VERSION ""

NS_ :

BS_:

BU_: PowertrainControlModule AtmosphericSensor SafetyRestraintSystem2 Aftertreatment_2_GasOutlet Aftertreatment_2_GasIntake DieselParticulateFilterControl Turbocharger SafetyRestraintSystem1 CabDisplay2 Aftertreatment_1_GasOutlet Aftertreatment_1_GasIntake OnBoardDataLogger OffBoardDiagnosticTool2 OffBoardDiagnosticTool1 FileServer ParkingBrakeController SeatController2 FanDriveController SteeringColumnUnit CommunicationUnitRadio CommunicationUnitSatellite CommunicationUnitCellular PropulsionBatteryCharger ChassisController2 ChassisController1 EngineValveControl AuxiliaryHeater2 AuxiliaryHeater1 ClutchUnit RampControl InformationSystem1 SuspensionSystemController2 OilSensor VehicleDynamicStability ExhaustEmissionController TransmissionDisplay2 TransmissionDisplay1 ClimateControl2 WaterPumpController RearAxleSteeringController LightingOperatorControl SeatController1 IgnitionController2 IgnitionController1 TirePressureController CabController2 CabController1 PneumaticSystemController SuspensionSystemController1 HydraulicPumpController EnduranceBrakingSystem RetarderExhaustEngine2 OnBoardDiagnosticUnit HeadwayController RetarderExhaustEngine1 CabDisplay1 ManagementComputer VirtualTerminal OffVehicleGateway PowerTakeOffFront HitchControl AuxiliaryValveControl BodyController TractorTrailerBridge1 StarterSystem ElectricalSystem VehicleSecurity VehicleNavigation AerodynamicControl ElectricalChargingSystem ClimateControl1 TripRecorder InstrumentCluster SuspensionDriveAxle2 SuspensionDriveAxle1 SuspensionSteerAxle SteeringController FuelSystem CruiseControl RetarderDriveline RetarderEngine BrakesDriveAxle2 BrakesDriveAxle1 BrakesSystemController BrakesSteerAxle AxleDrive2 AxleDrive1 AxleSteering PowerTakeOff ShiftConsoleSecondary ShiftConsolePrimary Transmission2 Transmission1 Engine2 Engine1

BO_ 2566711550 IVAC: 8 Vector__XXX
 SG_ IntkVlvActtnSystmOlPrss2SlndCtrl : 2|2@1+ (1,0) [0|3] "" Vector__XXX
 SG_ IntkVlvActtnSystmOlPrss1SlndCtrl : 0|2@1+ (1,0) [0|3] "" Vector__XXX

BO_ 2633832958 ILI: 8 Vector__XXX
 SG_ SpecialIgnitorLoop90Resistance : 1584|16@1+ (0.1,0) [0|6425.5] "ohm" Vector__XXX
 SG_ SpecialIgnitorLoop89Resistance : 1568|16@1+ (0.1,0) [0|6425.5] "ohm" Vector__XXX
 SG_ SpecialIgnitorLoop88Resistance : 1552|16@1+ (0.1,0) [0|6425.5] "ohm" Vector__XXX
 SG_ SpecialIgnitorLoop87Resistance : 1536|16@1+ (0.1,0) [0|6425.5] "ohm" Vector__XXX
 SG_ SpecialIgnitorLoop86Resistance : 1520|16@1+ (0.1,0) [0|6425.5] "ohm" Vector__XXX
 SG_ SpecialIgnitorLoop85Resistance : 1504|16@1+ (0.1,0) [0|6425.5] "ohm" Vector__XXX
 SG_ SpecialIgnitorLoop84Resistance : 1488|16@1+ (0.1,0) [0|6425.5] "ohm" Vector__XXX
 SG_ SpecialIgnitorLoop83Resistance : 1472|16@1+ (0.1,0) [0|6425.5] "ohm" Vector__XXX
 SG_ SpecialIgnitorLoop82Resistance : 1456|16@1+ (0.1,0) [0|6425.5] "ohm" Vector__XXX
 SG_ SpecialIgnitorLoop81Resistance : 1440|16@1+ (0.1,0) [0|6425.5] "ohm" Vector__XXX
 SG_ SpecialIgnitorLoop80Resistance : 1424|16@1+ (0.1,0) [0|6425.5] "ohm" Vector__XXX
 SG_ SpecialIgnitorLoop79Resistance : 1408|16@1+ (0.1,0) [0|6425.5] "ohm" Vector__XXX
 SG_ SpecialIgnitorLoop78Resistance : 1392|16@1+ (0.1,0) [0|6425.5] "ohm" Vector__XXX
 SG_ SpecialIgnitorLoop77Resistance : 1376|16@1+ (0.1,0) [0|6425.5] "ohm" Vector__XXX
 SG_ SpecialIgnitorLoop76Resistance : 1360|16@1+ (0.1,0) [0|6425.5] "ohm" Vector__XXX
 SG_ SpecialIgnitorLoop75Resistance : 1344|16@1+ (0.1,0) [0|6425.5] "ohm" Vector__XXX
 SG_ SpecialIgnitorLoop74Resistance : 1328|16@1+ (0.1,0) [0|6425.5] "ohm" Vector__XXX
 SG_ SpecialIgnitorLoop73Resistance : 1312|16@1+ (0.1,0) [0|6425.5] "ohm" Vector__XXX
 SG_ SpecialIgnitorLoop72Resistance : 1296|16@1+ (0.1,0) [0|6425.5] "ohm" Vector__XXX
 SG_ SpecialIgnitorLoop71Resistance : 1280|16@1+ (0.1,0) [0|6425.5] "ohm" Vector__XXX
 SG_ SpecialIgnitorLoop70Resistance : 1264|16@1+ (0.1,0) [0|6425.5] "ohm" Vector__XXX
 SG_ SpecialIgnitorLoop69Resistance : 1248|16@1+ (0.1,0) [0|6425.5] "ohm" Vector__XXX
 SG_ SpecialIgnitorLoop68Resistance : 1232|16@1+ (0.1,0) [0|6425.5] "ohm" Vector__XXX
 SG_ SpecialIgnitorLoop67Resistance : 1216|16@1+ (0.1,0) [0|6425.5] "ohm" Vector__XXX
 SG_ SpecialIgnitorLoop66Resistance : 1200|16@1+ (0.1,0) [0|6425.5] "ohm" Vector__XXX
 SG_ SpecialIgnitorLoop65Resistance : 1184|16@1+ (0.1,0) [0|6425.5] "ohm" Vector__XXX
 SG_ SpecialIgnitorLoop64Resistance : 1168|16@1+ (0.1,0) [0|6425.5] "ohm" Vector__XXX
 SG_ SpecialIgnitorLoop63Resistance : 1152|16@1+ (0.1,0) [0|6425.5] "ohm" Vector__XXX
 SG_ SpecialIgnitorLoop62Resistance : 1136|16@1+ (0.1,0) [0|6425.5] "ohm" Vector__XXX
 SG_ SpecialIgnitorLoop61Resistance : 1120|16@1+ (0.1,0) [0|6425.5] "ohm" Vector__XXX
 SG_ SpecialIgnitorLoop60Resistance : 1104|16@1+ (0.1,0) [0|6425.5] "ohm" Vector__XXX
 SG_ SpecialIgnitorLoop59Resistance : 1088|16@1+ (0.1,0) [0|6425.5] "ohm" Vector__XXX
 SG_ SpecialIgnitorLoop58Resistance : 1072|16@1+ (0.1,0) [0|6425.5] "ohm" Vector__XXX
 SG_ SpecialIgnitorLoop57Resistance : 1056|16@1+ (0.1,0) [0|6425.5] "ohm" Vector__XXX
 SG_ SpecialIgnitorLoop56Resistance : 1040|16@1+ (0.1,0) [0|6425.5] "ohm" Vector__XXX
 SG_ SpecialIgnitorLoop55Resistance : 1024|16@1+ (0.1,0) [0|6425.5] "ohm" Vector__XXX
 SG_ SpecialIgnitorLoop54Resistance : 1008|16@1+ (0.1,0) [0|6425.5] "ohm" Vector__XXX
 SG_ SpecialIgnitorLoop53Resistance : 992|16@1+ (0.1,0) [0|6425.5] "ohm" Vector__XXX
 SG_ SpecialIgnitorLoop52Resistance : 976|16@1+ (0.1,0) [0|6425.5] "ohm" Vector__XXX
 SG_ SpecialIgnitorLoop51Resistance : 960|16@1+ (0.1,0) [0|6425.5] "ohm" Vector__XXX
 SG_ SpecialIgnitorLoop50Resistance : 944|16@1+ (0.1,0) [0|6425.5] "ohm" Vector__XXX
 SG_ SpecialIgnitorLoop49Resistance : 928|16@1+ (0.1,0) [0|6425.5] "ohm" Vector__XXX
 SG_ SpecialIgnitorLoop48Resistance : 912|16@1+ (0.1,0) [0|6425.5] "ohm" Vector__XXX
 SG_ SpecialIgnitorLoop47Resistance : 896|16@1+ (0.1,0) [0|6425.5] "ohm" Vector__XXX
 SG_ SpecialIgnitorLoop46Resistance : 880|16@1+ (0.1,0) [0|6425.5] "ohm" Vector__XXX
 SG_ SpecialIgnitorLoop45Resistance : 864|16@1+ (0.1,0) [0|6425.5] "ohm" Vector__XXX
 SG_ SpecialIgnitorLoop44Resistance : 848|16@1+ (0.1,0) [0|6425.5] "ohm" Vector__XXX
 SG_ SpecialIgnitorLoop43Resistance : 832|16@1+ (0.1,0) [0|6425.5] "ohm" Vector__XXX
 SG_ SpecialIgnitorLoop42Resistance : 816|16@1+ (0.1,0) [0|6425.5] "ohm" Vector__XXX
 SG_ SpecialIgnitorLoop41Resistance : 800|16@1+ (0.1,0) [0|6425.5] "ohm" Vector__XXX
 SG_ SpecialIgnitorLoop40Resistance : 784|16@1+ (0.1,0) [0|6425.5] "ohm" Vector__XXX
 SG_ SpecialIgnitorLoop39Resistance : 768|16@1+ (0.1,0) [0|6425.5] "ohm" Vector__XXX
 SG_ SpecialIgnitorLoop38Resistance : 752|16@1+ (0.1,0) [0|6425.5] "ohm" Vector__XXX
 SG_ SpecialIgnitorLoop37Resistance : 736|16@1+ (0.1,0) [0|6425.5] "ohm" Vector__XXX
 SG_ SpecialIgnitorLoop36Resistance : 720|16@1+ (0.1,0) [0|6425.5] "ohm" Vector__XXX
 SG_ SpecialIgnitorLoop35Resistance : 704|16@1+ (0.1,0) [0|6425.5] "ohm" Vector__XXX
 SG_ SpecialIgnitorLoop34Resistance : 688|16@1+ (0.1,0) [0|6425.5] "ohm" Vector__XXX
 SG_ SpecialIgnitorLoop33Resistance : 672|16@1+ (0.1,0) [0|6425.5] "ohm" Vector__XXX
 SG_ SpecialIgnitorLoop32Resistance : 656|16@1+ (0.1,0) [0|6425.5] "ohm" Vector__XXX
 SG_ SpecialIgnitorLoop31Resistance : 640|16@1+ (0.1,0) [0|6425.5] "ohm" Vector__XXX
 SG_ SpecialIgnitorLoop30Resistance : 624|16@1+ (0.1,0) [0|6425.5] "ohm" Vector__XXX
 SG_ SpecialIgnitorLoop29Resistance : 608|16@1+ (0.1,0) [0|6425.5] "ohm" Vector__XXX
 SG_ SpecialIgnitorLoop28Resistance : 592|16@1+ (0.1,0) [0|6425.5] "ohm" Vector__XXX
 SG_ SpecialIgnitorLoop27Resistance : 576|16@1+ (0.1,0) [0|6425.5] "ohm" Vector__XXX
 SG_ SpecialIgnitorLoop26Resistance : 560|16@1+ (0.1,0) [0|6425.5] "ohm" Vector__XXX
 SG_ SpecialIgnitorLoop25Resistance : 544|16@1+ (0.1,0) [0|6425.5] "ohm" Vector__XXX
 SG_ SpecialIgnitorLoop24Resistance : 528|16@1+ (0.1,0) [0|6425.5] "ohm" Vector__XXX
 SG_ SpecialIgnitorLoop23Resistance : 512|16@1+ (0.1,0) [0|6425.5] "ohm" Vector__XXX
 SG_ SpecialIgnitorLoop22Resistance : 496|16@1+ (0.1,0) [0|6425.5] "ohm" Vector__XXX
 SG_ SpecialIgnitorLoop21Resistance : 480|16@1+ (0.1,0) [0|6425.5] "ohm" Vector__XXX
 SG_ SpecialIgnitorLoop20Resistance : 464|16@1+ (0.1,0) [0|6425.5] "ohm" Vector__XXX
 SG_ SpecialIgnitorLoop19Resistance : 448|16@1+ (0.1,0) [0|6425.5] "ohm" Vector__XXX
 SG_ SpecialIgnitorLoop18Resistance : 432|16@1+ (0.1,0) [0|6425.5] "ohm" Vector__XXX
 SG_ SpecialIgnitorLoop17Resistance : 416|16@1+ (0.1,0) [0|6425.5] "ohm" Vector__XXX
 SG_ SpecialIgnitorLoop16Resistance : 400|16@1+ (0.1,0) [0|6425.5] "ohm" Vector__XXX
 SG_ SpecialIgnitorLoop15Resistance : 384|16@1+ (0.1,0) [0|6425.5] "ohm" Vector__XXX
 SG_ SpecialIgnitorLoop14Resistance : 368|16@1+ (0.1,0) [0|6425.5] "ohm" Vector__XXX
 SG_ SpecialIgnitorLoop13Resistance : 352|16@1+ (0.1,0) [0|6425.5] "ohm" Vector__XXX
 SG_ SpecialIgnitorLoop12Resistance : 336|16@1+ (0.1,0) [0|6425.5] "ohm" Vector__XXX
 SG_ SpecialIgnitorLoop11Resistance : 320|16@1+ (0.1,0) [0|6425.5] "ohm" Vector__XXX
 SG_ SpecialIgnitorLoop10Resistance : 304|16@1+ (0.1,0) [0|6425.5] "ohm" Vector__XXX
 SG_ SpecialIgnitorLoop9Resistance : 288|16@1+ (0.1,0) [0|6425.5] "ohm" Vector__XXX
 SG_ SpecialIgnitorLoop8Resistance : 272|16@1+ (0.1,0) [0|6425.5] "ohm" Vector__XXX
 SG_ SpecialIgnitorLoop7Resistance : 256|16@1+ (0.1,0) [0|6425.5] "ohm" Vector__XXX
 SG_ SpecialIgnitorLoop6Resistance : 240|16@1+ (0.1,0) [0|6425.5] "ohm" Vector__XXX
 SG_ SpecialIgnitorLoop5Resistance : 224|16@1+ (0.1,0) [0|6425.5] "ohm" Vector__XXX
 SG_ SpecialIgnitorLoop4Resistance : 208|16@1+ (0.1,0) [0|6425.5] "ohm" Vector__XXX
 SG_ SpecialIgnitorLoop3Resistance : 192|16@1+ (0.1,0) [0|6425.5] "ohm" Vector__XXX
 SG_ SpecialIgnitorLoop2Resistance : 176|16@1+ (0.1,0) [0|6425.5] "ohm" Vector__XXX
 SG_ SpecialIgnitorLoop1Resistance : 160|16@1+ (0.1,0) [0|6425.5] "ohm" Vector__XXX
 SG_ SdBagIgnitorLoop2RightResistance : 144|16@1+ (0.1,0) [0|6425.5] "ohm" Vector__XXX
 SG_ SdBagIgnitorLoop1RightResistance : 128|16@1+ (0.1,0) [0|6425.5] "ohm" Vector__XXX
 SG_ SdeBagIgnitorLoop2LeftResistance : 112|16@1+ (0.1,0) [0|6425.5] "ohm" Vector__XXX
 SG_ SdeBagIgnitorLoop1LeftResistance : 96|16@1+ (0.1,0) [0|6425.5] "ohm" Vector__XXX
 SG_ PssngrBltTnsnrIgntrLopResistance : 80|16@1+ (0.1,0) [0|6425.5] "ohm" Vector__XXX
 SG_ DrvrBltTnsnrIgntorLoopResistance : 64|16@1+ (0.1,0) [0|6425.5] "ohm" Vector__XXX
 SG_ PssngrArbgIgntrLp2ndStgRsistance : 48|16@1+ (0.1,0) [0|6425.5] "ohm" Vector__XXX
 SG_ DrvrArbgIgntrLp2ndStgeResistance : 32|16@1+ (0.1,0) [0|6425.5] "ohm" Vector__XXX
 SG_ PssngrArbgIgntrLp1stStgRsistance : 16|16@1+ (0.1,0) [0|6425.5] "ohm" Vector__XXX
 SG_ DrvrArbgIgntrLp1stStgeResistance : 0|16@1+ (0.1,0) [0|6425.5] "ohm" Vector__XXX

BO_ 2566719998 HRLFC: 8 Vector__XXX
 SG_ HighResolutionEngTotalFuelUsed : 32|32@1+ (0.001,0) [0|4211081.215] "L" Vector__XXX
 SG_ HighResolutionEngTripFuel : 0|32@1+ (0.001,0) [0|4211081.215] "L" Vector__XXX

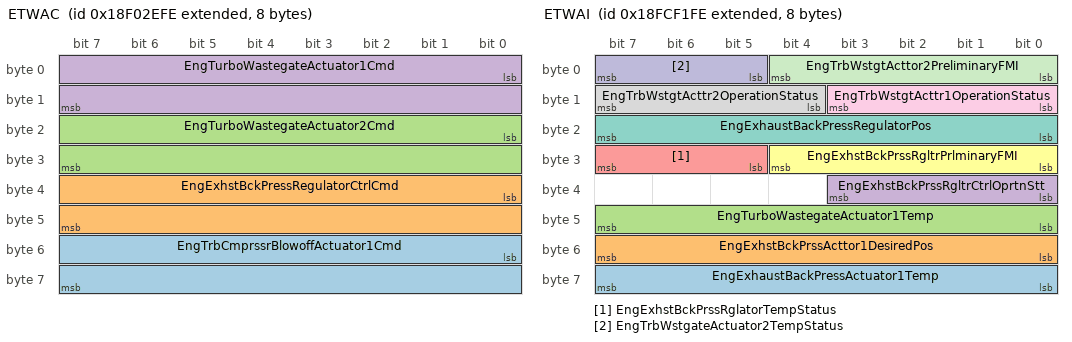
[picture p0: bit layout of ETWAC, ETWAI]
BO_ 2565877502 ETWAC: 8 Vector__XXX
 SG_ EngTrbCmprssrBlowoffActuator1Cmd : 48|16@1+ (0.0025,0) [0|100] "%" Vector__XXX
 SG_ EngExhstBckPressRegulatorCtrlCmd : 32|16@1+ (0.0025,0) [0|100] "%" Vector__XXX
 SG_ EngTurboWastegateActuator2Cmd : 16|16@1+ (0.0025,0) [0|160.6375] "%" Vector__XXX
 SG_ EngTurboWastegateActuator1Cmd : 0|16@1+ (0.0025,0) [0|160.6375] "%" Vector__XXX

BO_ 2566713854 ETWAI: 8 Vector__XXX
 SG_ EngExhaustBackPressActuator1Temp : 56|8@1+ (1,-40) [-40|210] "°C" Vector__XXX
 SG_ EngExhstBckPrssActtor1DesiredPos : 48|8@1+ (0.4,0) [0|100] "%" Vector__XXX
 SG_ EngTurboWastegateActuator1Temp : 40|8@1+ (1,-40) [-40|210] "°C" Vector__XXX
 SG_ EngExhstBckPrssRgltrCtrlOprtnStt : 32|4@1+ (1,0) [0|15] "" Vector__XXX
 SG_ EngExhstBckPrssRglatorTempStatus : 29|3@1+ (1,0) [0|7] "" Vector__XXX
 SG_ EngExhstBckPrssRgltrPrlminaryFMI : 24|5@1+ (1,0) [0|31] "" Vector__XXX
 SG_ EngExhaustBackPressRegulatorPos : 16|8@1+ (0.4,0) [0|100] "%" Vector__XXX
 SG_ EngTrbWstgtActtr2OperationStatus : 12|4@1+ (1,0) [0|15] "" Vector__XXX
 SG_ EngTrbWstgtActtr1OperationStatus : 8|4@1+ (1,0) [0|15] "" Vector__XXX
 SG_ EngTrbWstgateActuator2TempStatus : 5|3@1+ (1,0) [0|7] "" Vector__XXX
 SG_ EngTrbWstgtActtor2PreliminaryFMI : 0|5@1+ (1,0) [0|31] "" Vector__XXX

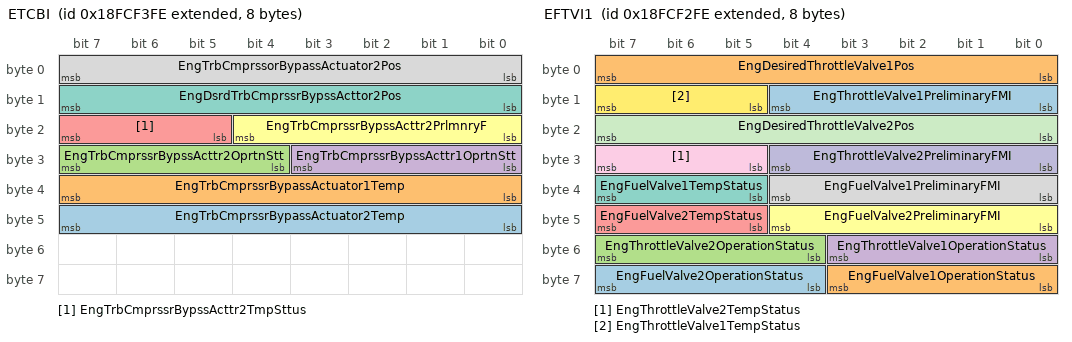
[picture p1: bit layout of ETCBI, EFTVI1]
BO_ 2566714366 ETCBI: 8 Vector__XXX
 SG_ EngTrbCmprssrBypassActuator2Temp : 40|8@1+ (1,-40) [-40|210] "°C" Vector__XXX
 SG_ EngTrbCmprssrBypassActuator1Temp : 32|8@1+ (1,-40) [-40|210] "°C" Vector__XXX
 SG_ EngTrbCmprssrBypssActtr2OprtnStt : 28|4@1+ (1,0) [0|15] "" Vector__XXX
 SG_ EngTrbCmprssrBypssActtr1OprtnStt : 24|4@1+ (1,0) [0|15] "" Vector__XXX
 SG_ EngTrbCmprssrBypssActtr2TmpSttus : 21|3@1+ (1,0) [0|7] "" Vector__XXX
 SG_ EngTrbCmprssrBypssActtr2PrlmnryF : 16|5@1+ (1,0) [0|31] "" Vector__XXX
 SG_ EngDsrdTrbCmprssrBypssActtor2Pos : 8|8@1+ (0.4,0) [0|100] "%" Vector__XXX
 SG_ EngTrbCmprssorBypassActuator2Pos : 0|8@1+ (0.4,0) [0|100] "%" Vector__XXX

BO_ 2566714110 EFTVI1: 8 Vector__XXX
 SG_ EngFuelValve2OperationStatus : 60|4@1+ (1,0) [0|15] "" Vector__XXX
 SG_ EngFuelValve1OperationStatus : 56|4@1+ (1,0) [0|15] "" Vector__XXX
 SG_ EngThrottleValve2OperationStatus : 52|4@1+ (1,0) [0|15] "" Vector__XXX
 SG_ EngThrottleValve1OperationStatus : 48|4@1+ (1,0) [0|15] "" Vector__XXX
 SG_ EngFuelValve2TempStatus : 45|3@1+ (1,0) [0|7] "" Vector__XXX
 SG_ EngFuelValve2PreliminaryFMI : 40|5@1+ (1,0) [0|31] "" Vector__XXX
 SG_ EngFuelValve1TempStatus : 37|3@1+ (1,0) [0|7] "" Vector__XXX
 SG_ EngFuelValve1PreliminaryFMI : 32|5@1+ (1,0) [0|31] "" Vector__XXX
 SG_ EngThrottleValve2TempStatus : 29|3@1+ (1,0) [0|7] "" Vector__XXX
 SG_ EngThrottleValve2PreliminaryFMI : 24|5@1+ (1,0) [0|31] "" Vector__XXX
 SG_ EngDesiredThrottleValve2Pos : 16|8@1+ (0.4,0) [0|100] "%" Vector__XXX
 SG_ EngThrottleValve1TempStatus : 13|3@1+ (1,0) [0|7] "" Vector__XXX
 SG_ EngThrottleValve1PreliminaryFMI : 8|5@1+ (1,0) [0|31] "" Vector__XXX
 SG_ EngDesiredThrottleValve1Pos : 0|8@1+ (0.4,0) [0|100] "%" Vector__XXX

BO_ 2566717438 ET5: 8 Vector__XXX
 SG_ EngExhstGsRcrcltn2MxerIntakeTemp : 16|16@1+ (0.03125,-273) [-273|1734.96875] "°C" Vector__XXX
 SG_ EngExhaustGasRecirculation2Temp : 0|16@1+ (0.03125,-273) [-273|1734.96875] "°C" Vector__XXX

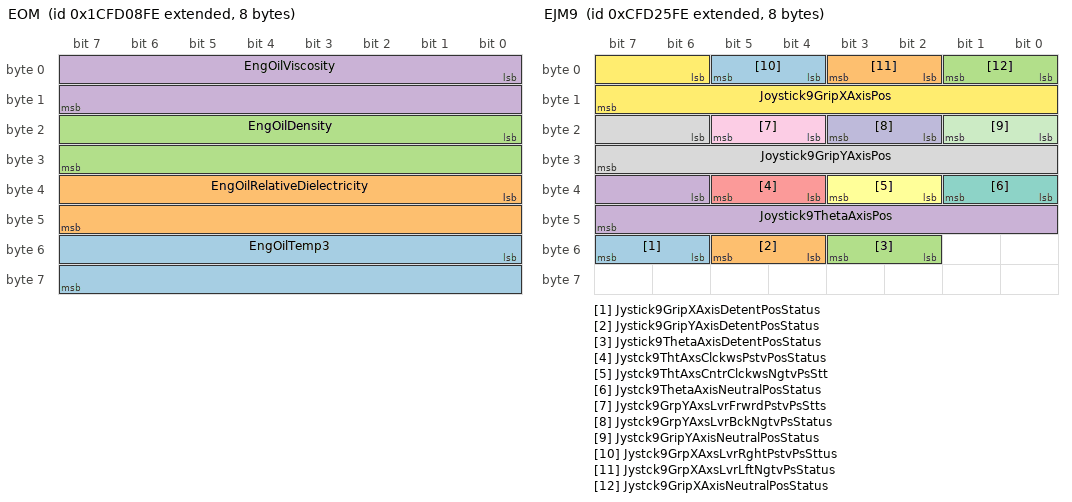
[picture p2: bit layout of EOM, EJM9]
BO_ 2633828606 EOM: 8 Vector__XXX
 SG_ EngOilTemp3 : 48|16@1+ (0.03125,-273) [-273|1734.96875] "°C" Vector__XXX
 SG_ EngOilRelativeDielectricity : 32|16@1+ (0.0001220703125,0) [0|7.844] "" Vector__XXX
 SG_ EngOilDensity : 16|16@1+ (3.052E-005,0) [0|1.961] "g/cc" Vector__XXX
 SG_ EngOilViscosity : 0|16@1+ (0.015625,0) [0|1003.984375] "Cp" Vector__XXX

BO_ 2499607550 EMAP: 8 Vector__XXX
 SG_ EngExhstMnfldBnk2FlwBlncVlvActtr : 16|16@1+ (0.0025,0) [0|160.6375] "%" Vector__XXX
 SG_ EngExhstMnfldBnk1FlwBlncVlvActtr : 0|16@1+ (0.0025,0) [0|160.6375] "%" Vector__XXX

BO_ 2633825534 EMAC: 8 Vector__XXX
 SG_ EngExhstMnfldBnk2FlwBlncVlvActtr : 16|16@1+ (0.0025,0) [0|160.6375] "%" Vector__XXX
 SG_ EngExhstMnfldBnk1FlwBlncVlvActtr : 0|16@1+ (0.0025,0) [0|160.6375] "%" Vector__XXX

BO_ 2365400574 EJM9: 8 Vector__XXX
 SG_ Jystick9GripXAxisDetentPosStatus : 54|2@1+ (1,0) [0|3] "" Vector__XXX
 SG_ Jystick9GripYAxisDetentPosStatus : 52|2@1+ (1,0) [0|3] "" Vector__XXX
 SG_ Jystick9ThetaAxisDetentPosStatus : 50|2@1+ (1,0) [0|3] "" Vector__XXX
 SG_ Joystick9ThetaAxisPos : 38|10@1+ (0.1,0) [0|102] "%" Vector__XXX
 SG_ Jystck9ThtAxsClckwsPstvPosStatus : 36|2@1+ (1,0) [0|3] "" Vector__XXX
 SG_ Jystck9ThtAxsCntrClckwsNgtvPsStt : 34|2@1+ (1,0) [0|3] "" Vector__XXX
 SG_ Jystck9ThetaAxisNeutralPosStatus : 32|2@1+ (1,0) [0|3] "" Vector__XXX
 SG_ Joystick9GripYAxisPos : 22|10@1+ (0.1,0) [0|102] "%" Vector__XXX
 SG_ Jystck9GrpYAxsLvrFrwrdPstvPsStts : 20|2@1+ (1,0) [0|3] "" Vector__XXX
 SG_ Jystck9GrpYAxsLvrBckNgtvPsStatus : 18|2@1+ (1,0) [0|3] "" Vector__XXX
 SG_ Jystck9GripYAxisNeutralPosStatus : 16|2@1+ (1,0) [0|3] "" Vector__XXX
 SG_ Joystick9GripXAxisPos : 6|10@1+ (0.1,0) [0|102] "%" Vector__XXX
 SG_ Jystck9GrpXAxsLvrRghtPstvPsSttus : 4|2@1+ (1,0) [0|3] "" Vector__XXX
 SG_ Jystck9GrpXAxsLvrLftNgtvPsStatus : 2|2@1+ (1,0) [0|3] "" Vector__XXX
 SG_ Jystck9GripXAxisNeutralPosStatus : 0|2@1+ (1,0) [0|3] "" Vector__XXX

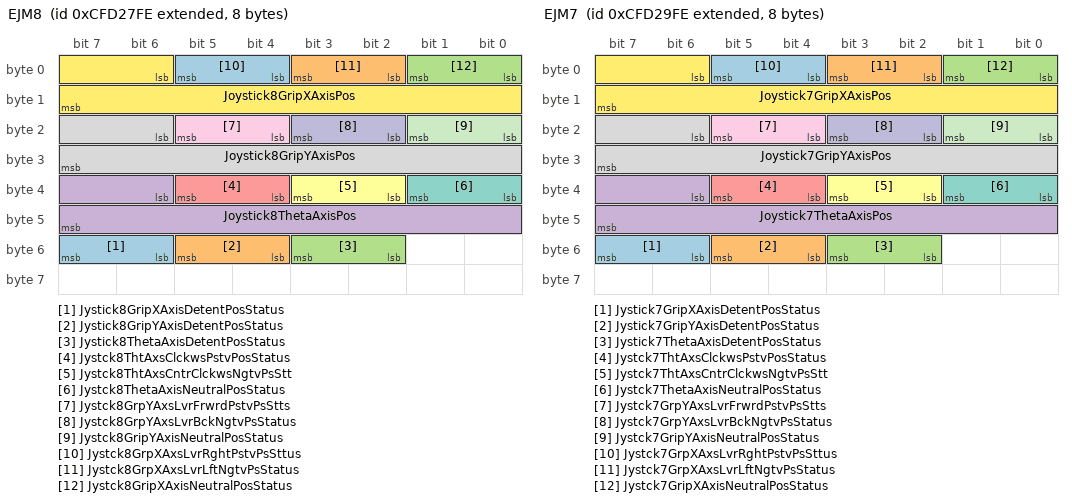
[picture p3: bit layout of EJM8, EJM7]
BO_ 2365401086 EJM8: 8 Vector__XXX
 SG_ Jystick8GripXAxisDetentPosStatus : 54|2@1+ (1,0) [0|3] "" Vector__XXX
 SG_ Jystick8GripYAxisDetentPosStatus : 52|2@1+ (1,0) [0|3] "" Vector__XXX
 SG_ Jystick8ThetaAxisDetentPosStatus : 50|2@1+ (1,0) [0|3] "" Vector__XXX
 SG_ Joystick8ThetaAxisPos : 38|10@1+ (0.1,0) [0|102] "%" Vector__XXX
 SG_ Jystck8ThtAxsClckwsPstvPosStatus : 36|2@1+ (1,0) [0|3] "" Vector__XXX
 SG_ Jystck8ThtAxsCntrClckwsNgtvPsStt : 34|2@1+ (1,0) [0|3] "" Vector__XXX
 SG_ Jystck8ThetaAxisNeutralPosStatus : 32|2@1+ (1,0) [0|3] "" Vector__XXX
 SG_ Joystick8GripYAxisPos : 22|10@1+ (0.1,0) [0|102] "%" Vector__XXX
 SG_ Jystck8GrpYAxsLvrFrwrdPstvPsStts : 20|2@1+ (1,0) [0|3] "" Vector__XXX
 SG_ Jystck8GrpYAxsLvrBckNgtvPsStatus : 18|2@1+ (1,0) [0|3] "" Vector__XXX
 SG_ Jystck8GripYAxisNeutralPosStatus : 16|2@1+ (1,0) [0|3] "" Vector__XXX
 SG_ Joystick8GripXAxisPos : 6|10@1+ (0.1,0) [0|102] "%" Vector__XXX
 SG_ Jystck8GrpXAxsLvrRghtPstvPsSttus : 4|2@1+ (1,0) [0|3] "" Vector__XXX
 SG_ Jystck8GrpXAxsLvrLftNgtvPsStatus : 2|2@1+ (1,0) [0|3] "" Vector__XXX
 SG_ Jystck8GripXAxisNeutralPosStatus : 0|2@1+ (1,0) [0|3] "" Vector__XXX

BO_ 2365401598 EJM7: 8 Vector__XXX
 SG_ Jystick7GripXAxisDetentPosStatus : 54|2@1+ (1,0) [0|3] "" Vector__XXX
 SG_ Jystick7GripYAxisDetentPosStatus : 52|2@1+ (1,0) [0|3] "" Vector__XXX
 SG_ Jystick7ThetaAxisDetentPosStatus : 50|2@1+ (1,0) [0|3] "" Vector__XXX
 SG_ Joystick7ThetaAxisPos : 38|10@1+ (0.1,0) [0|102] "%" Vector__XXX
 SG_ Jystck7ThtAxsClckwsPstvPosStatus : 36|2@1+ (1,0) [0|3] "" Vector__XXX
 SG_ Jystck7ThtAxsCntrClckwsNgtvPsStt : 34|2@1+ (1,0) [0|3] "" Vector__XXX
 SG_ Jystck7ThetaAxisNeutralPosStatus : 32|2@1+ (1,0) [0|3] "" Vector__XXX
 SG_ Joystick7GripYAxisPos : 22|10@1+ (0.1,0) [0|102] "%" Vector__XXX
 SG_ Jystck7GrpYAxsLvrFrwrdPstvPsStts : 20|2@1+ (1,0) [0|3] "" Vector__XXX
 SG_ Jystck7GrpYAxsLvrBckNgtvPsStatus : 18|2@1+ (1,0) [0|3] "" Vector__XXX
 SG_ Jystck7GripYAxisNeutralPosStatus : 16|2@1+ (1,0) [0|3] "" Vector__XXX
 SG_ Joystick7GripXAxisPos : 6|10@1+ (0.1,0) [0|102] "%" Vector__XXX
 SG_ Jystck7GrpXAxsLvrRghtPstvPsSttus : 4|2@1+ (1,0) [0|3] "" Vector__XXX
 SG_ Jystck7GrpXAxsLvrLftNgtvPsStatus : 2|2@1+ (1,0) [0|3] "" Vector__XXX
 SG_ Jystck7GripXAxisNeutralPosStatus : 0|2@1+ (1,0) [0|3] "" Vector__XXX

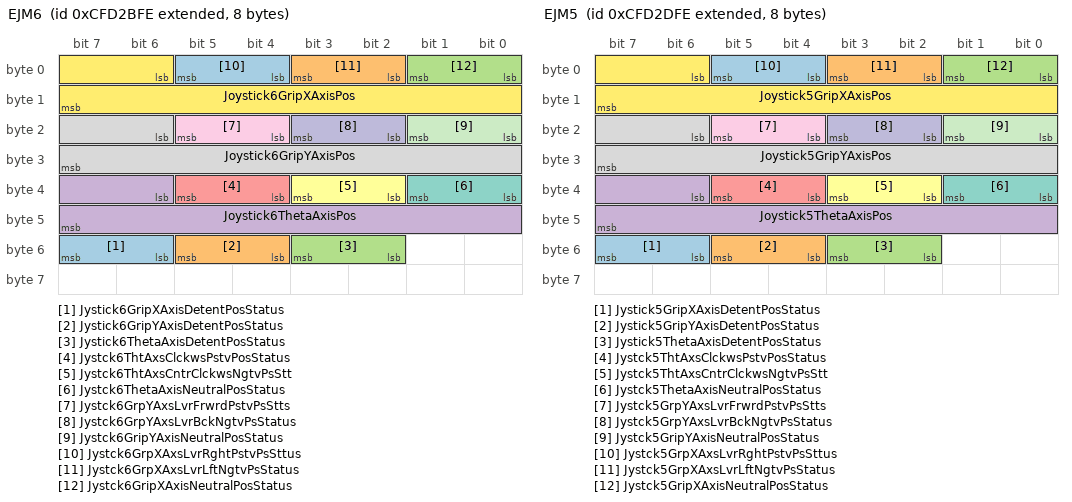
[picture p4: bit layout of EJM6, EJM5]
BO_ 2365402110 EJM6: 8 Vector__XXX
 SG_ Jystick6GripXAxisDetentPosStatus : 54|2@1+ (1,0) [0|3] "" Vector__XXX
 SG_ Jystick6GripYAxisDetentPosStatus : 52|2@1+ (1,0) [0|3] "" Vector__XXX
 SG_ Jystick6ThetaAxisDetentPosStatus : 50|2@1+ (1,0) [0|3] "" Vector__XXX
 SG_ Joystick6ThetaAxisPos : 38|10@1+ (0.1,0) [0|102] "%" Vector__XXX
 SG_ Jystck6ThtAxsClckwsPstvPosStatus : 36|2@1+ (1,0) [0|3] "" Vector__XXX
 SG_ Jystck6ThtAxsCntrClckwsNgtvPsStt : 34|2@1+ (1,0) [0|3] "" Vector__XXX
 SG_ Jystck6ThetaAxisNeutralPosStatus : 32|2@1+ (1,0) [0|3] "" Vector__XXX
 SG_ Joystick6GripYAxisPos : 22|10@1+ (0.1,0) [0|102] "%" Vector__XXX
 SG_ Jystck6GrpYAxsLvrFrwrdPstvPsStts : 20|2@1+ (1,0) [0|3] "" Vector__XXX
 SG_ Jystck6GrpYAxsLvrBckNgtvPsStatus : 18|2@1+ (1,0) [0|3] "" Vector__XXX
 SG_ Jystck6GripYAxisNeutralPosStatus : 16|2@1+ (1,0) [0|3] "" Vector__XXX
 SG_ Joystick6GripXAxisPos : 6|10@1+ (0.1,0) [0|102] "%" Vector__XXX
 SG_ Jystck6GrpXAxsLvrRghtPstvPsSttus : 4|2@1+ (1,0) [0|3] "" Vector__XXX
 SG_ Jystck6GrpXAxsLvrLftNgtvPsStatus : 2|2@1+ (1,0) [0|3] "" Vector__XXX
 SG_ Jystck6GripXAxisNeutralPosStatus : 0|2@1+ (1,0) [0|3] "" Vector__XXX

BO_ 2365402622 EJM5: 8 Vector__XXX
 SG_ Jystick5GripXAxisDetentPosStatus : 54|2@1+ (1,0) [0|3] "" Vector__XXX
 SG_ Jystick5GripYAxisDetentPosStatus : 52|2@1+ (1,0) [0|3] "" Vector__XXX
 SG_ Jystick5ThetaAxisDetentPosStatus : 50|2@1+ (1,0) [0|3] "" Vector__XXX
 SG_ Joystick5ThetaAxisPos : 38|10@1+ (0.1,0) [0|102] "%" Vector__XXX
 SG_ Jystck5ThtAxsClckwsPstvPosStatus : 36|2@1+ (1,0) [0|3] "" Vector__XXX
 SG_ Jystck5ThtAxsCntrClckwsNgtvPsStt : 34|2@1+ (1,0) [0|3] "" Vector__XXX
 SG_ Jystck5ThetaAxisNeutralPosStatus : 32|2@1+ (1,0) [0|3] "" Vector__XXX
 SG_ Joystick5GripYAxisPos : 22|10@1+ (0.1,0) [0|102] "%" Vector__XXX
 SG_ Jystck5GrpYAxsLvrFrwrdPstvPsStts : 20|2@1+ (1,0) [0|3] "" Vector__XXX
 SG_ Jystck5GrpYAxsLvrBckNgtvPsStatus : 18|2@1+ (1,0) [0|3] "" Vector__XXX
 SG_ Jystck5GripYAxisNeutralPosStatus : 16|2@1+ (1,0) [0|3] "" Vector__XXX
 SG_ Joystick5GripXAxisPos : 6|10@1+ (0.1,0) [0|102] "%" Vector__XXX
 SG_ Jystck5GrpXAxsLvrRghtPstvPsSttus : 4|2@1+ (1,0) [0|3] "" Vector__XXX
 SG_ Jystck5GrpXAxsLvrLftNgtvPsStatus : 2|2@1+ (1,0) [0|3] "" Vector__XXX
 SG_ Jystck5GripXAxisNeutralPosStatus : 0|2@1+ (1,0) [0|3] "" Vector__XXX

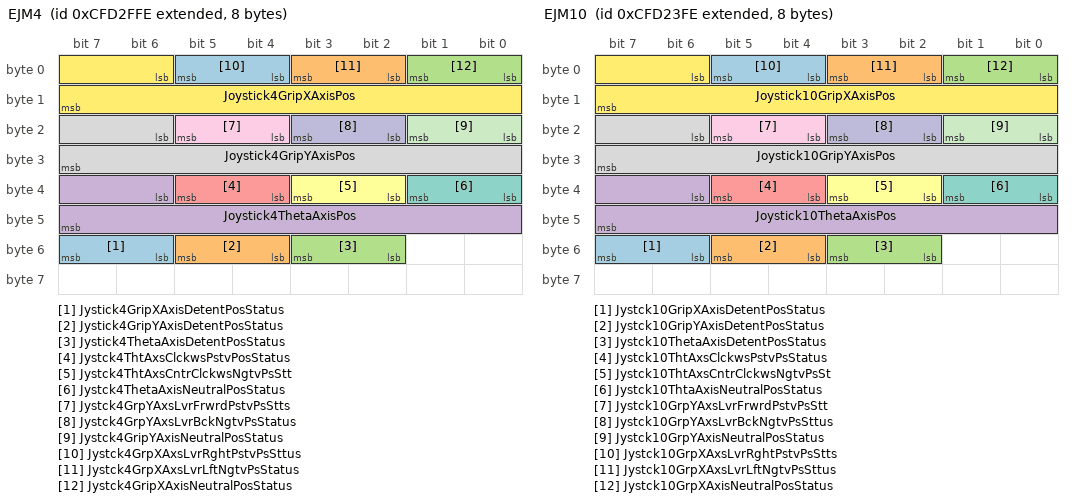
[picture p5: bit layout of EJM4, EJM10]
BO_ 2365403134 EJM4: 8 Vector__XXX
 SG_ Jystick4GripXAxisDetentPosStatus : 54|2@1+ (1,0) [0|3] "" Vector__XXX
 SG_ Jystick4GripYAxisDetentPosStatus : 52|2@1+ (1,0) [0|3] "" Vector__XXX
 SG_ Jystick4ThetaAxisDetentPosStatus : 50|2@1+ (1,0) [0|3] "" Vector__XXX
 SG_ Joystick4ThetaAxisPos : 38|10@1+ (0.1,0) [0|102] "%" Vector__XXX
 SG_ Jystck4ThtAxsClckwsPstvPosStatus : 36|2@1+ (1,0) [0|3] "" Vector__XXX
 SG_ Jystck4ThtAxsCntrClckwsNgtvPsStt : 34|2@1+ (1,0) [0|3] "" Vector__XXX
 SG_ Jystck4ThetaAxisNeutralPosStatus : 32|2@1+ (1,0) [0|3] "" Vector__XXX
 SG_ Joystick4GripYAxisPos : 22|10@1+ (0.1,0) [0|102] "%" Vector__XXX
 SG_ Jystck4GrpYAxsLvrFrwrdPstvPsStts : 20|2@1+ (1,0) [0|3] "" Vector__XXX
 SG_ Jystck4GrpYAxsLvrBckNgtvPsStatus : 18|2@1+ (1,0) [0|3] "" Vector__XXX
 SG_ Jystck4GripYAxisNeutralPosStatus : 16|2@1+ (1,0) [0|3] "" Vector__XXX
 SG_ Joystick4GripXAxisPos : 6|10@1+ (0.1,0) [0|102] "%" Vector__XXX
 SG_ Jystck4GrpXAxsLvrRghtPstvPsSttus : 4|2@1+ (1,0) [0|3] "" Vector__XXX
 SG_ Jystck4GrpXAxsLvrLftNgtvPsStatus : 2|2@1+ (1,0) [0|3] "" Vector__XXX
 SG_ Jystck4GripXAxisNeutralPosStatus : 0|2@1+ (1,0) [0|3] "" Vector__XXX

BO_ 2365400062 EJM10: 8 Vector__XXX
 SG_ Jystck10GripXAxisDetentPosStatus : 54|2@1+ (1,0) [0|3] "" Vector__XXX
 SG_ Jystck10GripYAxisDetentPosStatus : 52|2@1+ (1,0) [0|3] "" Vector__XXX
 SG_ Jystck10ThetaAxisDetentPosStatus : 50|2@1+ (1,0) [0|3] "" Vector__XXX
 SG_ Joystick10ThetaAxisPos : 38|10@1+ (0.1,0) [0|102] "%" Vector__XXX
 SG_ Jystck10ThtAxsClckwsPstvPsStatus : 36|2@1+ (1,0) [0|3] "" Vector__XXX
 SG_ Jystck10ThtAxsCntrClckwsNgtvPsSt : 34|2@1+ (1,0) [0|3] "" Vector__XXX
 SG_ Jystck10ThtaAxisNeutralPosStatus : 32|2@1+ (1,0) [0|3] "" Vector__XXX
 SG_ Joystick10GripYAxisPos : 22|10@1+ (0.1,0) [0|102] "%" Vector__XXX
 SG_ Jystck10GrpYAxsLvrFrwrdPstvPsStt : 20|2@1+ (1,0) [0|3] "" Vector__XXX
 SG_ Jystck10GrpYAxsLvrBckNgtvPsSttus : 18|2@1+ (1,0) [0|3] "" Vector__XXX
 SG_ Jystck10GrpYAxisNeutralPosStatus : 16|2@1+ (1,0) [0|3] "" Vector__XXX
 SG_ Joystick10GripXAxisPos : 6|10@1+ (0.1,0) [0|102] "%" Vector__XXX
 SG_ Jystck10GrpXAxsLvrRghtPstvPsStts : 4|2@1+ (1,0) [0|3] "" Vector__XXX
 SG_ Jystck10GrpXAxsLvrLftNgtvPsSttus : 2|2@1+ (1,0) [0|3] "" Vector__XXX
 SG_ Jystck10GrpXAxisNeutralPosStatus : 0|2@1+ (1,0) [0|3] "" Vector__XXX

BO_ 2566713598 EFS2: 8 Vector__XXX
 SG_ EngFuelFilterIntakeAbsPress : 0|8@1+ (2,0) [0|500] "kPa" Vector__XXX

BO_ 2499604478 EFL_P11: 8 Vector__XXX
 SG_ EngExhstGsRcrcltn1OutletAbsPress : 16|16@1+ (0.1,0) [0|6425.5] "kPa" Vector__XXX
 SG_ EngExhstGsRcrcltn1IntakeAbsPress : 0|16@1+ (0.1,0) [0|6425.5] "kPa" Vector__XXX

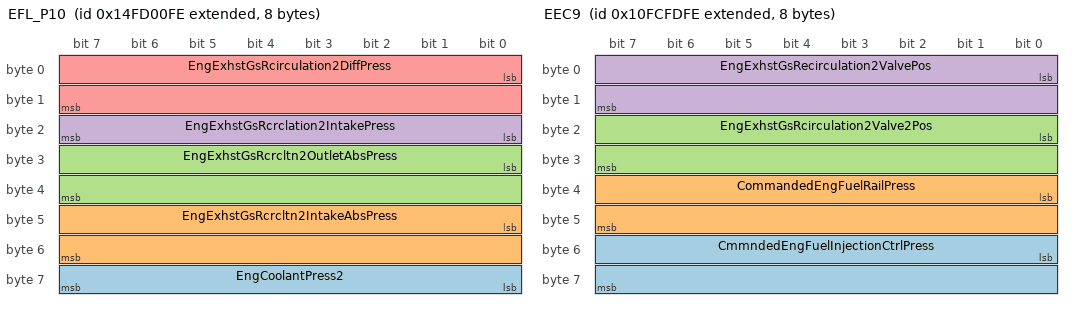
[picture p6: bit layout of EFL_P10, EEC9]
BO_ 2499608830 EFL_P10: 8 Vector__XXX
 SG_ EngCoolantPress2 : 56|8@1+ (2,0) [0|500] "kPa" Vector__XXX
 SG_ EngExhstGsRcrcltn2IntakeAbsPress : 40|16@1+ (0.1,0) [0|6425.5] "kPa" Vector__XXX
 SG_ EngExhstGsRcrcltn2OutletAbsPress : 24|16@1+ (0.1,0) [0|6425.5] "kPa" Vector__XXX
 SG_ EngExhstGsRcrclation2IntakePress : 16|8@1+ (2,0) [0|500] "kPa" Vector__XXX
 SG_ EngExhstGsRcirculation2DiffPress : 0|16@1+ (0.0078125,-250) [-250|251.99] "kPa" Vector__XXX

BO_ 2432499198 EEC9: 8 Vector__XXX
 SG_ CmmndedEngFuelInjectionCtrlPress : 48|16@1+ (0.00390625,0) [0|250.996] "MPa" Vector__XXX
 SG_ CommandedEngFuelRailPress : 32|16@1+ (0.00390625,0) [0|250.996] "MPa" Vector__XXX
 SG_ EngExhstGsRcirculation2Valve2Pos : 16|16@1+ (0.0025,0) [0|160.6375] "%" Vector__XXX
 SG_ EngExhstGsRecirculation2ValvePos : 0|16@1+ (0.0025,0) [0|160.6375] "%" Vector__XXX

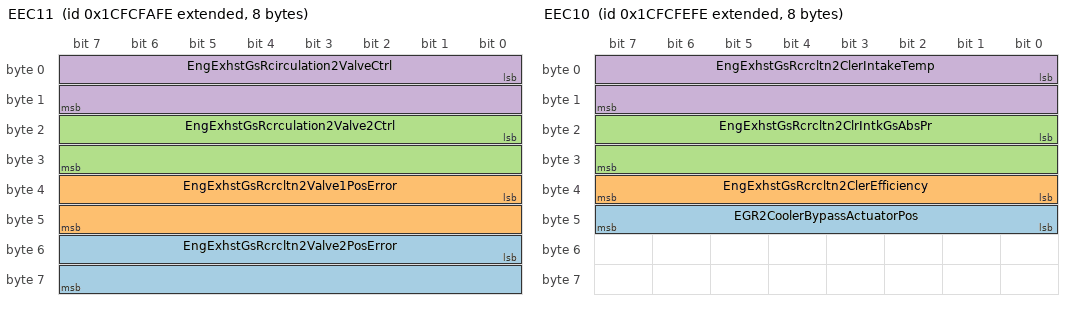
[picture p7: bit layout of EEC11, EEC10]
BO_ 2633825022 EEC11: 8 Vector__XXX
 SG_ EngExhstGsRcrcltn2Valve2PosError : 48|16@1+ (0.004,-125) [-125|132.02] "%" Vector__XXX
 SG_ EngExhstGsRcrcltn2Valve1PosError : 32|16@1+ (0.004,-125) [-125|132.02] "%" Vector__XXX
 SG_ EngExhstGsRcrculation2Valve2Ctrl : 16|16@1+ (0.0025,0) [0|160.6375] "%" Vector__XXX
 SG_ EngExhstGsRcirculation2ValveCtrl : 0|16@1+ (0.0025,0) [0|160.6375] "%" Vector__XXX

BO_ 2633826046 EEC10: 8 Vector__XXX
 SG_ EGR2CoolerBypassActuatorPos : 40|8@1+ (0.4,0) [0|100] "%" Vector__XXX
 SG_ EngExhstGsRcrcltn2ClerEfficiency : 32|8@1+ (0.4,0) [0|100] "%" Vector__XXX
 SG_ EngExhstGsRcrcltn2ClrIntkGsAbsPr : 16|16@1+ (0.5,0) [0|32127.5] "kPa" Vector__XXX
 SG_ EngExhstGsRcrcltn2ClerIntakeTemp : 0|16@1+ (0.03125,-273) [-273|1734.96875] "°C" Vector__XXX

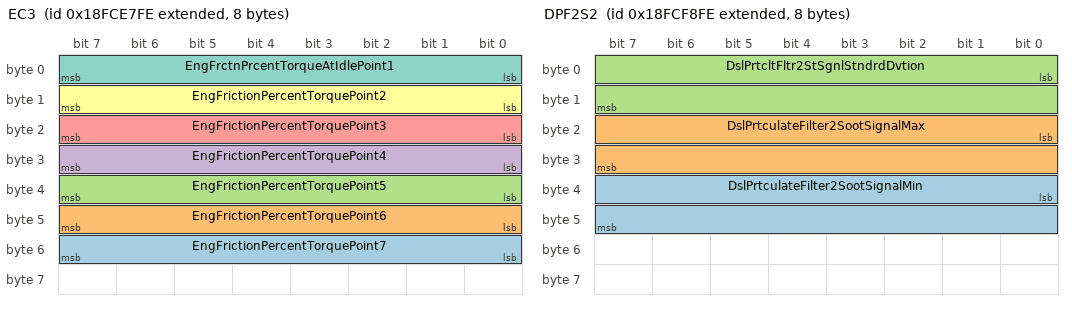
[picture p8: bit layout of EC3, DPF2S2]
BO_ 2566711294 EC3: 8 Vector__XXX
 SG_ EngFrictionPercentTorquePoint7 : 48|8@1+ (1,-125) [0|125] "%" Vector__XXX
 SG_ EngFrictionPercentTorquePoint6 : 40|8@1+ (1,-125) [0|125] "%" Vector__XXX
 SG_ EngFrictionPercentTorquePoint5 : 32|8@1+ (1,-125) [0|125] "%" Vector__XXX
 SG_ EngFrictionPercentTorquePoint4 : 24|8@1+ (1,-125) [0|125] "%" Vector__XXX
 SG_ EngFrictionPercentTorquePoint3 : 16|8@1+ (1,-125) [0|125] "%" Vector__XXX
 SG_ EngFrictionPercentTorquePoint2 : 8|8@1+ (1,-125) [0|125] "%" Vector__XXX
 SG_ EngFrctnPrcentTorqueAtIdlePoint1 : 0|8@1+ (1,-125) [0|125] "%" Vector__XXX

BO_ 2566749438 DPFC1: 8 Vector__XXX
 SG_ DslPrtcltFltrActvRgnrtnInhbt5629 : 58|2@1+ (1,0) [0|3] "" Vector__XXX
 SG_ DslPrtcltFltr1CndtnsNtMtFrActvRg : 60|2@1+ (1,0) [0|3] "" Vector__XXX
 SG_ HydrocarbonDoserPurgingEnable : 56|2@1+ (1,0) [0|3] "" Vector__XXX
 SG_ DslPrtcltFltrActvRgnrtnFrcdSttus : 53|3@1+ (1,0) [0|7] "" Vector__XXX
 SG_ ExhaustSystemHighTempLampCmd : 50|3@1+ (1,0) [0|7] "" Vector__XXX
 SG_ DslPrtcltFltrAtmtcActvRgnrtnIntt : 48|2@1+ (1,0) [0|3] "" Vector__XXX
 SG_ DslPrtcltFltrActvRgnrtnInhbt3717 : 46|2@1+ (1,0) [0|3] "" Vector__XXX
 SG_ DslPrtcltFltrActvRgnrtnInhbtdDTE : 44|2@1+ (1,0) [0|3] "" Vector__XXX
 SG_ DslPrtcltFltrActvRgnrtnInhbt3715 : 42|2@1+ (1,0) [0|3] "" Vector__XXX
 SG_ DslPrtcltFltrActvRgnrtnInhbtdDTT : 40|2@1+ (1,0) [0|3] "" Vector__XXX
 SG_ DslPrtcltFltrActvRgnrtnInhbt3713 : 38|2@1+ (1,0) [0|3] "" Vector__XXX
 SG_ DslPrtcltFltrActvRgnrtnInhbt3712 : 36|2@1+ (1,0) [0|3] "" Vector__XXX
 SG_ DslPrtcltFltrActvRgnrtnInhbtdDTL : 34|2@1+ (1,0) [0|3] "" Vector__XXX
 SG_ DslPrtcltFltrActvRgnrtnInhbt3710 : 32|2@1+ (1,0) [0|3] "" Vector__XXX
 SG_ DslPrtcltFltrActvRgnrtnInhbtdDTV : 30|2@1+ (1,0) [0|3] "" Vector__XXX
 SG_ DslPrtcltFltrActvRgnrtnInhbtdDTO : 28|2@1+ (1,0) [0|3] "" Vector__XXX
 SG_ DslPrtcltFltrActvRgnrtnInhbtdDTA : 26|2@1+ (1,0) [0|3] "" Vector__XXX
 SG_ DslPrtcltFltrActvRgnrtnInhbtdDTP : 24|2@1+ (1,0) [0|3] "" Vector__XXX
 SG_ DslPrtcltFltrActvRgnrtnInhbtdDTS : 22|2@1+ (1,0) [0|3] "" Vector__XXX
 SG_ DslPrtcltFltrActvRgnrtnInhbtdDTC : 20|2@1+ (1,0) [0|3] "" Vector__XXX
 SG_ DslPrtcltFltrActvRgnrtnInhbtdDTI : 18|2@1+ (1,0) [0|3] "" Vector__XXX
 SG_ DslPrtcltFltrActvRgnrtnInhbtdStt : 16|2@1+ (1,0) [0|3] "" Vector__XXX
 SG_ DieselParticulateFilterStatus : 12|3@1+ (1,0) [0|7] "" Vector__XXX
 SG_ DslPrtcltFltrActvRgnrationStatus : 10|2@1+ (1,0) [0|3] "" Vector__XXX
 SG_ DslPrtcltFltrPssvRgnrationStatus : 8|2@1+ (1,0) [0|3] "" Vector__XXX
 SG_ DieselParticulateFilterLampCmd : 0|3@1+ (1,0) [0|7] "" Vector__XXX

BO_ 2566715646 DPF2S2: 8 Vector__XXX
 SG_ DslPrtculateFilter2SootSignalMin : 32|16@1+ (0.0025,0) [0|160.6375] "%" Vector__XXX
 SG_ DslPrtculateFilter2SootSignalMax : 16|16@1+ (0.0025,0) [0|160.6375] "%" Vector__XXX
 SG_ DslPrtcltFltr2StSgnlStndrdDvtion : 0|16@1+ (0.0025,0) [0|160.6375] "%" Vector__XXX

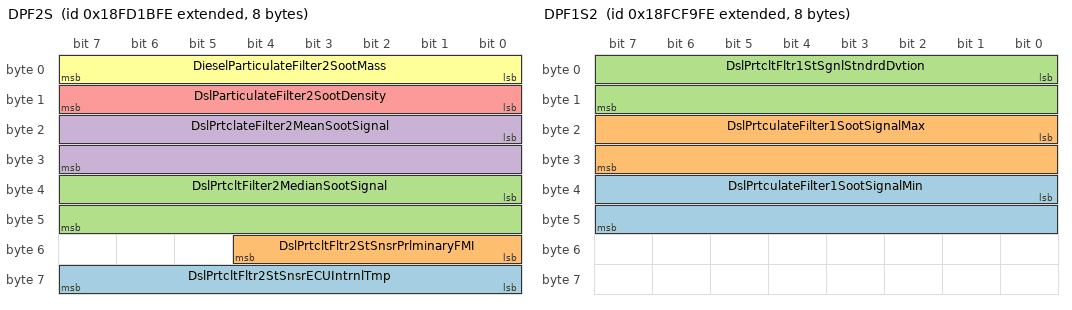
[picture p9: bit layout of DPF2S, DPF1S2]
BO_ 2566724606 DPF2S: 8 Vector__XXX
 SG_ DslPrtcltFltr2StSnsrECUIntrnlTmp : 56|8@1+ (1,-40) [-40|210] "°C" Vector__XXX
 SG_ DslPrtcltFltr2StSnsrPrlminaryFMI : 48|5@1+ (1,0) [0|31] "" Vector__XXX
 SG_ DslPrtcltFilter2MedianSootSignal : 32|16@1+ (0.0025,0) [0|160.6375] "%" Vector__XXX
 SG_ DslPrtclateFilter2MeanSootSignal : 16|16@1+ (0.0025,0) [0|160.6375] "%" Vector__XXX
 SG_ DslParticulateFilter2SootDensity : 8|8@1+ (0.08,0) [0|20] "g/L" Vector__XXX
 SG_ DieselParticulateFilter2SootMass : 0|8@1+ (4,0) [0|1000] "g" Vector__XXX

BO_ 2566715902 DPF1S2: 8 Vector__XXX
 SG_ DslPrtculateFilter1SootSignalMin : 32|16@1+ (0.0025,0) [0|160.6375] "%" Vector__XXX
 SG_ DslPrtculateFilter1SootSignalMax : 16|16@1+ (0.0025,0) [0|160.6375] "%" Vector__XXX
 SG_ DslPrtcltFltr1StSgnlStndrdDvtion : 0|16@1+ (0.0025,0) [0|160.6375] "%" Vector__XXX

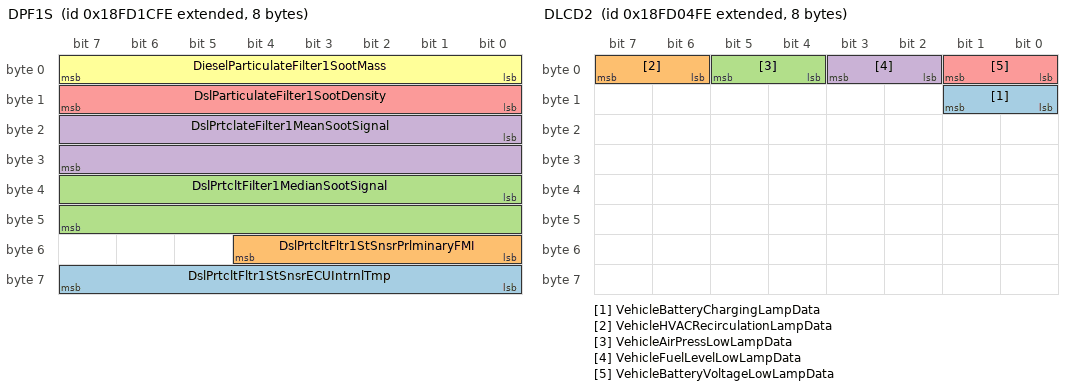
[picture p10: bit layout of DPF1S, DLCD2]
BO_ 2566724862 DPF1S: 8 Vector__XXX
 SG_ DslPrtcltFltr1StSnsrECUIntrnlTmp : 56|8@1+ (1,-40) [-40|210] "°C" Vector__XXX
 SG_ DslPrtcltFltr1StSnsrPrlminaryFMI : 48|5@1+ (1,0) [0|31] "" Vector__XXX
 SG_ DslPrtcltFilter1MedianSootSignal : 32|16@1+ (0.0025,0) [0|160.6375] "%" Vector__XXX
 SG_ DslPrtclateFilter1MeanSootSignal : 16|16@1+ (0.0025,0) [0|160.6375] "%" Vector__XXX
 SG_ DslParticulateFilter1SootDensity : 8|8@1+ (0.08,0) [0|20] "g/L" Vector__XXX
 SG_ DieselParticulateFilter1SootMass : 0|8@1+ (4,0) [0|1000] "g" Vector__XXX

BO_ 2566718718 DLCD2: 8 Vector__XXX
 SG_ VehicleBatteryChargingLampData : 8|2@1+ (1,0) [0|3] "" Vector__XXX
 SG_ VehicleHVACRecirculationLampData : 6|2@1+ (1,0) [0|3] "" Vector__XXX
 SG_ VehicleAirPressLowLampData : 4|2@1+ (1,0) [0|3] "" Vector__XXX
 SG_ VehicleFuelLevelLowLampData : 2|2@1+ (1,0) [0|3] "" Vector__XXX
 SG_ VehicleBatteryVoltageLowLampData : 0|2@1+ (1,0) [0|3] "" Vector__XXX

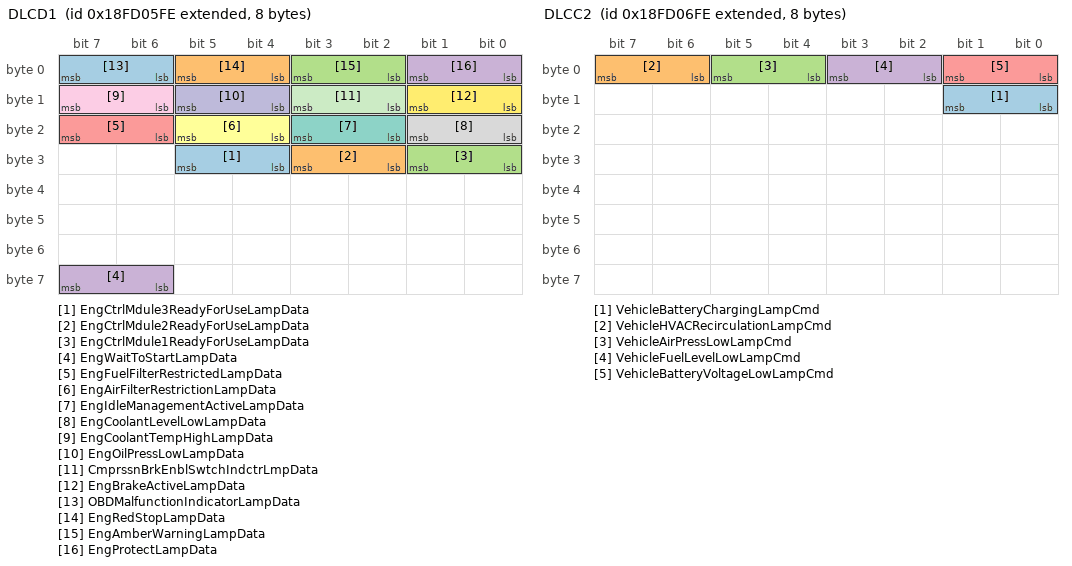
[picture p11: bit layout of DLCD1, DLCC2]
BO_ 2566718974 DLCD1: 8 Vector__XXX
 SG_ EngCtrlMdule3ReadyForUseLampData : 28|2@1+ (1,0) [0|3] "" Vector__XXX
 SG_ EngCtrlMdule2ReadyForUseLampData : 26|2@1+ (1,0) [0|3] "" Vector__XXX
 SG_ EngCtrlMdule1ReadyForUseLampData : 24|2@1+ (1,0) [0|3] "" Vector__XXX
 SG_ EngWaitToStartLampData : 62|2@1+ (1,0) [0|3] "" Vector__XXX
 SG_ EngFuelFilterRestrictedLampData : 22|2@1+ (1,0) [0|3] "" Vector__XXX
 SG_ EngAirFilterRestrictionLampData : 20|2@1+ (1,0) [0|3] "" Vector__XXX
 SG_ EngIdleManagementActiveLampData : 18|2@1+ (1,0) [0|3] "" Vector__XXX
 SG_ EngCoolantLevelLowLampData : 16|2@1+ (1,0) [0|3] "" Vector__XXX
 SG_ EngCoolantTempHighLampData : 14|2@1+ (1,0) [0|3] "" Vector__XXX
 SG_ EngOilPressLowLampData : 12|2@1+ (1,0) [0|3] "" Vector__XXX
 SG_ CmprssnBrkEnblSwtchIndctrLmpData : 10|2@1+ (1,0) [0|3] "" Vector__XXX
 SG_ EngBrakeActiveLampData : 8|2@1+ (1,0) [0|3] "" Vector__XXX
 SG_ OBDMalfunctionIndicatorLampData : 6|2@1+ (1,0) [0|3] "" Vector__XXX
 SG_ EngRedStopLampData : 4|2@1+ (1,0) [0|3] "" Vector__XXX
 SG_ EngAmberWarningLampData : 2|2@1+ (1,0) [0|3] "" Vector__XXX
 SG_ EngProtectLampData : 0|2@1+ (1,0) [0|3] "" Vector__XXX

BO_ 2566719230 DLCC2: 8 Vector__XXX
 SG_ VehicleBatteryChargingLampCmd : 8|2@1+ (1,0) [0|3] "" Vector__XXX
 SG_ VehicleHVACRecirculationLampCmd : 6|2@1+ (1,0) [0|3] "" Vector__XXX
 SG_ VehicleAirPressLowLampCmd : 4|2@1+ (1,0) [0|3] "" Vector__XXX
 SG_ VehicleFuelLevelLowLampCmd : 2|2@1+ (1,0) [0|3] "" Vector__XXX
 SG_ VehicleBatteryVoltageLowLampCmd : 0|2@1+ (1,0) [0|3] "" Vector__XXX

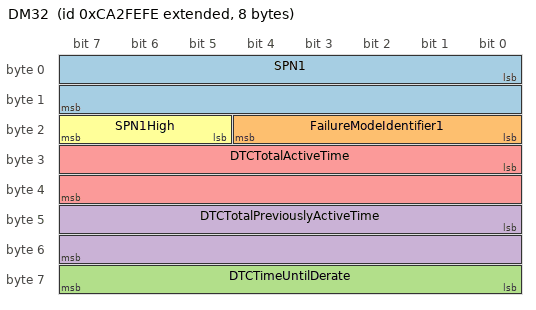
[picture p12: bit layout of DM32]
BO_ 2359492350 DM32: 8 Vector__XXX
 SG_ SPN1 : 0|16@1+ (1,0) [0|65536] "" Vector__XXX
 SG_ FailureModeIdentifier1 : 16|5@1+ (1,0) [0|0] "" Vector__XXX
 SG_ DTCTimeUntilDerate : 56|8@1+ (0.25,0) [0|62.5] "hr" Vector__XXX
 SG_ DTCTotalPreviouslyActiveTime : 40|16@1+ (0.2,0) [0|12851] "hr" Vector__XXX
 SG_ DTCTotalActiveTime : 24|16@1+ (0.2,0) [0|12851] "hr" Vector__XXX
 SG_ SPN1High : 21|3@1+ (1,0) [0|7] "" Vector__XXX

BO_ 2561212158 DISP1: 8 Vector__XXX
 SG_ TextDisplayIndex : 16|8@1+ (1,0) [0|200] "" Vector__XXX
 SG_ TextDisplayInstructions : 0|4@1+ (1,0) [0|15] "" Vector__XXX

CM_ BO_ 2566711550 "Contains information about the intake valve actuation system control.";
CM_ SG_ 2566711550 IntkVlvActtnSystmOlPrss2SlndCtrl "Indicates the current command to the solenoid that controls the intake valve actuation system oil pressure 2 valve. This valve opens or closes a connection from the intake valve actuation oil rail to tank.
00 off
01 on
10 reserved for SAE ...";
CM_ SG_ 2566711550 IntkVlvActtnSystmOlPrss1SlndCtrl "Indicates the current command to the solenoid that controls the intake valve actuation system oil pressure 1 valve. This valve opens or closes a connection from the intake valve actuation oil rail to tank.
00 off
01 on
10 reserved for SAE ...";
CM_ BO_ 2633832958 "Message containing resistance values for every equipped ignitor loop of the restraint-system. (Maximum of 100 Ignitor Loops.)
.
.
Byte 21-22    Special Ignitor Loop [1], if installed
Byte 23-24    Special Ignitor Loop [2], if installed
.
.
Up ...";
CM_ SG_ 2633832958 SpecialIgnitorLoop90Resistance "Resistance of Special Ignitor Loop 90.   Since there are many different vehicle types (e.g. truck, bus, firetruck or ambulance), the ignitor loop configuration has a wide variation.";
CM_ SG_ 2633832958 SpecialIgnitorLoop89Resistance "Resistance of Special Ignitor Loop 89.   Since there are many different vehicle types (e.g. truck, bus, firetruck or ambulance), the ignitor loop configuration has a wide variation.";
CM_ SG_ 2633832958 SpecialIgnitorLoop88Resistance "Resistance of Special Ignitor Loop 88.   Since there are many different vehicle types (e.g. truck, bus, firetruck or ambulance), the ignitor loop configuration has a wide variation.";
CM_ SG_ 2633832958 SpecialIgnitorLoop87Resistance "Resistance of Special Ignitor Loop 87.   Since there are many different vehicle types (e.g. truck, bus, firetruck or ambulance), the ignitor loop configuration has a wide variation.";
CM_ SG_ 2633832958 SpecialIgnitorLoop86Resistance "Resistance of Special Ignitor Loop 86.   Since there are many different vehicle types (e.g. truck, bus, firetruck or ambulance), the ignitor loop configuration has a wide variation.";
CM_ SG_ 2633832958 SpecialIgnitorLoop85Resistance "Resistance of Special Ignitor Loop 85.   Since there are many different vehicle types (e.g. truck, bus, firetruck or ambulance), the ignitor loop configuration has a wide variation.";
CM_ SG_ 2633832958 SpecialIgnitorLoop84Resistance "Resistance of Special Ignitor Loop 84.   Since there are many different vehicle types (e.g. truck, bus, firetruck or ambulance), the ignitor loop configuration has a wide variation.";
CM_ SG_ 2633832958 SpecialIgnitorLoop83Resistance "Resistance of Special Ignitor Loop 83.   Since there are many different vehicle types (e.g. truck, bus, firetruck or ambulance), the ignitor loop configuration has a wide variation.";
CM_ SG_ 2633832958 SpecialIgnitorLoop82Resistance "Resistance of Special Ignitor Loop 82.   Since there are many different vehicle types (e.g. truck, bus, firetruck or ambulance), the ignitor loop configuration has a wide variation.";
CM_ SG_ 2633832958 SpecialIgnitorLoop81Resistance "Resistance of Special Ignitor Loop 81.   Since there are many different vehicle types (e.g. truck, bus, firetruck or ambulance), the ignitor loop configuration has a wide variation.";
CM_ SG_ 2633832958 SpecialIgnitorLoop80Resistance "Resistance of Special Ignitor Loop 80.   Since there are many different vehicle types (e.g. truck, bus, firetruck or ambulance), the ignitor loop configuration has a wide variation.";
CM_ SG_ 2633832958 SpecialIgnitorLoop79Resistance "Resistance of Special Ignitor Loop 79.   Since there are many different vehicle types (e.g. truck, bus, firetruck or ambulance), the ignitor loop configuration has a wide variation.";
CM_ SG_ 2633832958 SpecialIgnitorLoop78Resistance "Resistance of Special Ignitor Loop 78.   Since there are many different vehicle types (e.g. truck, bus, firetruck or ambulance), the ignitor loop configuration has a wide variation.";
CM_ SG_ 2633832958 SpecialIgnitorLoop77Resistance "Resistance of Special Ignitor Loop 77.   Since there are many different vehicle types (e.g. truck, bus, firetruck or ambulance), the ignitor loop configuration has a wide variation.";
CM_ SG_ 2633832958 SpecialIgnitorLoop76Resistance "Resistance of Special Ignitor Loop 76.   Since there are many different vehicle types (e.g. truck, bus, firetruck or ambulance), the ignitor loop configuration has a wide variation.";
CM_ SG_ 2633832958 SpecialIgnitorLoop75Resistance "Resistance of Special Ignitor Loop 75.   Since there are many different vehicle types (e.g. truck, bus, firetruck or ambulance), the ignitor loop configuration has a wide variation.";
CM_ SG_ 2633832958 SpecialIgnitorLoop74Resistance "Resistance of Special Ignitor Loop 74.   Since there are many different vehicle types (e.g. truck, bus, firetruck or ambulance), the ignitor loop configuration has a wide variation.";
CM_ SG_ 2633832958 SpecialIgnitorLoop73Resistance "Resistance of Special Ignitor Loop 73.   Since there are many different vehicle types (e.g. truck, bus, firetruck or ambulance), the ignitor loop configuration has a wide variation.";
CM_ SG_ 2633832958 SpecialIgnitorLoop72Resistance "Resistance of Special Ignitor Loop 72.   Since there are many different vehicle types (e.g. truck, bus, firetruck or ambulance), the ignitor loop configuration has a wide variation.";
CM_ SG_ 2633832958 SpecialIgnitorLoop71Resistance "Resistance of Special Ignitor Loop 71.   Since there are many different vehicle types (e.g. truck, bus, firetruck or ambulance), the ignitor loop configuration has a wide variation.";
CM_ SG_ 2633832958 SpecialIgnitorLoop70Resistance "Resistance of Special Ignitor Loop 70.   Since there are many different vehicle types (e.g. truck, bus, firetruck or ambulance), the ignitor loop configuration has a wide variation.";
CM_ SG_ 2633832958 SpecialIgnitorLoop69Resistance "Resistance of Special Ignitor Loop 69.   Since there are many different vehicle types (e.g. truck, bus, firetruck or ambulance), the ignitor loop configuration has a wide variation.";
CM_ SG_ 2633832958 SpecialIgnitorLoop68Resistance "Resistance of Special Ignitor Loop 68.   Since there are many different vehicle types (e.g. truck, bus, firetruck or ambulance), the ignitor loop configuration has a wide variation.";
CM_ SG_ 2633832958 SpecialIgnitorLoop67Resistance "Resistance of Special Ignitor Loop 67.   Since there are many different vehicle types (e.g. truck, bus, firetruck or ambulance), the ignitor loop configuration has a wide variation.";
CM_ SG_ 2633832958 SpecialIgnitorLoop66Resistance "Resistance of Special Ignitor Loop 66.   Since there are many different vehicle types (e.g. truck, bus, firetruck or ambulance), the ignitor loop configuration has a wide variation.";
CM_ SG_ 2633832958 SpecialIgnitorLoop65Resistance "Resistance of Special Ignitor Loop 65.   Since there are many different vehicle types (e.g. truck, bus, firetruck or ambulance), the ignitor loop configuration has a wide variation.";
CM_ SG_ 2633832958 SpecialIgnitorLoop64Resistance "Resistance of Special Ignitor Loop 64.   Since there are many different vehicle types (e.g. truck, bus, firetruck or ambulance), the ignitor loop configuration has a wide variation.";
CM_ SG_ 2633832958 SpecialIgnitorLoop63Resistance "Resistance of Special Ignitor Loop 63.   Since there are many different vehicle types (e.g. truck, bus, firetruck or ambulance), the ignitor loop configuration has a wide variation.";
CM_ SG_ 2633832958 SpecialIgnitorLoop62Resistance "Resistance of Special Ignitor Loop 62.   Since there are many different vehicle types (e.g. truck, bus, firetruck or ambulance), the ignitor loop configuration has a wide variation.";
CM_ SG_ 2633832958 SpecialIgnitorLoop61Resistance "Resistance of Special Ignitor Loop 61.   Since there are many different vehicle types (e.g. truck, bus, firetruck or ambulance), the ignitor loop configuration has a wide variation.";
CM_ SG_ 2633832958 SpecialIgnitorLoop60Resistance "Resistance of Special Ignitor Loop 60.   Since there are many different vehicle types (e.g. truck, bus, firetruck or ambulance), the ignitor loop configuration has a wide variation.";
CM_ SG_ 2633832958 SpecialIgnitorLoop59Resistance "Resistance of Special Ignitor Loop 59.   Since there are many different vehicle types (e.g. truck, bus, firetruck or ambulance), the ignitor loop configuration has a wide variation.";
CM_ SG_ 2633832958 SpecialIgnitorLoop58Resistance "Resistance of Special Ignitor Loop 58.   Since there are many different vehicle types (e.g. truck, bus, firetruck or ambulance), the ignitor loop configuration has a wide variation.";
CM_ SG_ 2633832958 SpecialIgnitorLoop57Resistance "Resistance of Special Ignitor Loop 57.   Since there are many different vehicle types (e.g. truck, bus, firetruck or ambulance), the ignitor loop configuration has a wide variation.";
CM_ SG_ 2633832958 SpecialIgnitorLoop56Resistance "Resistance of Special Ignitor Loop 56.   Since there are many different vehicle types (e.g. truck, bus, firetruck or ambulance), the ignitor loop configuration has a wide variation.";
CM_ SG_ 2633832958 SpecialIgnitorLoop55Resistance "Resistance of Special Ignitor Loop 55.   Since there are many different vehicle types (e.g. truck, bus, firetruck or ambulance), the ignitor loop configuration has a wide variation.";
CM_ SG_ 2633832958 SpecialIgnitorLoop54Resistance "Resistance of Special Ignitor Loop 54.   Since there are many different vehicle types (e.g. truck, bus, firetruck or ambulance), the ignitor loop configuration has a wide variation.";
CM_ SG_ 2633832958 SpecialIgnitorLoop53Resistance "Resistance of Special Ignitor Loop 53.   Since there are many different vehicle types (e.g. truck, bus, firetruck or ambulance), the ignitor loop configuration has a wide variation.";
CM_ SG_ 2633832958 SpecialIgnitorLoop52Resistance "Resistance of Special Ignitor Loop 52.   Since there are many different vehicle types (e.g. truck, bus, firetruck or ambulance), the ignitor loop configuration has a wide variation.";
CM_ SG_ 2633832958 SpecialIgnitorLoop51Resistance "Resistance of Special Ignitor Loop 51.   Since there are many different vehicle types (e.g. truck, bus, firetruck or ambulance), the ignitor loop configuration has a wide variation.";
CM_ SG_ 2633832958 SpecialIgnitorLoop50Resistance "Resistance of Special Ignitor Loop 50.   Since there are many different vehicle types (e.g. truck, bus, firetruck or ambulance), the ignitor loop configuration has a wide variation.";
CM_ SG_ 2633832958 SpecialIgnitorLoop49Resistance "Resistance of Special Ignitor Loop 49.   Since there are many different vehicle types (e.g. truck, bus, firetruck or ambulance), the ignitor loop configuration has a wide variation.";
CM_ SG_ 2633832958 SpecialIgnitorLoop48Resistance "Resistance of Special Ignitor Loop 48.   Since there are many different vehicle types (e.g. truck, bus, firetruck or ambulance), the ignitor loop configuration has a wide variation.";
CM_ SG_ 2633832958 SpecialIgnitorLoop47Resistance "Resistance of Special Ignitor Loop 47.   Since there are many different vehicle types (e.g. truck, bus, firetruck or ambulance), the ignitor loop configuration has a wide variation.";
CM_ SG_ 2633832958 SpecialIgnitorLoop46Resistance "Resistance of Special Ignitor Loop 46.   Since there are many different vehicle types (e.g. truck, bus, firetruck or ambulance), the ignitor loop configuration has a wide variation.";
CM_ SG_ 2633832958 SpecialIgnitorLoop45Resistance "Resistance of Special Ignitor Loop 45.   Since there are many different vehicle types (e.g. truck, bus, firetruck or ambulance), the ignitor loop configuration has a wide variation.";
CM_ SG_ 2633832958 SpecialIgnitorLoop44Resistance "Resistance of Special Ignitor Loop 44.   Since there are many different vehicle types (e.g. truck, bus, firetruck or ambulance), the ignitor loop configuration has a wide variation.";
CM_ SG_ 2633832958 SpecialIgnitorLoop43Resistance "Resistance of Special Ignitor Loop 43.   Since there are many different vehicle types (e.g. truck, bus, firetruck or ambulance), the ignitor loop configuration has a wide variation.";
CM_ SG_ 2633832958 SpecialIgnitorLoop42Resistance "Resistance of Special Ignitor Loop 42.   Since there are many different vehicle types (e.g. truck, bus, firetruck or ambulance), the ignitor loop configuration has a wide variation.";
CM_ SG_ 2633832958 SpecialIgnitorLoop41Resistance "Resistance of Special Ignitor Loop 41.   Since there are many different vehicle types (e.g. truck, bus, firetruck or ambulance), the ignitor loop configuration has a wide variation.";
CM_ SG_ 2633832958 SpecialIgnitorLoop40Resistance "Resistance of Special Ignitor Loop 40.   Since there are many different vehicle types (e.g. truck, bus, firetruck or ambulance), the ignitor loop configuration has a wide variation.";
CM_ SG_ 2633832958 SpecialIgnitorLoop39Resistance "Resistance of Special Ignitor Loop 39.   Since there are many different vehicle types (e.g. truck, bus, firetruck or ambulance), the ignitor loop configuration has a wide variation.";
CM_ SG_ 2633832958 SpecialIgnitorLoop38Resistance "Resistance of Special Ignitor Loop 38.   Since there are many different vehicle types (e.g. truck, bus, firetruck or ambulance), the ignitor loop configuration has a wide variation.";
CM_ SG_ 2633832958 SpecialIgnitorLoop37Resistance "Resistance of Special Ignitor Loop 37.   Since there are many different vehicle types (e.g. truck, bus, firetruck or ambulance), the ignitor loop configuration has a wide variation.";
CM_ SG_ 2633832958 SpecialIgnitorLoop36Resistance "Resistance of Special Ignitor Loop 36.   Since there are many different vehicle types (e.g. truck, bus, firetruck or ambulance), the ignitor loop configuration has a wide variation.";
CM_ SG_ 2633832958 SpecialIgnitorLoop35Resistance "Resistance of Special Ignitor Loop 35.   Since there are many different vehicle types (e.g. truck, bus, firetruck or ambulance), the ignitor loop configuration has a wide variation.";
CM_ SG_ 2633832958 SpecialIgnitorLoop34Resistance "Resistance of Special Ignitor Loop 34.   Since there are many different vehicle types (e.g. truck, bus, firetruck or ambulance), the ignitor loop configuration has a wide variation.";
CM_ SG_ 2633832958 SpecialIgnitorLoop33Resistance "Resistance of Special Ignitor Loop 33.   Since there are many different vehicle types (e.g. truck, bus, firetruck or ambulance), the ignitor loop configuration has a wide variation.";
CM_ SG_ 2633832958 SpecialIgnitorLoop32Resistance "Resistance of Special Ignitor Loop 32.   Since there are many different vehicle types (e.g. truck, bus, firetruck or ambulance), the ignitor loop configuration has a wide variation.";
CM_ SG_ 2633832958 SpecialIgnitorLoop31Resistance "Resistance of Special Ignitor Loop 31.   Since there are many different vehicle types (e.g. truck, bus, firetruck or ambulance), the ignitor loop configuration has a wide variation.";
CM_ SG_ 2633832958 SpecialIgnitorLoop30Resistance "Resistance of Special Ignitor Loop 30.   Since there are many different vehicle types (e.g. truck, bus, firetruck or ambulance), the ignitor loop configuration has a wide variation.";
CM_ SG_ 2633832958 SpecialIgnitorLoop29Resistance "Resistance of Special Ignitor Loop 29.   Since there are many different vehicle types (e.g. truck, bus, firetruck or ambulance), the ignitor loop configuration has a wide variation.";
CM_ SG_ 2633832958 SpecialIgnitorLoop28Resistance "Resistance of Special Ignitor Loop 28.   Since there are many different vehicle types (e.g. truck, bus, firetruck or ambulance), the ignitor loop configuration has a wide variation.";
CM_ SG_ 2633832958 SpecialIgnitorLoop27Resistance "Resistance of Special Ignitor Loop 27.   Since there are many different vehicle types (e.g. truck, bus, firetruck or ambulance), the ignitor loop configuration has a wide variation.";
CM_ SG_ 2633832958 SpecialIgnitorLoop26Resistance "Resistance of Special Ignitor Loop 26.   Since there are many different vehicle types (e.g. truck, bus, firetruck or ambulance), the ignitor loop configuration has a wide variation.";
CM_ SG_ 2633832958 SpecialIgnitorLoop25Resistance "Resistance of Special Ignitor Loop 25.   Since there are many different vehicle types (e.g. truck, bus, firetruck or ambulance), the ignitor loop configuration has a wide variation.";
CM_ SG_ 2633832958 SpecialIgnitorLoop24Resistance "Resistance of Special Ignitor Loop 24.   Since there are many different vehicle types (e.g. truck, bus, firetruck or ambulance), the ignitor loop configuration has a wide variation.";
CM_ SG_ 2633832958 SpecialIgnitorLoop23Resistance "Resistance of Special Ignitor Loop 23.   Since there are many different vehicle types (e.g. truck, bus, firetruck or ambulance), the ignitor loop configuration has a wide variation.";
CM_ SG_ 2633832958 SpecialIgnitorLoop22Resistance "Resistance of Special Ignitor Loop 22.   Since there are many different vehicle types (e.g. truck, bus, firetruck or ambulance), the ignitor loop configuration has a wide variation.";
CM_ SG_ 2633832958 SpecialIgnitorLoop21Resistance "Resistance of Special Ignitor Loop 21.   Since there are many different vehicle types (e.g. truck, bus, firetruck or ambulance), the ignitor loop configuration has a wide variation.";
CM_ SG_ 2633832958 SpecialIgnitorLoop20Resistance "Resistance of Special Ignitor Loop 20.   Since there are many different vehicle types (e.g. truck, bus, firetruck or ambulance), the ignitor loop configuration has a wide variation.";
CM_ SG_ 2633832958 SpecialIgnitorLoop19Resistance "Resistance of Special Ignitor Loop 19.   Since there are many different vehicle types (e.g. truck, bus, firetruck or ambulance), the ignitor loop configuration has a wide variation.";
CM_ SG_ 2633832958 SpecialIgnitorLoop18Resistance "Resistance of Special Ignitor Loop 18.   Since there are many different vehicle types (e.g. truck, bus, firetruck or ambulance), the ignitor loop configuration has a wide variation.";
CM_ SG_ 2633832958 SpecialIgnitorLoop17Resistance "Resistance of Special Ignitor Loop 17.   Since there are many different vehicle types (e.g. truck, bus, firetruck or ambulance), the ignitor loop configuration has a wide variation.";
CM_ SG_ 2633832958 SpecialIgnitorLoop16Resistance "Resistance of Special Ignitor Loop 16.   Since there are many different vehicle types (e.g. truck, bus, firetruck or ambulance), the ignitor loop configuration has a wide variation.";
CM_ SG_ 2633832958 SpecialIgnitorLoop15Resistance "Resistance of Special Ignitor Loop 15.   Since there are many different vehicle types (e.g. truck, bus, firetruck or ambulance), the ignitor loop configuration has a wide variation.";
CM_ SG_ 2633832958 SpecialIgnitorLoop14Resistance "Resistance of Special Ignitor Loop 14.   Since there are many different vehicle types (e.g. truck, bus, firetruck or ambulance), the ignitor loop configuration has a wide variation.";
CM_ SG_ 2633832958 SpecialIgnitorLoop13Resistance "Resistance of Special Ignitor Loop 13.   Since there are many different vehicle types (e.g. truck, bus, firetruck or ambulance), the ignitor loop configuration has a wide variation.";
CM_ SG_ 2633832958 SpecialIgnitorLoop12Resistance "Resistance of Special Ignitor Loop 12.   Since there are many different vehicle types (e.g. truck, bus, firetruck or ambulance), the ignitor loop configuration has a wide variation.";
CM_ SG_ 2633832958 SpecialIgnitorLoop11Resistance "Resistance of Special Ignitor Loop 11.   Since there are many different vehicle types (e.g. truck, bus, firetruck or ambulance), the ignitor loop configuration has a wide variation.";
CM_ SG_ 2633832958 SpecialIgnitorLoop10Resistance "Resistance of Special Ignitor Loop 10.   Since there are many different vehicle types (e.g. truck, bus, firetruck or ambulance), the ignitor loop configuration has a wide variation.";
CM_ SG_ 2633832958 SpecialIgnitorLoop9Resistance "Resistance of Special Ignitor Loop 9.   Since there are many different vehicle types (e.g. truck, bus, firetruck or ambulance), the ignitor loop configuration has a wide variation.";
CM_ SG_ 2633832958 SpecialIgnitorLoop8Resistance "Resistance of Special Ignitor Loop 8.   Since there are many different vehicle types (e.g. truck, bus, firetruck or ambulance), the ignitor loop configuration has a wide variation.";
CM_ SG_ 2633832958 SpecialIgnitorLoop7Resistance "Resistance of Special Ignitor Loop 7.   Since there are many different vehicle types (e.g. truck, bus, firetruck or ambulance), the ignitor loop configuration has a wide variation.";
CM_ SG_ 2633832958 SpecialIgnitorLoop6Resistance "Resistance of Special Ignitor Loop 6.   Since there are many different vehicle types (e.g. truck, bus, firetruck or ambulance), the ignitor loop configuration has a wide variation.";
CM_ SG_ 2633832958 SpecialIgnitorLoop5Resistance "Resistance of Special Ignitor Loop 5.   Since there are many different vehicle types (e.g. truck, bus, firetruck or ambulance), the ignitor loop configuration has a wide variation.";
CM_ SG_ 2633832958 SpecialIgnitorLoop4Resistance "Resistance of Special Ignitor Loop 4.   Since there are many different vehicle types (e.g. truck, bus, firetruck or ambulance), the ignitor loop configuration has a wide variation.";
CM_ SG_ 2633832958 SpecialIgnitorLoop3Resistance "Resistance of Special Ignitor Loop 3.   Since there are many different vehicle types (e.g. truck, bus, firetruck or ambulance), the ignitor loop configuration has a wide variation.";
CM_ SG_ 2633832958 SpecialIgnitorLoop2Resistance "Resistance of Special Ignitor Loop 2.   Since there are many different vehicle types (e.g. truck, bus, firetruck or ambulance), the ignitor loop configuration has a wide variation.";
CM_ SG_ 2633832958 SpecialIgnitorLoop1Resistance "Resistance of Special Ignitor Loop 1.   Since there are many different vehicle types (e.g. truck, bus, firetruck or ambulance), the ignitor loop configuration has a wide variation.";
CM_ SG_ 2633832958 SdBagIgnitorLoop2RightResistance "Resistance of Side Bag Ignitor Loop 2 - Right.";
CM_ SG_ 2633832958 SdBagIgnitorLoop1RightResistance "Resistance of Side Bag Ignitor Loop 1 - Right.";
CM_ SG_ 2633832958 SdeBagIgnitorLoop2LeftResistance "Resistance of Side Bag Ignitor Loop 2 - Left.";
CM_ SG_ 2633832958 SdeBagIgnitorLoop1LeftResistance "Resistance of Side Bag Ignitor Loop 1 - Left.";
CM_ SG_ 2633832958 PssngrBltTnsnrIgntrLopResistance "Resistance of Passenger Belt Tensioner Ignitor Loop 1st Stage.";
CM_ SG_ 2633832958 DrvrBltTnsnrIgntorLoopResistance "Resistance of Driver Belt Tensioner Ignitor Loop 1st Stage.";
CM_ SG_ 2633832958 PssngrArbgIgntrLp2ndStgRsistance "Resistance of Passenger Airbag Ignitor Loop 2nd Stage.";
CM_ SG_ 2633832958 DrvrArbgIgntrLp2ndStgeResistance "Resistance of Driver Airbag Ignitor Loop 2nd Stage.";
CM_ SG_ 2633832958 PssngrArbgIgntrLp1stStgRsistance "Resistance of Passenger Airbag Ignitor Loop 1st Stage.";
CM_ SG_ 2633832958 DrvrArbgIgntrLp1stStgeResistance "Resistance of Driver Airbag Ignitor Loop 1st Stage.";
CM_ BO_ 2566719998 "Engine fuel consumption accumulators.  See PGN 65257 for alternate resolution.";
CM_ SG_ 2566719998 HighResolutionEngTotalFuelUsed "Accumulated amount of fuel used during vehicle operation.  High resolution used for calculations and fleet management systems.  See SPN 250 for alternate resolution.";
CM_ SG_ 2566719998 HighResolutionEngTripFuel "Fuel consumed during all or part of a journey.   High resolution used for calculations and fleet management systems.  See SPN 182 for alternate resolution.";
CM_ BO_ 2565877502 "This PGN contains the Engine Turbocharger Wastegate Actuator 1 & 2 control, Exhaust Back Pressure Regulator and Blowoff Actuator commands.";
CM_ SG_ 2565877502 EngTrbCmprssrBlowoffActuator1Cmd "The command to blow off actuator 1, normalized to percent, where 0% nominally represents fully closed (No Flow) and 100% represents fully open (Max Flow). The purpose of Blow-off value is similar to that of Compressor bypass valve, however the ...";
CM_ SG_ 2565877502 EngExhstBckPressRegulatorCtrlCmd "The control command to the Engine Exhaust Back Pressure Regulator, normalized to percent.  100 percent means the regulator is fully closed, providing the maximum restriction to exhaust gas flow from the engine.  Zero percent means the regulator is ...";
CM_ SG_ 2565877502 EngTurboWastegateActuator2Cmd "The command to a Turbocharger Wastegate actuator 2, normalized to percent, where 0% nominally represents fully closed (No Flow) and 100% represents fully open (Max Flow).";
CM_ SG_ 2565877502 EngTurboWastegateActuator1Cmd "The command to a Turbocharger Wastegate actuator 1, normalized to percent, where 0% nominally represents fully closed (No Flow) and 100% represents fully open (Max Flow).";
CM_ BO_ 2566713854 "This PGN will be used to transmit  the Engine Turbocharger Wastegate and Exhaust Back Pressure Regulator Information.";
CM_ SG_ 2566713854 EngExhaustBackPressActuator1Temp "Temperature of the Engine Exhaust Back Pressure Actuator 1 drive circuitry.  Temperature excursions may affect the torque output.";
CM_ SG_ 2566713854 EngExhstBckPrssActtor1DesiredPos "The requested position of the Engine Exhaust Back Pressure Actuator 1 by the engine ECU, where 0% represents fully closed and 100% represents fully open.

This is the position that the device is attempting to achieve.";
CM_ SG_ 2566713854 EngTurboWastegateActuator1Temp "Temperature of the Engine Turbocharger Wastegate Actuator 1 drive circuitry.  Temperature excursions may affect the torque output.";
CM_ SG_ 2566713854 EngExhstBckPrssRgltrCtrlOprtnStt "Used to identify the status of Engine Exhaust Back Pressure Regulator.
0000 – Normal
0001 – Alarm (fully operational but needs service)
0010 – Alarm High Severity (functional but transient performance may be reduced)
0011 – Derate Active (torque ...";
CM_ SG_ 2566713854 EngExhstBckPrssRglatorTempStatus "Used to identify the status of the Engine Exhaust Back Pressure Regulator (EBPR) drive circuitry temperature. Temperature excursions may affect the torque output.
000 – High most severe
001 – High Least severe
010 – In Range
011 – Low Least ...";
CM_ SG_ 2566713854 EngExhstBckPrssRgltrPrlminaryFMI "Used to identify the applicable J1939-73 FMI detected in the Engine Exhaust Back Pressure Regulator (EBPR) by the manufacturers software. When there is no failure, FMI 31 is transmitted. When there are multiple failures, the most severe is ...";
CM_ SG_ 2566713854 EngExhaustBackPressRegulatorPos "The position of the Exhaust Back Pressure Regulator (EBPR) expressed as a percentage of full travel.  One hundred percent means the regulator is fully closed, providing the maximum restriction to exhaust gas flow from the engine.  Zero percent means ...";
CM_ SG_ 2566713854 EngTrbWstgtActtr2OperationStatus "Used to identify the status of Engine Turbocharger Wastegate Actuator 2
0000 – Normal
0001 – Alarm (fully operational but needs service)
0010 – Alarm High Severity (functional but transient performance may be reduced)
0011 – Derate Active ...";
CM_ SG_ 2566713854 EngTrbWstgtActtr1OperationStatus "Used to identify the status of Engine Turbocharger Wastegate Actuator 1
0000 – Normal
0001 – Alarm (fully operational but needs service)
0010 – Alarm High Severity (functional but transient performance may be reduced)
0011 – Derate Active ...";
CM_ SG_ 2566713854 EngTrbWstgateActuator2TempStatus "Used to identify the status of the Engine Turbocharger Wastegate Actuator 2 drive circuitry temperature.  Temperature excursions may affect the torque output.
000 – High most severe
001 – High Least severe
010 – In Range
011 – Low Least severe
 ...";
CM_ SG_ 2566713854 EngTrbWstgtActtor2PreliminaryFMI "Used to identify the applicable J1939-73 FMI detected in the Engine Turbocharger Wastegate Actuator 2 by the manufacturers software. When there is no failure FMI 31 is transmitted. When there is multiple failures, the most severe is transmitted";
CM_ BO_ 2566714366 "This PGN will contain the Engine Turbocharger Compressor Bypass information";
CM_ SG_ 2566714366 EngTrbCmprssrBypassActuator2Temp "Temperature of the Engine Turbocharger Compressor Bypass Actuator 2 drive circuitry.    Temperature excursions may affect the torque output.";
CM_ SG_ 2566714366 EngTrbCmprssrBypassActuator1Temp "Temperature of the Engine Turbocharger Compressor Bypass Actuator 1 drive circuitry.    Temperature excursions may affect the torque output.";
CM_ SG_ 2566714366 EngTrbCmprssrBypssActtr2OprtnStt "Used to identify the status of Engine Turbocharger Compressor Bypass Actuator 2
0000 – Normal
0001 – Alarm (fully operational but needs service)
0010 – Alarm High Severity (functional but transient performance may be reduced)
0011 – Derate ...";
CM_ SG_ 2566714366 EngTrbCmprssrBypssActtr1OprtnStt "Used to identify the status of Engine Turbocharger Compressor Bypass Actuator 1
0000 – Normal
0001 – Alarm (fully operational but needs service)
0010 – Alarm High Severity (functional but transient performance may be reduced)
0011 – Derate ...";
CM_ SG_ 2566714366 EngTrbCmprssrBypssActtr2TmpSttus "Used to identify the status of the Engine Turbocharger Compresssor Bypass Actuator 2 drive circuitry temperature.  Temperature excursions may affect the torque output.
000 – High most severe
001 – High Least severe
010 – In Range
011 – Low Least ...";
CM_ SG_ 2566714366 EngTrbCmprssrBypssActtr2PrlmnryF "Used to identify the applicable J1939-73 FMI detected in the Engine Turbocharger Compressor Bypass Actuator 1 by the manufacturers software. When there is no failure FMI 31 is transmitted. When there is multiple failures, the most severe is ...";
CM_ SG_ 2566714366 EngDsrdTrbCmprssrBypssActtor2Pos "The desired position of the Engine Turbocharger Compressor Bypass actuator 2 by the engine ECM, where 0% represents bypass fully closed and 100% represents bypass fully open.

This is the position that the device is attempting to achieve.";
CM_ SG_ 2566714366 EngTrbCmprssorBypassActuator2Pos "Measures the position of the turbocharger compressor bypass actuator 2, where 0% represents bypass fully closed and 100% represents bypass fully open. Typically, the compressor bypass is used to lower the compressor outlet pressure and/or intake ...";
CM_ BO_ 2566714110 "This PGN will be used to transmit the Feedback information from the Engine Throttle and Fuel Actuator.";
CM_ SG_ 2566714110 EngFuelValve2OperationStatus "Used to identify the status of Engine Fuel Valve 2
0000 – Normal
0001 – Alarm (fully operational but needs service)
0010 – Alarm High Severity (functional but transient performance may be reduced)
0011 – Derate Active (torque output reduced due ...";
CM_ SG_ 2566714110 EngFuelValve1OperationStatus "Used to identify the status of Engine Fuel Valve 1
0000 – Normal
0001 – Alarm (fully operational but needs service)
0010 – Alarm High Severity (functional but transient performance may be reduced)
0011 – Derate Active (torque output reduced due ...";
CM_ SG_ 2566714110 EngThrottleValve2OperationStatus "Used to identify the status of engine throttle valve 2 (SPN 3783)
0000 – Normal
0001 – Alarm (fully operational but needs service)
0010 – Alarm High Severity (functional but transient performance may be reduced)
0011 – Derate Active (torque ...";
CM_ SG_ 2566714110 EngThrottleValve1OperationStatus "Used to identify the status of engine throttle valve 1 (SPN 53)
0000 – Normal
0001 – Alarm (fully operational but needs service)
0010 – Alarm High Severity (functional but transient performance may be reduced)
0011 – Derate Active (torque output ...";
CM_ SG_ 2566714110 EngFuelValve2TempStatus "Used to identify the status of the Engine Fuel valve 2 drive circuitry temperature.  Temperature excursions may affect the torque output.
000 – High most severe
001 – High Least severe
010 – In Range
011 – Low Least severe
100 – Low Most severe
 ...";
CM_ SG_ 2566714110 EngFuelValve2PreliminaryFMI "Used to identify the applicable J1939-73 FMI detected in the Engine Fuel Valve 2 by the manufacturers software. When there is no failure FMI 31 is transmitted. When there is multiple failures, the most severe is transmitted.";
CM_ SG_ 2566714110 EngFuelValve1TempStatus "Used to identify the status of the Engine Fuel valve 1 drive circuitry temperature.  Temperature excursions may affect the torque output.
000 – High Most severe
001 – High Least severe
010 – In Range
011 – Low Least severe
100 – Low Most severe
 ...";
CM_ SG_ 2566714110 EngFuelValve1PreliminaryFMI "Used to identify the applicable J1939-73 FMI detected in the Engine Fuel Valve 1 by the manufacturers software. When there is no failure FMI 31 is transmitted. When there is multiple failures, the most severe is transmitted.";
CM_ SG_ 2566714110 EngThrottleValve2TempStatus "Used to identify the status of the Engine throttle valve 2 (SPN 3783) drive circuitry temperature.  Temperature excursions may affect the torque output.
000 – High Most severe
001 – High Least severe
010 – In Range
011 – Low Least severe
100 – ...";
CM_ SG_ 2566714110 EngThrottleValve2PreliminaryFMI "Used to identify the applicable J1939-73 FMI detected in the engine throttle valve 2 (SPN 3783) by the manufacturers software. When there is no failure FMI 31 is transmitted. When there is multiple failures, the most severe is transmitted.";
CM_ SG_ 2566714110 EngDesiredThrottleValve2Pos "The desired position of the engine throttle valve 2 (SPN 3783) that is regulating the fluid, usually air/fuel mixture to the engine as commanded by the Engine Control Unit.  0% represents no supply and 100% is full supply.
This is the position that ...";
CM_ SG_ 2566714110 EngThrottleValve1TempStatus "Used to identify the status of the engine throttle valve 1 (SPN 53) drive circuitry temperature.  Temperature excursions may affect the torque output.
000 – High most severe
001 – High Least severe
010 – In Range
011 – Low Least severe
100 – ...";
CM_ SG_ 2566714110 EngThrottleValve1PreliminaryFMI "Used to identify the applicable J1939-73 FMI detected in the engine throttle valve 1 (SPN 53) by the manufacturers software. When there is no failure FMI 31 is transmitted. When there is multiple failures, the most severe is transmitted.";
CM_ SG_ 2566714110 EngDesiredThrottleValve1Pos "The desired position of the Throttle valve 1 that is regulating the fluid, usually air/fuel mixture to the engine as commanded by the Engine Control unit.  0% represents no supply and 100% is full supply.
This is the position that the device is ...";
CM_ BO_ 2566717438 "Engine related parameters";
CM_ SG_ 2566717438 EngExhstGsRcrcltn2MxerIntakeTemp "The temperature of the EGR gas entering the intake of EGR2 system mixer.";
CM_ SG_ 2566717438 EngExhaustGasRecirculation2Temp "Temperature of Recirculated Exhaust Gas of EGR2";
CM_ BO_ 2633828606 "Engine oil related parameters";
CM_ SG_ 2633828606 EngOilTemp3 "Temperature of the engine lubricant.

Note:  If there is only one engine oil temperature measurement, SPN 175 should be used. 

See also SPNs 175 and 1135 for additional engine oil temperature measurements.";
CM_ SG_ 2633828606 EngOilRelativeDielectricity "Engine oil relative dielectricity used to describe the engine oil quality.";
CM_ SG_ 2633828606 EngOilDensity "Density of the engine oil";
CM_ SG_ 2633828606 EngOilViscosity "Dynamic viscosity of the engine oil";
CM_ BO_ 2499607550 "Engine manifold actuator position parameters";
CM_ SG_ 2499607550 EngExhstMnfldBnk2FlwBlncVlvActtr "Actual percentage of maximum Engine Manifold Bank 2 Balance valve opening. 0% means valve is closed. 100% means maximum valve opening (full gas flow).";
CM_ SG_ 2499607550 EngExhstMnfldBnk1FlwBlncVlvActtr "Actual percentage of maximum Engine Exhaust Manifold Bank 1 Balance valve opening. 0% means valve is closed. 100% means maximum valve opening (full gas flow).";
CM_ BO_ 2633825534 "Engine manifold actuator control parameters.";
CM_ SG_ 2633825534 EngExhstMnfldBnk2FlwBlncVlvActtr "Commanded percentage of maximum Engine Ehaust Manifold Bank 2 Balance valve opening. 0% means valve is closed. 100% means maximum valve opening (full gas flow).";
CM_ SG_ 2633825534 EngExhstMnfldBnk1FlwBlncVlvActtr "Commanded percentage of maximum Engine Exhaust Manifold Bank 1 Balance valve opening. 0% means valve is closed. 100% means maximum valve opening (full gas flow).";
CM_ BO_ 2365400574 "Used to transfer information about the measured status of three additional axes of a joystick and switches of the joystick grip or handle.  The joystick axial motion information is available in the Basic Joystick Message.
10-bit position parameters ...";
CM_ SG_ 2365400574 Jystick9GripXAxisDetentPosStatus "Reports when the current joystick grip position is in the detent position for that axis of travel.

00 Not in the Detent Position
01 In the Detent Position
10 Error Indicator
11 Not Available";
CM_ SG_ 2365400574 Jystick9GripYAxisDetentPosStatus "Reports when the current joystick grip position is in the detent position for that axis of travel.

00 Not in the Detent Position
01 In the Detent Position
10 Error Indicator
11 Not Available";
CM_ SG_ 2365400574 Jystick9ThetaAxisDetentPosStatus "Reports when the current joystick position is in the detent position for that axis of travel.

00 Not in the Detent Position
01 In the Detent Position
10 Error Indicator
11 Not Available";
CM_ SG_ 2365400574 Joystick9ThetaAxisPos "The position of the joystick in the relative motion of travel from the neutral position.  Position value of 0 is Neutral and position value 1000 (100%) is the end of linear zone.  Value of 1022 indicates an error has occurred.";
CM_ SG_ 2365400574 Jystck9ThtAxsClckwsPstvPosStatus "Reports when the current joystick position is on the positive travel side (forward, right, clockwise, up) relative to the neutral position for that axis of travel.
00 Not on Positive side of Neutral
01 On positive side of Neutral
10 Error ...";
CM_ SG_ 2365400574 Jystck9ThtAxsCntrClckwsNgtvPsStt "Reports when the current joystick position is on the negative travel side (back, left, counterclockwise, down) relative to the neutral position for that axis of travel.
00 Not on negative side of Neutral
01 On negative side of Neutral
10 Error ...";
CM_ SG_ 2365400574 Jystck9ThetaAxisNeutralPosStatus "Reports when the current joystick position is in the neutral position for that axis of travel.  The neutral position measurement must be determined from some mechanism other than the axis position measurement device.
00 Not in Neutral Position
01 ...";
CM_ SG_ 2365400574 Joystick9GripYAxisPos "The position of the joystick grip in the relative motion of travel from the neutral position.  Position value of 0 is Neutral and position value 1000 (100%) is the end of linear zone.  Value of 1022 indicates an error has occurred.";
CM_ SG_ 2365400574 Jystck9GrpYAxsLvrFrwrdPstvPsStts "Reports when the current joystick grip position is on the positive travel side (forward, right, clockwise, up) relative to the neutral position for that axis of travel.
00 Not on Positive side of Neutral
01 On positive side of Neutral
10 Error ...";
CM_ SG_ 2365400574 Jystck9GrpYAxsLvrBckNgtvPsStatus "Reports when the current joystick grip position is on the negative travel side (back, left, counterclockwise, down) relative to the neutral position for that axis of travel.
00 Not on negative side of Neutral
01 On negative side of Neutral
10 ...";
CM_ SG_ 2365400574 Jystck9GripYAxisNeutralPosStatus "Reports when the current joystick grip position is in the neutral position for that axis of travel.  The neutral position measurement must be determined from some mechanism other than the axis position measurement device.
00 Not in Neutral Position
 ...";
CM_ SG_ 2365400574 Joystick9GripXAxisPos "The position of the joystick grip in the relative motion of travel from the neutral position.  Position value of 0 is Neutral and position value 1000 (100%) is the end of linear zone.  Value of 1022 indicates an error has occurred.";
CM_ SG_ 2365400574 Jystck9GrpXAxsLvrRghtPstvPsSttus "Reports when the current joystick grip position is on the positive travel side (forward, right, clockwise, up) relative to the neutral position for that axis of travel.
00 Not on Positive side of Neutral
01 On positive side of Neutral
10 Error ...";
CM_ SG_ 2365400574 Jystck9GrpXAxsLvrLftNgtvPsStatus "Reports when the current joystick grip position is on the negative travel side (back, left, counterclockwise, down) relative to the neutral position for that axis of travel.
00 Not on negative side of Neutral
01 On negative side of Neutral
10 ...";
CM_ SG_ 2365400574 Jystck9GripXAxisNeutralPosStatus "Reports when the current joystick grip position is in the neutral position for that axis of travel.  The neutral position measurement must be determined from some mechanism other than the axis position measurement device.
00 Not in Neutral Position
 ...";
CM_ BO_ 2365401086 "Used to transfer information about the measured status of three additional axes of a joystick and switches of the joystick grip or handle.  The joystick axial motion information is available in the Basic Joystick Message.
10-bit position parameters ...";
CM_ SG_ 2365401086 Jystick8GripXAxisDetentPosStatus "Reports when the current joystick grip position is in the detent position for that axis of travel.

00 Not in the Detent Position
01 In the Detent Position
10 Error Indicator
11 Not Available";
CM_ SG_ 2365401086 Jystick8GripYAxisDetentPosStatus "Reports when the current joystick grip position is in the detent position for that axis of travel.

00 Not in the Detent Position
01 In the Detent Position
10 Error Indicator
11 Not Available";
CM_ SG_ 2365401086 Jystick8ThetaAxisDetentPosStatus "Reports when the current joystick position is in the detent position for that axis of travel.

00 Not in the Detent Position
01 In the Detent Position
10 Error Indicator
11 Not Available";
CM_ SG_ 2365401086 Joystick8ThetaAxisPos "The position of the joystick in the relative motion of travel from the neutral position.  Position value of 0 is Neutral and position value 1000 (100%) is the end of linear zone.  Value of 1022 indicates an error has occurred.";
CM_ SG_ 2365401086 Jystck8ThtAxsClckwsPstvPosStatus "Reports when the current joystick position is on the positive travel side (forward, right, clockwise, up) relative to the neutral position for that axis of travel.
00 Not on Positive side of Neutral
01 On positive side of Neutral
10 Error ...";
CM_ SG_ 2365401086 Jystck8ThtAxsCntrClckwsNgtvPsStt "Reports when the current joystick position is on the negative travel side (back, left, counterclockwise, down) relative to the neutral position for that axis of travel.
00 Not on negative side of Neutral
01 On negative side of Neutral
10 Error ...";
CM_ SG_ 2365401086 Jystck8ThetaAxisNeutralPosStatus "Reports when the current joystick position is in the neutral position for that axis of travel.  The neutral position measurement must be determined from some mechanism other than the axis position measurement device.
00 Not in Neutral Position
01 ...";
CM_ SG_ 2365401086 Joystick8GripYAxisPos "The position of the joystick grip in the relative motion of travel from the neutral position.  Position value of 0 is Neutral and position value 1000 (100%) is the end of linear zone.  Value of 1022 indicates an error has occurred.";
CM_ SG_ 2365401086 Jystck8GrpYAxsLvrFrwrdPstvPsStts "Reports when the current joystick grip position is on the positive travel side (forward, right, clockwise, up) relative to the neutral position for that axis of travel.
00 Not on Positive side of Neutral
01 On positive side of Neutral
10 Error ...";
CM_ SG_ 2365401086 Jystck8GrpYAxsLvrBckNgtvPsStatus "Reports when the current joystick grip position is on the negative travel side (back, left, counterclockwise, down) relative to the neutral position for that axis of travel.
00 Not on negative side of Neutral
01 On negative side of Neutral
10 ...";
CM_ SG_ 2365401086 Jystck8GripYAxisNeutralPosStatus "Reports when the current joystick grip position is in the neutral position for that axis of travel.  The neutral position measurement must be determined from some mechanism other than the axis position measurement device.
00 Not in Neutral Position
 ...";
CM_ SG_ 2365401086 Joystick8GripXAxisPos "The position of the joystick grip in the relative motion of travel from the neutral position.  Position value of 0 is Neutral and position value 1000 (100%) is the end of linear zone.  Value of 1022 indicates an error has occurred.";
CM_ SG_ 2365401086 Jystck8GrpXAxsLvrRghtPstvPsSttus "Reports when the current joystick grip position is on the positive travel side (forward, right, clockwise, up) relative to the neutral position for that axis of travel.
00 Not on Positive side of Neutral
01 On positive side of Neutral
10 Error ...";
CM_ SG_ 2365401086 Jystck8GrpXAxsLvrLftNgtvPsStatus "Reports when the current joystick grip position is on the negative travel side (back, left, counterclockwise, down) relative to the neutral position for that axis of travel.
00 Not on negative side of Neutral
01 On negative side of Neutral
10 ...";
CM_ SG_ 2365401086 Jystck8GripXAxisNeutralPosStatus "Reports when the current joystick grip position is in the neutral position for that axis of travel.  The neutral position measurement must be determined from some mechanism other than the axis position measurement device.
00 Not in Neutral Position
 ...";
CM_ BO_ 2365401598 "Used to transfer information about the measured status of three additional axes of a joystick and switches of the joystick grip or handle.  The joystick axial motion information is available in the Basic Joystick Message.
10-bit position parameters ...";
CM_ SG_ 2365401598 Jystick7GripXAxisDetentPosStatus "Reports when the current joystick grip position is in the detent position for that axis of travel.

00 Not in the Detent Position
01 In the Detent Position
10 Error Indicator
11 Not Available";
CM_ SG_ 2365401598 Jystick7GripYAxisDetentPosStatus "Reports when the current joystick grip position is in the detent position for that axis of travel.

00 Not in the Detent Position
01 In the Detent Position
10 Error Indicator
11 Not Available";
CM_ SG_ 2365401598 Jystick7ThetaAxisDetentPosStatus "Reports when the current joystick position is in the detent position for that axis of travel.

00 Not in the Detent Position
01 In the Detent Position
10 Error Indicator
11 Not Available";
CM_ SG_ 2365401598 Joystick7ThetaAxisPos "The position of the joystick in the relative motion of travel from the neutral position.  Position value of 0 is Neutral and position value 1000 (100%) is the end of linear zone.  Value of 1022 indicates an error has occurred.";
CM_ SG_ 2365401598 Jystck7ThtAxsClckwsPstvPosStatus "Reports when the current joystick position is on the positive travel side (forward, right, clockwise, up) relative to the neutral position for that axis of travel.
00 Not on Positive side of Neutral
01 On positive side of Neutral
10 Error ...";
CM_ SG_ 2365401598 Jystck7ThtAxsCntrClckwsNgtvPsStt "Reports when the current joystick position is on the negative travel side (back, left, counterclockwise, down) relative to the neutral position for that axis of travel.
00 Not on negative side of Neutral
01 On negative side of Neutral
10 Error ...";
CM_ SG_ 2365401598 Jystck7ThetaAxisNeutralPosStatus "Reports when the current joystick position is in the neutral position for that axis of travel.  The neutral position measurement must be determined from some mechanism other than the axis position measurement device.
00 Not in Neutral Position
01 ...";
CM_ SG_ 2365401598 Joystick7GripYAxisPos "The position of the joystick grip in the relative motion of travel from the neutral position.  Position value of 0 is Neutral and position value 1000 (100%) is the end of linear zone.  Value of 1022 indicates an error has occurred.";
CM_ SG_ 2365401598 Jystck7GrpYAxsLvrFrwrdPstvPsStts "Reports when the current joystick grip position is on the positive travel side (forward, right, clockwise, up) relative to the neutral position for that axis of travel.
00 Not on Positive side of Neutral
01 On positive side of Neutral
10 Error ...";
CM_ SG_ 2365401598 Jystck7GrpYAxsLvrBckNgtvPsStatus "Reports when the current joystick grip position is on the negative travel side (back, left, counterclockwise, down) relative to the neutral position for that axis of travel.
00 Not on negative side of Neutral
01 On negative side of Neutral
10 ...";
CM_ SG_ 2365401598 Jystck7GripYAxisNeutralPosStatus "Reports when the current joystick grip position is in the neutral position for that axis of travel.  The neutral position measurement must be determined from some mechanism other than the axis position measurement device.
00 Not in Neutral Position
 ...";
CM_ SG_ 2365401598 Joystick7GripXAxisPos "The position of the joystick grip in the relative motion of travel from the neutral position.  Position value of 0 is Neutral and position value 1000 (100%) is the end of linear zone.  Value of 1022 indicates an error has occurred.";
CM_ SG_ 2365401598 Jystck7GrpXAxsLvrRghtPstvPsSttus "Reports when the current joystick grip position is on the positive travel side (forward, right, clockwise, up) relative to the neutral position for that axis of travel.
00 Not on Positive side of Neutral
01 On positive side of Neutral
10 Error ...";
CM_ SG_ 2365401598 Jystck7GrpXAxsLvrLftNgtvPsStatus "Reports when the current joystick grip position is on the negative travel side (back, left, counterclockwise, down) relative to the neutral position for that axis of travel.
00 Not on negative side of Neutral
01 On negative side of Neutral
10 ...";
CM_ SG_ 2365401598 Jystck7GripXAxisNeutralPosStatus "Reports when the current joystick grip position is in the neutral position for that axis of travel.  The neutral position measurement must be determined from some mechanism other than the axis position measurement device.
00 Not in Neutral Position
 ...";
CM_ BO_ 2365402110 "Used to transfer information about the measured status of three additional axes of a joystick and switches of the joystick grip or handle.  The joystick axial motion information is available in the Basic Joystick Message.
10-bit position parameters ...";
CM_ SG_ 2365402110 Jystick6GripXAxisDetentPosStatus "Reports when the current joystick grip position is in the detent position for that axis of travel.

00 Not in the Detent Position
01 In the Detent Position
10 Error Indicator
11 Not Available";
CM_ SG_ 2365402110 Jystick6GripYAxisDetentPosStatus "Reports when the current joystick grip position is in the detent position for that axis of travel.

00 Not in the Detent Position
01 In the Detent Position
10 Error Indicator
11 Not Available";
CM_ SG_ 2365402110 Jystick6ThetaAxisDetentPosStatus "Reports when the current joystick position is in the detent position for that axis of travel.

00 Not in the Detent Position
01 In the Detent Position
10 Error Indicator
11 Not Available";
CM_ SG_ 2365402110 Joystick6ThetaAxisPos "The position of the joystick in the relative motion of travel from the neutral position.  Position value of 0 is Neutral and position value 1000 (100%) is the end of linear zone.  Value of 1022 indicates an error has occurred.";
CM_ SG_ 2365402110 Jystck6ThtAxsClckwsPstvPosStatus "Reports when the current joystick position is on the positive travel side (forward, right, clockwise, up) relative to the neutral position for that axis of travel.
00 Not on Positive side of Neutral
01 On positive side of Neutral
10 Error ...";
CM_ SG_ 2365402110 Jystck6ThtAxsCntrClckwsNgtvPsStt "Reports when the current joystick position is on the negative travel side (back, left, counterclockwise, down) relative to the neutral position for that axis of travel.
00 Not on negative side of Neutral
01 On negative side of Neutral
10 Error ...";
CM_ SG_ 2365402110 Jystck6ThetaAxisNeutralPosStatus "Reports when the current joystick position is in the neutral position for that axis of travel.  The neutral position measurement must be determined from some mechanism other than the axis position measurement device.
00 Not in Neutral Position
01 ...";
CM_ SG_ 2365402110 Joystick6GripYAxisPos "The position of the joystick grip in the relative motion of travel from the neutral position.  Position value of 0 is Neutral and position value 1000 (100%) is the end of linear zone.  Value of 1022 indicates an error has occurred.";
CM_ SG_ 2365402110 Jystck6GrpYAxsLvrFrwrdPstvPsStts "Reports when the current joystick grip position is on the positive travel side (forward, right, clockwise, up) relative to the neutral position for that axis of travel.
00 Not on Positive side of Neutral
01 On positive side of Neutral
10 Error ...";
CM_ SG_ 2365402110 Jystck6GrpYAxsLvrBckNgtvPsStatus "Reports when the current joystick grip position is on the negative travel side (back, left, counterclockwise, down) relative to the neutral position for that axis of travel.
00 Not on negative side of Neutral
01 On negative side of Neutral
10 ...";
CM_ SG_ 2365402110 Jystck6GripYAxisNeutralPosStatus "Reports when the current joystick grip position is in the neutral position for that axis of travel.  The neutral position measurement must be determined from some mechanism other than the axis position measurement device.
00 Not in Neutral Position
 ...";
CM_ SG_ 2365402110 Joystick6GripXAxisPos "The position of the joystick grip in the relative motion of travel from the neutral position.  Position value of 0 is Neutral and position value 1000 (100%) is the end of linear zone.  Value of 1022 indicates an error has occurred.";
CM_ SG_ 2365402110 Jystck6GrpXAxsLvrRghtPstvPsSttus "Reports when the current joystick grip position is on the positive travel side (forward, right, clockwise, up) relative to the neutral position for that axis of travel.
00 Not on Positive side of Neutral
01 On positive side of Neutral
10 Error ...";
CM_ SG_ 2365402110 Jystck6GrpXAxsLvrLftNgtvPsStatus "Reports when the current joystick grip position is on the negative travel side (back, left, counterclockwise, down) relative to the neutral position for that axis of travel.
00 Not on negative side of Neutral
01 On negative side of Neutral
10 ...";
CM_ SG_ 2365402110 Jystck6GripXAxisNeutralPosStatus "Reports when the current joystick grip position is in the neutral position for that axis of travel.  The neutral position measurement must be determined from some mechanism other than the axis position measurement device.
00 Not in Neutral Position
 ...";
CM_ BO_ 2365402622 "Used to transfer information about the measured status of three additional axes of a joystick and switches of the joystick grip or handle.  The joystick axial motion information is available in the Basic Joystick Message.
10-bit position parameters ...";
CM_ SG_ 2365402622 Jystick5GripXAxisDetentPosStatus "Reports when the current joystick grip position is in the detent position for that axis of travel.

00 Not in the Detent Position
01 In the Detent Position
10 Error Indicator
11 Not Available";
CM_ SG_ 2365402622 Jystick5GripYAxisDetentPosStatus "Reports when the current joystick grip position is in the detent position for that axis of travel.

00 Not in the Detent Position
01 In the Detent Position
10 Error Indicator
11 Not Available";
CM_ SG_ 2365402622 Jystick5ThetaAxisDetentPosStatus "Reports when the current joystick position is in the detent position for that axis of travel.

00 Not in the Detent Position
01 In the Detent Position
10 Error Indicator
11 Not Available";
CM_ SG_ 2365402622 Joystick5ThetaAxisPos "The position of the joystick in the relative motion of travel from the neutral position.  Position value of 0 is Neutral and position value 1000 (100%) is the end of linear zone.  Value of 1022 indicates an error has occurred.";
CM_ SG_ 2365402622 Jystck5ThtAxsClckwsPstvPosStatus "Reports when the current joystick position is on the positive travel side (forward, right, clockwise, up) relative to the neutral position for that axis of travel.
00 Not on Positive side of Neutral
01 On positive side of Neutral
10 Error ...";
CM_ SG_ 2365402622 Jystck5ThtAxsCntrClckwsNgtvPsStt "Reports when the current joystick position is on the negative travel side (back, left, counterclockwise, down) relative to the neutral position for that axis of travel.
00 Not on negative side of Neutral
01 On negative side of Neutral
10 Error ...";
CM_ SG_ 2365402622 Jystck5ThetaAxisNeutralPosStatus "Reports when the current joystick position is in the neutral position for that axis of travel.  The neutral position measurement must be determined from some mechanism other than the axis position measurement device.
00 Not in Neutral Position
01 ...";
CM_ SG_ 2365402622 Joystick5GripYAxisPos "The position of the joystick grip in the relative motion of travel from the neutral position.  Position value of 0 is Neutral and position value 1000 (100%) is the end of linear zone.  Value of 1022 indicates an error has occurred.";
CM_ SG_ 2365402622 Jystck5GrpYAxsLvrFrwrdPstvPsStts "Reports when the current joystick grip position is on the positive travel side (forward, right, clockwise, up) relative to the neutral position for that axis of travel.
00 Not on Positive side of Neutral
01 On positive side of Neutral
10 Error ...";
CM_ SG_ 2365402622 Jystck5GrpYAxsLvrBckNgtvPsStatus "Reports when the current joystick grip position is on the negative travel side (back, left, counterclockwise, down) relative to the neutral position for that axis of travel.
00 Not on negative side of Neutral
01 On negative side of Neutral
10 ...";
CM_ SG_ 2365402622 Jystck5GripYAxisNeutralPosStatus "Reports when the current joystick grip position is in the neutral position for that axis of travel.  The neutral position measurement must be determined from some mechanism other than the axis position measurement device.
00 Not in Neutral Position
 ...";
CM_ SG_ 2365402622 Joystick5GripXAxisPos "The position of the joystick grip in the relative motion of travel from the neutral position.  Position value of 0 is Neutral and position value 1000 (100%) is the end of linear zone.  Value of 1022 indicates an error has occurred.";
CM_ SG_ 2365402622 Jystck5GrpXAxsLvrRghtPstvPsSttus "Reports when the current joystick grip position is on the positive travel side (forward, right, clockwise, up) relative to the neutral position for that axis of travel.
00 Not on Positive side of Neutral
01 On positive side of Neutral
10 Error ...";
CM_ SG_ 2365402622 Jystck5GrpXAxsLvrLftNgtvPsStatus "Reports when the current joystick grip position is on the negative travel side (back, left, counterclockwise, down) relative to the neutral position for that axis of travel.
00 Not on negative side of Neutral
01 On negative side of Neutral
10 ...";
CM_ SG_ 2365402622 Jystck5GripXAxisNeutralPosStatus "Reports when the current joystick grip position is in the neutral position for that axis of travel.  The neutral position measurement must be determined from some mechanism other than the axis position measurement device.
00 Not in Neutral Position
 ...";
CM_ BO_ 2365403134 "Used to transfer information about the measured status of three additional axes of a joystick and switches of the joystick grip or handle.  The joystick axial motion information is available in the Basic Joystick Message.
10-bit position parameters ...";
CM_ SG_ 2365403134 Jystick4GripXAxisDetentPosStatus "Reports when the current joystick grip position is in the detent position for that axis of travel.

00 Not in the Detent Position
01 In the Detent Position
10 Error Indicator
11 Not Available";
CM_ SG_ 2365403134 Jystick4GripYAxisDetentPosStatus "Reports when the current joystick grip position is in the detent position for that axis of travel.

00 Not in the Detent Position
01 In the Detent Position
10 Error Indicator
11 Not Available";
CM_ SG_ 2365403134 Jystick4ThetaAxisDetentPosStatus "Reports when the current joystick position is in the detent position for that axis of travel.

00 Not in the Detent Position
01 In the Detent Position
10 Error Indicator
11 Not Available";
CM_ SG_ 2365403134 Joystick4ThetaAxisPos "The position of the joystick in the relative motion of travel from the neutral position.  Position value of 0 is Neutral and position value 1000 (100%) is the end of linear zone.  Value of 1022 indicates an error has occurred.";
CM_ SG_ 2365403134 Jystck4ThtAxsClckwsPstvPosStatus "Reports when the current joystick position is on the positive travel side (forward, right, clockwise, up) relative to the neutral position for that axis of travel.
00 Not on Positive side of Neutral
01 On positive side of Neutral
10 Error ...";
CM_ SG_ 2365403134 Jystck4ThtAxsCntrClckwsNgtvPsStt "Reports when the current joystick position is on the negative travel side (back, left, counterclockwise, down) relative to the neutral position for that axis of travel.
00 Not on negative side of Neutral
01 On negative side of Neutral
10 Error ...";
CM_ SG_ 2365403134 Jystck4ThetaAxisNeutralPosStatus "Reports when the current joystick position is in the neutral position for that axis of travel.  The neutral position measurement must be determined from some mechanism other than the axis position measurement device.
00 Not in Neutral Position
01 ...";
CM_ SG_ 2365403134 Joystick4GripYAxisPos "The position of the joystick grip in the relative motion of travel from the neutral position.  Position value of 0 is Neutral and position value 1000 (100%) is the end of linear zone.  Value of 1022 indicates an error has occurred.";
CM_ SG_ 2365403134 Jystck4GrpYAxsLvrFrwrdPstvPsStts "Reports when the current joystick grip position is on the positive travel side (forward, right, clockwise, up) relative to the neutral position for that axis of travel.
00 Not on Positive side of Neutral
01 On positive side of Neutral
10 Error ...";
CM_ SG_ 2365403134 Jystck4GrpYAxsLvrBckNgtvPsStatus "Reports when the current joystick grip position is on the negative travel side (back, left, counterclockwise, down) relative to the neutral position for that axis of travel.
00 Not on negative side of Neutral
01 On negative side of Neutral
10 ...";
CM_ SG_ 2365403134 Jystck4GripYAxisNeutralPosStatus "Reports when the current joystick grip position is in the neutral position for that axis of travel.  The neutral position measurement must be determined from some mechanism other than the axis position measurement device.
00 Not in Neutral Position
 ...";
CM_ SG_ 2365403134 Joystick4GripXAxisPos "The position of the joystick grip in the relative motion of travel from the neutral position.  Position value of 0 is Neutral and position value 1000 (100%) is the end of linear zone.  Value of 1022 indicates an error has occurred.";
CM_ SG_ 2365403134 Jystck4GrpXAxsLvrRghtPstvPsSttus "Reports when the current joystick grip position is on the positive travel side (forward, right, clockwise, up) relative to the neutral position for that axis of travel.
00 Not on Positive side of Neutral
01 On positive side of Neutral
10 Error ...";
CM_ SG_ 2365403134 Jystck4GrpXAxsLvrLftNgtvPsStatus "Reports when the current joystick grip position is on the negative travel side (back, left, counterclockwise, down) relative to the neutral position for that axis of travel.
00 Not on negative side of Neutral
01 On negative side of Neutral
10 ...";
CM_ SG_ 2365403134 Jystck4GripXAxisNeutralPosStatus "Reports when the current joystick grip position is in the neutral position for that axis of travel.  The neutral position measurement must be determined from some mechanism other than the axis position measurement device.
00 Not in Neutral Position
 ...";
CM_ BO_ 2365400062 "Used to transfer information about the measured status of three additional axes of a joystick and switches of the joystick grip or handle.  The joystick axial motion information is available in the Basic Joystick Message.
10-bit position parameters ...";
CM_ SG_ 2365400062 Jystck10GripXAxisDetentPosStatus "Reports when the current joystick grip position is in the detent position for that axis of travel.

00 Not in the Detent Position
01 In the Detent Position
10 Error Indicator
11 Not Available";
CM_ SG_ 2365400062 Jystck10GripYAxisDetentPosStatus "Reports when the current joystick grip position is in the detent position for that axis of travel.

00 Not in the Detent Position
01 In the Detent Position
10 Error Indicator
11 Not Available";
CM_ SG_ 2365400062 Jystck10ThetaAxisDetentPosStatus "Reports when the current joystick position is in the detent position for that axis of travel.

00 Not in the Detent Position
01 In the Detent Position
10 Error Indicator
11 Not Available";
CM_ SG_ 2365400062 Joystick10ThetaAxisPos "The position of the joystick in the relative motion of travel from the neutral position.  Position value of 0 is Neutral and position value 1000 (100%) is the end of linear zone.  Value of 1022 indicates an error has occurred.";
CM_ SG_ 2365400062 Jystck10ThtAxsClckwsPstvPsStatus "Reports when the current joystick position is on the positive travel side (forward, right, clockwise, up) relative to the neutral position for that axis of travel.
00 Not on Positive side of Neutral
01 On positive side of Neutral
10 Error ...";
CM_ SG_ 2365400062 Jystck10ThtAxsCntrClckwsNgtvPsSt "Reports when the current joystick position is on the negative travel side (back, left, counterclockwise, down) relative to the neutral position for that axis of travel.
00 Not on negative side of Neutral
01 On negative side of Neutral
10 Error ...";
CM_ SG_ 2365400062 Jystck10ThtaAxisNeutralPosStatus "Reports when the current joystick position is in the neutral position for that axis of travel.  The neutral position measurement must be determined from some mechanism other than the axis position measurement device.
00 Not in Neutral Position
01 ...";
CM_ SG_ 2365400062 Joystick10GripYAxisPos "The position of the joystick grip in the relative motion of travel from the neutral position.  Position value of 0 is Neutral and position value 1000 (100%) is the end of linear zone.  Value of 1022 indicates an error has occurred.";
CM_ SG_ 2365400062 Jystck10GrpYAxsLvrFrwrdPstvPsStt "Reports when the current joystick grip position is on the positive travel side (forward, right, clockwise, up) relative to the neutral position for that axis of travel.
00 Not on Positive side of Neutral
01 On positive side of Neutral
10 Error ...";
CM_ SG_ 2365400062 Jystck10GrpYAxsLvrBckNgtvPsSttus "Reports when the current joystick grip position is on the negative travel side (back, left, counterclockwise, down) relative to the neutral position for that axis of travel.
00 Not on negative side of Neutral
01 On negative side of Neutral
10 ...";
CM_ SG_ 2365400062 Jystck10GrpYAxisNeutralPosStatus "Reports when the current joystick grip position is in the neutral position for that axis of travel.  The neutral position measurement must be determined from some mechanism other than the axis position measurement device.
00 Not in Neutral Position
 ...";
CM_ SG_ 2365400062 Joystick10GripXAxisPos "The position of the joystick grip in the relative motion of travel from the neutral position.  Position value of 0 is Neutral and position value 1000 (100%) is the end of linear zone.  Value of 1022 indicates an error has occurred.";
CM_ SG_ 2365400062 Jystck10GrpXAxsLvrRghtPstvPsStts "Reports when the current joystick grip position is on the positive travel side (forward, right, clockwise, up) relative to the neutral position for that axis of travel.
00 Not on Positive side of Neutral
01 On positive side of Neutral
10 Error ...";
CM_ SG_ 2365400062 Jystck10GrpXAxsLvrLftNgtvPsSttus "Reports when the current joystick grip position is on the negative travel side (back, left, counterclockwise, down) relative to the neutral position for that axis of travel.
00 Not on negative side of Neutral
01 On negative side of Neutral
10 ...";
CM_ SG_ 2365400062 Jystck10GrpXAxisNeutralPosStatus "Reports when the current joystick grip position is in the neutral position for that axis of travel.  The neutral position measurement must be determined from some mechanism other than the axis position measurement device.
00 Not in Neutral Position
 ...";
CM_ BO_ 2566713598 "Contains information on the engine fuel and lube system";
CM_ SG_ 2566713598 EngFuelFilterIntakeAbsPress "Absolute pressure of fuel at the intake of the fuel filter (suction side) located between the fuel tank and the fuel supply pump.  See Figures SPN16_A & SPN16_B.";
CM_ BO_ 2499604478 "Engine related parameters.";
CM_ SG_ 2499604478 EngExhstGsRcrcltn1OutletAbsPress "EGR outlet absolute pressure is measured after the EGR 1 valve. See SPN 5019 for 1 byte resolution.";
CM_ SG_ 2499604478 EngExhstGsRcrcltn1IntakeAbsPress "EGR intake absolute pressure measured before the EGR 1 valve.";
CM_ BO_ 2499608830 "Engine related parameters";
CM_ SG_ 2499608830 EngCoolantPress2 "Gage pressure of liquid found in the engine coolant system - second instance";
CM_ SG_ 2499608830 EngExhstGsRcrcltn2IntakeAbsPress "EGR intake absolute pressure measured before the EGR 2 valve.";
CM_ SG_ 2499608830 EngExhstGsRcrcltn2OutletAbsPress "Absolute Pressure immediately after the EGR2 valve";
CM_ SG_ 2499608830 EngExhstGsRcrclation2IntakePress "EGR2 intake gauge pressure is measured after EGR2 cooler and before EGR2 valve";
CM_ SG_ 2499608830 EngExhstGsRcirculation2DiffPress "Differential Pressure across the Exhaust Gas Recirculation 2 (EGR2) system.";
CM_ BO_ 2432499198 "Engine related parameters";
CM_ SG_ 2432499198 CmmndedEngFuelInjectionCtrlPress "Provides the commanded set point value for the engine fuel injection control pressure.";
CM_ SG_ 2432499198 CommandedEngFuelRailPress "Provides the commanded set point value for the engine fuel rail gage pressure";
CM_ SG_ 2432499198 EngExhstGsRcirculation2Valve2Pos "The position of the second exhaust gas recirculation valve of EGR 2 expressed as a percentage of full travel. 0% means the valve is closed and no exhaust gas is flowing into the air stream. 100% means the valve is fully opened.";
CM_ SG_ 2432499198 EngExhstGsRecirculation2ValvePos "Position of EGR2 valve expressed as a percentage of full travel. 0% means the valve is closed and no exhaust gas is flowing into the air stream. 100% means the valve is fully opened.";
CM_ BO_ 2633825022 "Engine related parameters";
CM_ SG_ 2633825022 EngExhstGsRcrcltn2Valve2PosError "The position error of the Exhaust Gas Recirculation 2 valve 2, determined as the actual position (SPN 5265) minus the commanded position (SPN 5263).";
CM_ SG_ 2633825022 EngExhstGsRcrcltn2Valve1PosError "The position error of the Exhaust Gas Recirculation 2 valve, determined as the actual position (SPN 5264) minus the commanded position (SPN 5262).";
CM_ SG_ 2633825022 EngExhstGsRcrculation2Valve2Ctrl "Desired percentage of maximum Exhaust Gas Recirculation 2 (EGR2) valve 2 opening. 0% means the valve is closed. 100% means maximum opening (full gas flow).";
CM_ SG_ 2633825022 EngExhstGsRcirculation2ValveCtrl "Desired percentage of maximum Exhaust Gas Recirculation 2 (EGR2) valve opening. 0% means the valve is closed. 100% means maximum opening (full gas flow).";
CM_ BO_ 2633826046 "Engine related parameters";
CM_ SG_ 2633826046 EGR2CoolerBypassActuatorPos "EGR2 Cooler Bypass Actuator position, where 0% = Fully Closed (no gas flowing through the bypass), and 100% = Fully Open..";
CM_ SG_ 2633826046 EngExhstGsRcrcltn2ClerEfficiency "Exhaust Gas Recirculation 2 cooler efficiency is an indication of the cooler’s ability to reduce the temperature of the exhaust gas that is being recirculated back to the intake. 0% = no reduction in temperature, 100% = maximum cooling. The EGR 2 ...";
CM_ SG_ 2633826046 EngExhstGsRcrcltn2ClrIntkGsAbsPr "Exhaust Gas Recirculation 2 gas absolute pressure is measured at EGR2 cooler intake. See SPN 5253 for EGR2 pressure measured at the EGR2 cooler outlet before the valve.";
CM_ SG_ 2633826046 EngExhstGsRcrcltn2ClerIntakeTemp "Exhaust Gas Recirculation 2 (EGR2) Temperature measured at EGR2 cooler intake. See SPN 5255 for Engine EGR2 temperature.";
CM_ BO_ 2566711294 "The EC3 message contains a static engine friction torque map consisting of torque points that correspond to the speed points in the EC1 message.  A net brake torque map for the engine can be calculated by subtracting the static engine friction ...";
CM_ SG_ 2566711294 EngFrictionPercentTorquePoint7 "The static portion of the friction torque at speed point 7 (SPN 533) of the engine torque map in the engine configuration message.  This parameter does not include Estimated Pumping – Percent Torque (SPN 5398) and is expected to change with ...";
CM_ SG_ 2566711294 EngFrictionPercentTorquePoint6 "For engine configuration map modes 1 and 2, this is the static portion of the friction torque at speed point 6 (SPN 532) of the engine torque map.  For engine configuration map mode 3, this parameter is the static portion of the friction torque at ...";
CM_ SG_ 2566711294 EngFrictionPercentTorquePoint5 "The static portion of the friction torque at speed point 5 (SPN 531) of the engine torque map in the engine configuration message.  This parameter does not include Estimated Pumping – Percent Torque (SPN 5398) and is expected to change with ...";
CM_ SG_ 2566711294 EngFrictionPercentTorquePoint4 "The static portion of the friction torque at speed point 4 (SPN 530) of the engine torque map in the engine configuration message.  This parameter does not include Estimated Pumping – Percent Torque (SPN 5398) and is expected to change with ...";
CM_ SG_ 2566711294 EngFrictionPercentTorquePoint3 "The static portion of the friction torque at speed point 3 (SPN 529) of the engine torque map in the engine configuration message.  This parameter does not include Estimated Pumping – Percent Torque (SPN 5398) and is expected to change with ...";
CM_ SG_ 2566711294 EngFrictionPercentTorquePoint2 "The static portion of the friction torque at speed point 2 (SPN 528) of the engine torque map in the engine configuration message.  This parameter does not include Estimated Pumping – Percent Torque (SPN 5398) and is expected to change with ...";
CM_ SG_ 2566711294 EngFrctnPrcentTorqueAtIdlePoint1 "The static portion of the friction torque at speed point 1 (SPN 188) of the engine torque map in the engine configuration message.  This parameter does not include Estimated Pumping – Percent Torque (SPN 5398) and is expected to change with ...";
CM_ BO_ 2566749438 "This PGN contains information about the diesel particulate filter regeneration control.
If there are aftertreatment systems on two banks, this PGN represents the composite information from both banks.
NOTE: This message will be transmitted by the ...";
CM_ SG_ 2566749438 DslPrtcltFltrActvRgnrtnInhbt5629 "Indicates the state of diesel particulate filter active regeneration inhibition due to low exhaust pressure.
00 not inhibited
01 inhibited
10 reserved for SAE assignment
11 not available
This SPN indicates the reason for the diesel particulate ...";
CM_ SG_ 2566749438 DslPrtcltFltr1CndtnsNtMtFrActvRg "Indicates that diesel particulate filter 1 is not able to begin or continue an active regenerate event at the current engine operating conditions.
00 active DPF regeneration not inhibited
01 active DPF regeneration inhibited
10 reserved for SAE ...";
CM_ SG_ 2566749438 HydrocarbonDoserPurgingEnable "Purging enable of the Hydrocarbon Doser (HCD).

00 Purging not enabled
01 Purging enabled - less urgent
10 Purging enabled - urgent
11 Not available";
CM_ SG_ 2566749438 DslPrtcltFltrActvRgnrtnFrcdSttus "Indicates the forced execution status of diesel particulate filter regeneration.
000 Not Active
001 Active – Forced by Switch (See SPN 3696)
010 Active – Forced by Service Tool
011 Reserved for SAE Assignment
100 Reserved for SAE Assignment
 ...";
CM_ SG_ 2566749438 ExhaustSystemHighTempLampCmd "Command to control the exhaust system high temperature lamp.  This lamp indicates that the exhaust system temperature is high.
000 Off
001 On – solid
010 reserved for SAE assignment
011 reserved for SAE assignment
100 reserved for SAE ...";
CM_ SG_ 2566749438 DslPrtcltFltrAtmtcActvRgnrtnIntt "Indicates the configuration of diesel particulate filter active regeneration automatic initiation.

00 not enabled
01 enabled
10 reserved for SAE assignment
11 not available";
CM_ SG_ 2566749438 DslPrtcltFltrActvRgnrtnInhbt3717 "Indicates the state of diesel particulate filter active regeneration inhibition due to vehicle speed being less than the allowed vehicle speed.
00 not inhibited
01 inhibited
10 reserved for SAE assignment
11 not available
This SPN indicates the ...";
CM_ SG_ 2566749438 DslPrtcltFltrActvRgnrtnInhbtdDTE "Indicates the state of diesel particulate filter active regeneration inhibition due to the engine not being warmed up.
00 not inhibited
01 inhibited
10 reserved for SAE assignment
11 not available
This SPN indicates the reason for the diesel ...";
CM_ SG_ 2566749438 DslPrtcltFltrActvRgnrtnInhbt3715 "Indicates the state of diesel particulate filter active regeneration inhibition due to a permanent system lockout.
00 not inhibited
01 inhibited
10 reserved for SAE assignment
11 not available
This SPN indicates the reason for the diesel ...";
CM_ SG_ 2566749438 DslPrtcltFltrActvRgnrtnInhbtdDTT "Indicates the state of diesel particulate filter active regeneration inhibition due to a temporary system lockout.
00 not inhibited
01 inhibited
10 reserved for SAE assignment
11 not available
This SPN indicates the reason for the diesel ...";
CM_ SG_ 2566749438 DslPrtcltFltrActvRgnrtnInhbt3713 "Indicates the state of diesel particulate filter active regeneration inhibition due to a system timeout.
00 not inhibited
01 inhibited
10 reserved for SAE assignment
11 not available
This SPN indicates the reason for the diesel particulate ...";
CM_ SG_ 2566749438 DslPrtcltFltrActvRgnrtnInhbt3712 "Indicates the state of diesel particulate filter active regeneration inhibition due to a system fault being active.
00 not inhibited
01 inhibited
10 reserved for SAE assignment
11 not available
This SPN indicates the reason for the diesel ...";
CM_ SG_ 2566749438 DslPrtcltFltrActvRgnrtnInhbtdDTL "Indicates the state of diesel particulate filter active regeneration inhibition due to the exhaust temperature being too low.  This implies that the diesel particulate filter and/or oxidation catalyst are likewise too cold for active regeneration.
 ...";
CM_ SG_ 2566749438 DslPrtcltFltrActvRgnrtnInhbt3710 "Indicates the state of diesel particulate filter active regeneration inhibition due to the parking brake being not set.
00 not inhibited
01 inhibited
10 reserved for SAE assignment
11 not available
This SPN indicates the reason for the diesel ...";
CM_ SG_ 2566749438 DslPrtcltFltrActvRgnrtnInhbtdDTV "Indicates the state of diesel particulate filter active regeneration inhibition due to the vehicle speed being above an allowed limit.
00 not inhibited
01 inhibited
10 reserved for SAE assignment
11 not available
This SPN indicates the reason ...";
CM_ SG_ 2566749438 DslPrtcltFltrActvRgnrtnInhbtdDTO "Indicates the state of diesel particulate filter active regeneration inhibition due to the transmission being out of neutral.
00 not inhibited
01 inhibited
10 reserved for SAE assignment
11 not available
This SPN indicates the reason for the ...";
CM_ SG_ 2566749438 DslPrtcltFltrActvRgnrtnInhbtdDTA "Indicates the state of diesel particulate filter active regeneration inhibition due to the accelerator pedal being off idle.
00 not inhibited
01 inhibited
10 reserved for SAE assignment
11 not available
This SPN indicates the reason for the ...";
CM_ SG_ 2566749438 DslPrtcltFltrActvRgnrtnInhbtdDTP "Indicates the state of diesel particulate filter active regeneration inhibition due to the PTO being active.
00 not inhibited
01 inhibited
10 reserved for SAE assignment
11 not available
This SPN indicates the reason for the diesel particulate ...";
CM_ SG_ 2566749438 DslPrtcltFltrActvRgnrtnInhbtdDTS "Indicates the state of diesel particulate filter active regeneration inhibition due to the service brake being active.
00 not inhibited
01 inhibited
10 reserved for SAE assignment
11 not available
This SPN indicates the reason for the diesel ...";
CM_ SG_ 2566749438 DslPrtcltFltrActvRgnrtnInhbtdDTC "Indicates the state of diesel particulate filter active regeneration inhibition due to the clutch being disengaged.
00 not inhibited
01 inhibited
10 reserved for SAE assignment
11 not available
This SPN indicates the reason for the diesel ...";
CM_ SG_ 2566749438 DslPrtcltFltrActvRgnrtnInhbtdDTI "Indicates the state of diesel particulate filter active regeneration inhibition due to the Diesel Particulate Filter Regeneration Inhibit Switch.
00 not inhibited
01 inhibited
10 reserved for SAE assignment
11 not available
This SPN indicates ...";
CM_ SG_ 2566749438 DslPrtcltFltrActvRgnrtnInhbtdStt "Indicates the state of diesel particulate filter active regeneration inhibition.
00 not inhibited
01 inhibited
10 reserved for SAE assignment
11 not available
This SPN indicates the reason for the diesel particulate filter regeneration not ...";
CM_ SG_ 2566749438 DieselParticulateFilterStatus "Indicates the state of the diesel particulate filter regeneration need and urgency.  This is an aggregate of bank 1 and bank 2.  It is a system status and not individual bank status.
000 Regeneration not needed
001 Regeneration needed - lowest ...";
CM_ SG_ 2566749438 DslPrtcltFltrActvRgnrationStatus "Indicates the state of diesel particulate filter active regeneration.  This is an aggregate of bank 1 and bank 2.  It is a system status and not individual bank status.
00 not active
01 active
10 regeneration needed - automatically initiated ...";
CM_ SG_ 2566749438 DslPrtcltFltrPssvRgnrationStatus "Indicates the state of diesel particulate filter passive regeneration.  This is an aggregate of bank 1 and bank 2.  It is a system status and not individual bank status.


00 not active
01 active
10 reserved for SAE assignment
11 not available";
CM_ SG_ 2566749438 DieselParticulateFilterLampCmd "Command to control the diesel particulate filter lamp.
000 Off
001 On – solid
010 reserved for SAE assignment
011 reserved for SAE assignment
100 On – fast blink (1 HZ)
101 reserved for SAE assignment
110 reserved for SAE assignment
111 not ...";
CM_ BO_ 2566715646 "Additional diesel particulate filter soot parameters for diesel particulate filter 2.";
CM_ SG_ 2566715646 DslPrtculateFilter2SootSignalMin "Minimum output signal level of the current soot measurement from diesel particulate filter 2 soot sensor.  This is a statistical value, not the minimum sensing capability of the sensor.";
CM_ SG_ 2566715646 DslPrtculateFilter2SootSignalMax "Maximum output signal level of the current soot measurement from diesel particulate filter 2 soot sensor.  This is a statistical value, not the maximum sensing capability of the sensor.";
CM_ SG_ 2566715646 DslPrtcltFltr2StSgnlStndrdDvtion "Standard deviation of the soot measurement from diesel particulate filter 2 soot sensor.";
CM_ BO_ 2566724606 "Diesel particulate filter soot parameters for diesel particulate filter 2.";
CM_ SG_ 2566724606 DslPrtcltFltr2StSnsrECUIntrnlTmp "Internal temperature of the diesel particulate filter 2 soot sensor ECU.";
CM_ SG_ 2566724606 DslPrtcltFltr2StSnsrPrlminaryFMI "Used to identify the applicable J1939-73 FMI detected in the soot sensor signal by the manufacturer’s sensor control software in diesel particulate filter 2. When there is no failure FMI 31 is sent. In the case of multiple failures the most severe ...";
CM_ SG_ 2566724606 DslPrtcltFilter2MedianSootSignal "Median output signal level from diesel particulate filter 2 soot sensor.";
CM_ SG_ 2566724606 DslPrtclateFilter2MeanSootSignal "Mean output signal level from diesel particulate filter 2 soot sensor.";
CM_ SG_ 2566724606 DslParticulateFilter2SootDensity "Soot density in diesel particulate filter 2.";
CM_ SG_ 2566724606 DieselParticulateFilter2SootMass "Soot mass in diesel particulate filter 2.";
CM_ BO_ 2566715902 "Additional diesel particulate filter soot parameters for diesel particulate filter 1.";
CM_ SG_ 2566715902 DslPrtculateFilter1SootSignalMin "Minimum output signal level of the current soot measurement from diesel particulate filter 1 soot sensor.  This is a statistical value, not the minimum sensing capability of the sensor.";
CM_ SG_ 2566715902 DslPrtculateFilter1SootSignalMax "Maximum output signal level of the current soot measurement from diesel particulate filter 1 soot sensor.  This is a statistical value, not the maximum sensing capability of the sensor.";
CM_ SG_ 2566715902 DslPrtcltFltr1StSgnlStndrdDvtion "Standard deviation of the soot measurement from diesel particulate filter 1 soot sensor.";
CM_ BO_ 2566724862 "Diesel particulate filter soot parameters for diesel particulate filter 1.";
CM_ SG_ 2566724862 DslPrtcltFltr1StSnsrECUIntrnlTmp "Internal temperature of the diesel particulate filter 1 soot sensor ECU.";
CM_ SG_ 2566724862 DslPrtcltFltr1StSnsrPrlminaryFMI "Used to identify the applicable J1939-73 FMI detected in the soot sensor signal by the manufacturer’s sensor control software in diesel particulate filter 1. When there is no failure FMI 31 is sent. In the case of multiple failures the most severe ...";
CM_ SG_ 2566724862 DslPrtcltFilter1MedianSootSignal "Median output signal level from diesel particulate filter 1 soot sensor.";
CM_ SG_ 2566724862 DslPrtclateFilter1MeanSootSignal "Mean output signal level from diesel particulate filter 1 soot sensor.";
CM_ SG_ 2566724862 DslParticulateFilter1SootDensity "Soot density in diesel particulate filter 1.";
CM_ SG_ 2566724862 DieselParticulateFilter1SootMass "Soot mass in diesel particulate filter 1.";
CM_ BO_ 2566718718 "This message will be transmitted by the controller that is illuminating the lamps.

It is not required to be used with PGN 64774.";
CM_ SG_ 2566718718 VehicleBatteryChargingLampData "This parameter provides measured data from the Vehicle Battery Charging Lamp.

00 - Lamp deactivated (Off)
01 - Lamp activated (On)
10 - Error
11 - Not available";
CM_ SG_ 2566718718 VehicleHVACRecirculationLampData "This parameter provides measured data from the Vehicle HVAC Recirculation Lamp.

00 - Lamp deactivated (Off)
01 - Lamp activated (On)
10 - Error
11 - Not available";
CM_ SG_ 2566718718 VehicleAirPressLowLampData "This parameter provides measured data from the Vehicle Air Pressure Low Lamp.

00 - Lamp deactivated (Off)
01 - Lamp activated (On)
10 - Error
11 - Not available";
CM_ SG_ 2566718718 VehicleFuelLevelLowLampData "This parameter provides measured data from the Vehicle Fuel Level Low Lamp.

00 - Lamp deactivated (Off)
01 - Lamp activated (On)
10 - Error
11 - Not available";
CM_ SG_ 2566718718 VehicleBatteryVoltageLowLampData "This parameter provides measured data from the Vehicle Battery Voltage Low Lamp.

00 - Lamp deactivated (Off)
01 - Lamp activated (On)
10 - Error
11 - Not available";
CM_ BO_ 2566718974 "This message will be transmitted by the controller that is illuminating the lamps.

It is not required to be used with PGN 64775.";
CM_ SG_ 2566718974 EngCtrlMdule3ReadyForUseLampData "This parameter provides measured data from the Engine Control Module 3 Ready for Use Lamp.

00 - Lamp deactivated (Off)
01 - Lamp activated (On)
10 - Error
11 - Not Available";
CM_ SG_ 2566718974 EngCtrlMdule2ReadyForUseLampData "This parameter provides measured data from the Engine Control Module 2 Ready for Use Lamp.

00 - Lamp deactivated (Off)
01 - Lamp activated (On)
10 - Error
11 - Not Available";
CM_ SG_ 2566718974 EngCtrlMdule1ReadyForUseLampData "This parameter provides measured data from the Engine Control Module 1 Ready for Use Lamp.

00 - Lamp deactivated (Off)
01 - Lamp activated (On)
10 - Error
11 - Not Available";
CM_ SG_ 2566718974 EngWaitToStartLampData "This parameter provides measured data from the Engine Wait To Start Lamp.  See SPN 1081 for the command.

00 - Lamp deactived (off)
01 - Lamp actived (on)
10 - Error
11 - Not available";
CM_ SG_ 2566718974 EngFuelFilterRestrictedLampData "This parameter provides measured data from the Engine Fuel Filter Restricted Lamp.

00 - Lamp deactivated (Off)
01 - Lamp activated (On)
10 - Error
11 - Not available";
CM_ SG_ 2566718974 EngAirFilterRestrictionLampData "This parameter provides measured data from the Engine Air Filter Restriction Lamp.

00 - Lamp deactivated (Off)
01 - Lamp activated (On)
10 - Error
11 - Not available";
CM_ SG_ 2566718974 EngIdleManagementActiveLampData "This parameter provides measured data from the Engine Idle Management Active Lamp.

00 - Lamp deactivated (Off)
01 - Lamp activated (On)
10 - Error
11 - Not available";
CM_ SG_ 2566718974 EngCoolantLevelLowLampData "This parameter provides measured data from the Engine Coolant Level Low Lamp.

00 - Lamp deactivated (Off)
01 - Lamp activated (On)
10 - Error
11 - Not available";
CM_ SG_ 2566718974 EngCoolantTempHighLampData "This parameter provides measured data from the Engine Coolant Temperature High Lamp.

00 - Lamp deactivated (Off)
01 - Lamp activated (On)
10 - Error
11 - Not available";
CM_ SG_ 2566718974 EngOilPressLowLampData "This parameter provides measured data from the Engine Oil Pressure Low Lamp.

00 - Lamp deactivated (Off)
01 - Lamp activated (On)
10 - Error
11 - Not available";
CM_ SG_ 2566718974 CmprssnBrkEnblSwtchIndctrLmpData "This parameter provides measured data from the Compression Brake Enable Switch Indicator Lamp.

00 - Lamp deactivated (Off)
01 - Lamp activated (On)
10 - Error
11 - Not available";
CM_ SG_ 2566718974 EngBrakeActiveLampData "This parameter provides measured data from the Engine Brake Active Lamp.

00 - Lamp deactivated (Off)
01 - Lamp activated (On)
10 - Error
11 - Not available";
CM_ SG_ 2566718974 OBDMalfunctionIndicatorLampData "This parameter provides measured data from the OBD Malfunction Indicator Lamp.

00 - Lamp deactivated (Off)
01 - Lamp activated (On)
10 - Error
11 - Not available";
CM_ SG_ 2566718974 EngRedStopLampData "This parameter provides measured data from the Engine Red Stop Lamp.

00 - Lamp deactivated (Off)
01 - Lamp activated (On)
10 - Error
11 - Not available";
CM_ SG_ 2566718974 EngAmberWarningLampData "This parameter provides measured data from the Engine Amber Warning Lamp.

00 - Lamp deactivated (Off)
01 - Lamp activated (On)
10 - Error
11 - Not available";
CM_ SG_ 2566718974 EngProtectLampData "This parameter provides measured data from the Engine Protect Lamp.

00 - Lamp deactivated (Off)
01 - Lamp activated (On)
10 - Error
11 - Not available";
CM_ BO_ 2566719230 "Message that directly controls the driver indicator lamps.   See also PGN 64775 for additional lamps and PGN 64772 for the feedback information about these lamps.
Note: Since this message is direct lamp control, it is required that only one device ...";
CM_ SG_ 2566719230 VehicleBatteryChargingLampCmd "Command signal directly controlling the Vehicle Battery Charging Lamp.

00 - Lamp Off
01 - Lamp On
10 - Reserved
11 - Not available";
CM_ SG_ 2566719230 VehicleHVACRecirculationLampCmd "Command signal directly controlling the Vehicle HVAC Recirculation Lamp.

00 - Lamp Off
01 - Lamp On
10 - Reserved
11 - Not available";
CM_ SG_ 2566719230 VehicleAirPressLowLampCmd "Command signal directly controlling the Vehicle Air Pressure Low Lamp.

00 - Lamp Off
01 - Lamp On
10 - Reserved
11 - Not available";
CM_ SG_ 2566719230 VehicleFuelLevelLowLampCmd "Command signal directly controlling the Vehicle Fuel Level Low Lamp.

00 - Lamp Off
01 - Lamp On
10 - Reserved
11 - Not available";
CM_ SG_ 2566719230 VehicleBatteryVoltageLowLampCmd "Command signal directly controlling the Vehicle Battery Voltage Low Lamp.

00 - Lamp Off
01 - Lamp On
10 - Reserved
11 - Not available";
CM_ BO_ 2359492350 "Provides the DTCs and associated timers related to a regulated exhaust emission level exceedance due to an emission control system malfunction.";
CM_ SG_ 2359492350 SPN1 "This 19-bit number is used to identify the item for which diagnostics are being reported.";
CM_ SG_ 2359492350 FailureModeIdentifier1 "The FMI defines the type of failure detected in the subsystem identified by an SPN.";
CM_ SG_ 2359492350 DTCTimeUntilDerate "This timer provides the number of hours the malfunction has until the OBD required derate will occur";
CM_ SG_ 2359492350 DTCTotalPreviouslyActiveTime "This timer provides the number of hours the NOx malfunction has been confirmed and previously active";
CM_ SG_ 2359492350 DTCTotalActiveTime "This timer provides the total number of hours the DTC has been confirmed and active";
CM_ SG_ 2359492350 SPN1High "SPN #1 (Conversion Version 4)";
CM_ BO_ 2561212158 "This provides ASCII text information, for example to an display instrument.  Broadcast rate should be on event and 1-5 seconds due to variable character length.  This message is to convey information from an ecu to a display.  In its most basic ...";
CM_ SG_ 2561212158 TextDisplayIndex "Used for overwriting consecutive bytes of a displayed string when byte 1 \"Text Display Instructions\" state is set for \"overwrite substring\" mode.  When used, this byte declares where in the text string that the new text will start overwriting, this ...";
CM_ SG_ 2561212158 TextDisplayInstructions "This parameter describes the status for the display how to show the information.
0000 Clear display - The displayed information should be deleted or not displayed any more.
0001 Hold display - The presently displayed information should be retained
 ...";
BA_DEF_ SG_  "SigType" ENUM  "Default","Range","RangeSigned","ASCII","Discrete","Control","ReferencePGN","DTC","StringDelimiter","StringLength","StringLengthControl","MessageCounter","MessageChecksum";
BA_DEF_ SG_  "GenSigStartValue" INT 0 10000;
BA_DEF_ SG_  "GenSigSendType" ENUM  "Cyclic","OnWrite","OnWriteWithRepetition","OnChange","OnChangeWithRepetition","IfActive","IfActiveWithRepetition","NoSigSendType";
BA_DEF_ SG_  "GenSigILSupport" ENUM  "No","Yes";
BA_DEF_ SG_  "GenSigEVName" STRING ;
BA_DEF_ SG_  "SPN" INT 0 524287;
BA_DEF_ BO_  "GenMsgStartDelayTime" INT 0 100000;
BA_DEF_ BO_  "GenMsgILSupport" ENUM  "No","Yes";
BA_DEF_ BO_  "GenMsgRequestable" INT 0 1;
BA_DEF_ BO_  "GenMsgSendType" ENUM  "cyclic","NotUsed","NotUsed","NotUsed","NotUsed","NotUsed","NotUsed","IfActive","noMsgSendType";
BA_DEF_ BO_  "VFrameFormat" ENUM  "StandardCAN","ExtendedCAN","reserved","J1939PG";
BA_DEF_ BO_  "GenMsgCycleTime" INT 0 3600000;
BA_DEF_ SG_  "SystemSignalLongSymbol" STRING ;
BA_DEF_DEF_  "SigType" "Default";
BA_DEF_DEF_  "GenSigStartValue" 0;
BA_DEF_DEF_  "GenSigSendType" "NoSigSendType";
BA_DEF_DEF_  "GenSigILSupport" "Yes";
BA_DEF_DEF_  "GenSigEVName" "Env@Nodename_@Signame";
BA_DEF_DEF_  "SPN" 0;
BA_DEF_DEF_  "GenMsgStartDelayTime" 0;
BA_DEF_DEF_  "GenMsgILSupport" "Yes";
BA_DEF_DEF_  "GenMsgRequestable" 1;
BA_DEF_DEF_  "GenMsgSendType" "noMsgSendType";
BA_DEF_DEF_  "VFrameFormat" "J1939PG";
BA_DEF_DEF_  "GenMsgCycleTime" 0;
BA_DEF_DEF_  "SystemSignalLongSymbol" "";
BA_ "GenMsgSendType" BO_ 2566711550 0;
BA_ "GenMsgCycleTime" BO_ 2566711550 500;
BA_ "GenMsgSendType" BO_ 2566719998 0;
BA_ "GenMsgCycleTime" BO_ 2566719998 1000;
BA_ "GenMsgSendType" BO_ 2566713854 0;
BA_ "GenMsgCycleTime" BO_ 2566713854 100;
BA_ "GenMsgSendType" BO_ 2566714366 0;
BA_ "GenMsgCycleTime" BO_ 2566714366 100;
BA_ "GenMsgSendType" BO_ 2566714110 0;
BA_ "GenMsgCycleTime" BO_ 2566714110 100;
BA_ "GenMsgSendType" BO_ 2566717438 0;
BA_ "GenMsgCycleTime" BO_ 2566717438 1000;
BA_ "GenMsgSendType" BO_ 2633828606 0;
BA_ "GenMsgCycleTime" BO_ 2633828606 30000;
BA_ "GenMsgSendType" BO_ 2365400574 0;
BA_ "GenMsgCycleTime" BO_ 2365400574 100;
BA_ "GenMsgSendType" BO_ 2365401086 0;
BA_ "GenMsgCycleTime" BO_ 2365401086 100;
BA_ "GenMsgSendType" BO_ 2365401598 0;
BA_ "GenMsgCycleTime" BO_ 2365401598 100;
BA_ "GenMsgSendType" BO_ 2365402110 0;
BA_ "GenMsgCycleTime" BO_ 2365402110 100;
BA_ "GenMsgSendType" BO_ 2365402622 0;
BA_ "GenMsgCycleTime" BO_ 2365402622 100;
BA_ "GenMsgSendType" BO_ 2365403134 0;
BA_ "GenMsgCycleTime" BO_ 2365403134 100;
BA_ "GenMsgSendType" BO_ 2365400062 0;
BA_ "GenMsgCycleTime" BO_ 2365400062 100;
BA_ "GenMsgSendType" BO_ 2566713598 0;
BA_ "GenMsgCycleTime" BO_ 2566713598 500;
BA_ "GenMsgSendType" BO_ 2499604478 0;
BA_ "GenMsgCycleTime" BO_ 2499604478 500;
BA_ "GenMsgSendType" BO_ 2499608830 0;
BA_ "GenMsgCycleTime" BO_ 2499608830 500;
BA_ "GenMsgSendType" BO_ 2432499198 0;
BA_ "GenMsgCycleTime" BO_ 2432499198 100;
BA_ "GenMsgSendType" BO_ 2566711294 0;
BA_ "GenMsgCycleTime" BO_ 2566711294 5000;
BA_ "GenMsgSendType" BO_ 2566749438 0;
BA_ "GenMsgCycleTime" BO_ 2566749438 1000;
BA_ "GenMsgSendType" BO_ 2566715646 0;
BA_ "GenMsgCycleTime" BO_ 2566715646 1000;
BA_ "GenMsgSendType" BO_ 2566724606 0;
BA_ "GenMsgCycleTime" BO_ 2566724606 1000;
BA_ "GenMsgSendType" BO_ 2566715902 0;
BA_ "GenMsgCycleTime" BO_ 2566715902 1000;
BA_ "GenMsgSendType" BO_ 2566724862 0;
BA_ "GenMsgCycleTime" BO_ 2566724862 1000;
BA_ "GenMsgSendType" BO_ 2566718718 0;
BA_ "GenMsgCycleTime" BO_ 2566718718 1000;
BA_ "GenMsgSendType" BO_ 2566718974 0;
BA_ "GenMsgCycleTime" BO_ 2566718974 1000;
BA_ "GenMsgSendType" BO_ 2566719230 0;
BA_ "GenMsgCycleTime" BO_ 2566719230 1000;
BA_ "SigType" SG_ 2566711550 IntkVlvActtnSystmOlPrss2SlndCtrl 5;
BA_ "SPN" SG_ 2566711550 IntkVlvActtnSystmOlPrss2SlndCtrl 5500;
BA_ "SigType" SG_ 2566711550 IntkVlvActtnSystmOlPrss1SlndCtrl 5;
BA_ "SPN" SG_ 2566711550 IntkVlvActtnSystmOlPrss1SlndCtrl 5499;
BA_ "SigType" SG_ 2633832958 SpecialIgnitorLoop90Resistance 1;
BA_ "SPN" SG_ 2633832958 SpecialIgnitorLoop90Resistance 4917;
BA_ "SigType" SG_ 2633832958 SpecialIgnitorLoop89Resistance 1;
BA_ "SPN" SG_ 2633832958 SpecialIgnitorLoop89Resistance 4916;
BA_ "SigType" SG_ 2633832958 SpecialIgnitorLoop88Resistance 1;
BA_ "SPN" SG_ 2633832958 SpecialIgnitorLoop88Resistance 4915;
BA_ "SigType" SG_ 2633832958 SpecialIgnitorLoop87Resistance 1;
BA_ "SPN" SG_ 2633832958 SpecialIgnitorLoop87Resistance 4914;
BA_ "SigType" SG_ 2633832958 SpecialIgnitorLoop86Resistance 1;
BA_ "SPN" SG_ 2633832958 SpecialIgnitorLoop86Resistance 4913;
BA_ "SigType" SG_ 2633832958 SpecialIgnitorLoop85Resistance 1;
BA_ "SPN" SG_ 2633832958 SpecialIgnitorLoop85Resistance 4912;
BA_ "SigType" SG_ 2633832958 SpecialIgnitorLoop84Resistance 1;
BA_ "SPN" SG_ 2633832958 SpecialIgnitorLoop84Resistance 4911;
BA_ "SigType" SG_ 2633832958 SpecialIgnitorLoop83Resistance 1;
BA_ "SPN" SG_ 2633832958 SpecialIgnitorLoop83Resistance 4910;
BA_ "SigType" SG_ 2633832958 SpecialIgnitorLoop82Resistance 1;
BA_ "SPN" SG_ 2633832958 SpecialIgnitorLoop82Resistance 4909;
BA_ "SigType" SG_ 2633832958 SpecialIgnitorLoop81Resistance 1;
BA_ "SPN" SG_ 2633832958 SpecialIgnitorLoop81Resistance 4908;
BA_ "SigType" SG_ 2633832958 SpecialIgnitorLoop80Resistance 1;
BA_ "SPN" SG_ 2633832958 SpecialIgnitorLoop80Resistance 4907;
BA_ "SigType" SG_ 2633832958 SpecialIgnitorLoop79Resistance 1;
BA_ "SPN" SG_ 2633832958 SpecialIgnitorLoop79Resistance 4906;
BA_ "SigType" SG_ 2633832958 SpecialIgnitorLoop78Resistance 1;
BA_ "SPN" SG_ 2633832958 SpecialIgnitorLoop78Resistance 4905;
BA_ "SigType" SG_ 2633832958 SpecialIgnitorLoop77Resistance 1;
BA_ "SPN" SG_ 2633832958 SpecialIgnitorLoop77Resistance 4904;
BA_ "SigType" SG_ 2633832958 SpecialIgnitorLoop76Resistance 1;
BA_ "SPN" SG_ 2633832958 SpecialIgnitorLoop76Resistance 4903;
BA_ "SigType" SG_ 2633832958 SpecialIgnitorLoop75Resistance 1;
BA_ "SPN" SG_ 2633832958 SpecialIgnitorLoop75Resistance 4902;
BA_ "SigType" SG_ 2633832958 SpecialIgnitorLoop74Resistance 1;
BA_ "SPN" SG_ 2633832958 SpecialIgnitorLoop74Resistance 4901;
BA_ "SigType" SG_ 2633832958 SpecialIgnitorLoop73Resistance 1;
BA_ "SPN" SG_ 2633832958 SpecialIgnitorLoop73Resistance 4900;
BA_ "SigType" SG_ 2633832958 SpecialIgnitorLoop72Resistance 1;
BA_ "SPN" SG_ 2633832958 SpecialIgnitorLoop72Resistance 4899;
BA_ "SigType" SG_ 2633832958 SpecialIgnitorLoop71Resistance 1;
BA_ "SPN" SG_ 2633832958 SpecialIgnitorLoop71Resistance 4898;
BA_ "SigType" SG_ 2633832958 SpecialIgnitorLoop70Resistance 1;
BA_ "SPN" SG_ 2633832958 SpecialIgnitorLoop70Resistance 4897;
BA_ "SigType" SG_ 2633832958 SpecialIgnitorLoop69Resistance 1;
BA_ "SPN" SG_ 2633832958 SpecialIgnitorLoop69Resistance 4896;
BA_ "SigType" SG_ 2633832958 SpecialIgnitorLoop68Resistance 1;
BA_ "SPN" SG_ 2633832958 SpecialIgnitorLoop68Resistance 4895;
BA_ "SigType" SG_ 2633832958 SpecialIgnitorLoop67Resistance 1;
BA_ "SPN" SG_ 2633832958 SpecialIgnitorLoop67Resistance 4894;
BA_ "SigType" SG_ 2633832958 SpecialIgnitorLoop66Resistance 1;
BA_ "SPN" SG_ 2633832958 SpecialIgnitorLoop66Resistance 4893;
BA_ "SigType" SG_ 2633832958 SpecialIgnitorLoop65Resistance 1;
BA_ "SPN" SG_ 2633832958 SpecialIgnitorLoop65Resistance 4892;
BA_ "SigType" SG_ 2633832958 SpecialIgnitorLoop64Resistance 1;
BA_ "SPN" SG_ 2633832958 SpecialIgnitorLoop64Resistance 4891;
BA_ "SigType" SG_ 2633832958 SpecialIgnitorLoop63Resistance 1;
BA_ "SPN" SG_ 2633832958 SpecialIgnitorLoop63Resistance 4890;
BA_ "SigType" SG_ 2633832958 SpecialIgnitorLoop62Resistance 1;
BA_ "SPN" SG_ 2633832958 SpecialIgnitorLoop62Resistance 4889;
BA_ "SigType" SG_ 2633832958 SpecialIgnitorLoop61Resistance 1;
BA_ "SPN" SG_ 2633832958 SpecialIgnitorLoop61Resistance 4888;
BA_ "SigType" SG_ 2633832958 SpecialIgnitorLoop60Resistance 1;
BA_ "SPN" SG_ 2633832958 SpecialIgnitorLoop60Resistance 4887;
BA_ "SigType" SG_ 2633832958 SpecialIgnitorLoop59Resistance 1;
BA_ "SPN" SG_ 2633832958 SpecialIgnitorLoop59Resistance 4886;
BA_ "SigType" SG_ 2633832958 SpecialIgnitorLoop58Resistance 1;
BA_ "SPN" SG_ 2633832958 SpecialIgnitorLoop58Resistance 4885;
BA_ "SigType" SG_ 2633832958 SpecialIgnitorLoop57Resistance 1;
BA_ "SPN" SG_ 2633832958 SpecialIgnitorLoop57Resistance 4884;
BA_ "SigType" SG_ 2633832958 SpecialIgnitorLoop56Resistance 1;
BA_ "SPN" SG_ 2633832958 SpecialIgnitorLoop56Resistance 4883;
BA_ "SigType" SG_ 2633832958 SpecialIgnitorLoop55Resistance 1;
BA_ "SPN" SG_ 2633832958 SpecialIgnitorLoop55Resistance 4882;
BA_ "SigType" SG_ 2633832958 SpecialIgnitorLoop54Resistance 1;
BA_ "SPN" SG_ 2633832958 SpecialIgnitorLoop54Resistance 4881;
BA_ "SigType" SG_ 2633832958 SpecialIgnitorLoop53Resistance 1;
BA_ "SPN" SG_ 2633832958 SpecialIgnitorLoop53Resistance 4880;
BA_ "SigType" SG_ 2633832958 SpecialIgnitorLoop52Resistance 1;
BA_ "SPN" SG_ 2633832958 SpecialIgnitorLoop52Resistance 4879;
BA_ "SigType" SG_ 2633832958 SpecialIgnitorLoop51Resistance 1;
BA_ "SPN" SG_ 2633832958 SpecialIgnitorLoop51Resistance 4878;
BA_ "SigType" SG_ 2633832958 SpecialIgnitorLoop50Resistance 1;
BA_ "SPN" SG_ 2633832958 SpecialIgnitorLoop50Resistance 4877;
BA_ "SigType" SG_ 2633832958 SpecialIgnitorLoop49Resistance 1;
BA_ "SPN" SG_ 2633832958 SpecialIgnitorLoop49Resistance 4876;
BA_ "SigType" SG_ 2633832958 SpecialIgnitorLoop48Resistance 1;
BA_ "SPN" SG_ 2633832958 SpecialIgnitorLoop48Resistance 4875;
BA_ "SigType" SG_ 2633832958 SpecialIgnitorLoop47Resistance 1;
BA_ "SPN" SG_ 2633832958 SpecialIgnitorLoop47Resistance 4874;
BA_ "SigType" SG_ 2633832958 SpecialIgnitorLoop46Resistance 1;
BA_ "SPN" SG_ 2633832958 SpecialIgnitorLoop46Resistance 4873;
BA_ "SigType" SG_ 2633832958 SpecialIgnitorLoop45Resistance 1;
BA_ "SPN" SG_ 2633832958 SpecialIgnitorLoop45Resistance 4872;
BA_ "SigType" SG_ 2633832958 SpecialIgnitorLoop44Resistance 1;
BA_ "SPN" SG_ 2633832958 SpecialIgnitorLoop44Resistance 4871;
BA_ "SigType" SG_ 2633832958 SpecialIgnitorLoop43Resistance 1;
BA_ "SPN" SG_ 2633832958 SpecialIgnitorLoop43Resistance 4870;
BA_ "SigType" SG_ 2633832958 SpecialIgnitorLoop42Resistance 1;
BA_ "SPN" SG_ 2633832958 SpecialIgnitorLoop42Resistance 4869;
BA_ "SigType" SG_ 2633832958 SpecialIgnitorLoop41Resistance 1;
BA_ "SPN" SG_ 2633832958 SpecialIgnitorLoop41Resistance 4868;
BA_ "SigType" SG_ 2633832958 SpecialIgnitorLoop40Resistance 1;
BA_ "SPN" SG_ 2633832958 SpecialIgnitorLoop40Resistance 4867;
BA_ "SigType" SG_ 2633832958 SpecialIgnitorLoop39Resistance 1;
BA_ "SPN" SG_ 2633832958 SpecialIgnitorLoop39Resistance 4866;
BA_ "SigType" SG_ 2633832958 SpecialIgnitorLoop38Resistance 1;
BA_ "SPN" SG_ 2633832958 SpecialIgnitorLoop38Resistance 4865;
BA_ "SigType" SG_ 2633832958 SpecialIgnitorLoop37Resistance 1;
BA_ "SPN" SG_ 2633832958 SpecialIgnitorLoop37Resistance 4864;
BA_ "SigType" SG_ 2633832958 SpecialIgnitorLoop36Resistance 1;
BA_ "SPN" SG_ 2633832958 SpecialIgnitorLoop36Resistance 4863;
BA_ "SigType" SG_ 2633832958 SpecialIgnitorLoop35Resistance 1;
BA_ "SPN" SG_ 2633832958 SpecialIgnitorLoop35Resistance 4862;
BA_ "SigType" SG_ 2633832958 SpecialIgnitorLoop34Resistance 1;
BA_ "SPN" SG_ 2633832958 SpecialIgnitorLoop34Resistance 4861;
BA_ "SigType" SG_ 2633832958 SpecialIgnitorLoop33Resistance 1;
BA_ "SPN" SG_ 2633832958 SpecialIgnitorLoop33Resistance 4860;
BA_ "SigType" SG_ 2633832958 SpecialIgnitorLoop32Resistance 1;
BA_ "SPN" SG_ 2633832958 SpecialIgnitorLoop32Resistance 4859;
BA_ "SigType" SG_ 2633832958 SpecialIgnitorLoop31Resistance 1;
BA_ "SPN" SG_ 2633832958 SpecialIgnitorLoop31Resistance 4858;
BA_ "SigType" SG_ 2633832958 SpecialIgnitorLoop30Resistance 1;
BA_ "SPN" SG_ 2633832958 SpecialIgnitorLoop30Resistance 4857;
BA_ "SigType" SG_ 2633832958 SpecialIgnitorLoop29Resistance 1;
BA_ "SPN" SG_ 2633832958 SpecialIgnitorLoop29Resistance 4856;
BA_ "SigType" SG_ 2633832958 SpecialIgnitorLoop28Resistance 1;
BA_ "SPN" SG_ 2633832958 SpecialIgnitorLoop28Resistance 4855;
BA_ "SigType" SG_ 2633832958 SpecialIgnitorLoop27Resistance 1;
BA_ "SPN" SG_ 2633832958 SpecialIgnitorLoop27Resistance 4854;
BA_ "SigType" SG_ 2633832958 SpecialIgnitorLoop26Resistance 1;
BA_ "SPN" SG_ 2633832958 SpecialIgnitorLoop26Resistance 4853;
BA_ "SigType" SG_ 2633832958 SpecialIgnitorLoop25Resistance 1;
BA_ "SPN" SG_ 2633832958 SpecialIgnitorLoop25Resistance 4852;
BA_ "SigType" SG_ 2633832958 SpecialIgnitorLoop24Resistance 1;
BA_ "SPN" SG_ 2633832958 SpecialIgnitorLoop24Resistance 4851;
BA_ "SigType" SG_ 2633832958 SpecialIgnitorLoop23Resistance 1;
BA_ "SPN" SG_ 2633832958 SpecialIgnitorLoop23Resistance 4850;
BA_ "SigType" SG_ 2633832958 SpecialIgnitorLoop22Resistance 1;
BA_ "SPN" SG_ 2633832958 SpecialIgnitorLoop22Resistance 4849;
BA_ "SigType" SG_ 2633832958 SpecialIgnitorLoop21Resistance 1;
BA_ "SPN" SG_ 2633832958 SpecialIgnitorLoop21Resistance 4848;
BA_ "SigType" SG_ 2633832958 SpecialIgnitorLoop20Resistance 1;
BA_ "SPN" SG_ 2633832958 SpecialIgnitorLoop20Resistance 4847;
BA_ "SigType" SG_ 2633832958 SpecialIgnitorLoop19Resistance 1;
BA_ "SPN" SG_ 2633832958 SpecialIgnitorLoop19Resistance 4846;
BA_ "SigType" SG_ 2633832958 SpecialIgnitorLoop18Resistance 1;
BA_ "SPN" SG_ 2633832958 SpecialIgnitorLoop18Resistance 4845;
BA_ "SigType" SG_ 2633832958 SpecialIgnitorLoop17Resistance 1;
BA_ "SPN" SG_ 2633832958 SpecialIgnitorLoop17Resistance 4844;
BA_ "SigType" SG_ 2633832958 SpecialIgnitorLoop16Resistance 1;
BA_ "SPN" SG_ 2633832958 SpecialIgnitorLoop16Resistance 4843;
BA_ "SigType" SG_ 2633832958 SpecialIgnitorLoop15Resistance 1;
BA_ "SPN" SG_ 2633832958 SpecialIgnitorLoop15Resistance 4842;
BA_ "SigType" SG_ 2633832958 SpecialIgnitorLoop14Resistance 1;
BA_ "SPN" SG_ 2633832958 SpecialIgnitorLoop14Resistance 4841;
BA_ "SigType" SG_ 2633832958 SpecialIgnitorLoop13Resistance 1;
BA_ "SPN" SG_ 2633832958 SpecialIgnitorLoop13Resistance 4840;
BA_ "SigType" SG_ 2633832958 SpecialIgnitorLoop12Resistance 1;
BA_ "SPN" SG_ 2633832958 SpecialIgnitorLoop12Resistance 4839;
BA_ "SigType" SG_ 2633832958 SpecialIgnitorLoop11Resistance 1;
BA_ "SPN" SG_ 2633832958 SpecialIgnitorLoop11Resistance 4838;
BA_ "SigType" SG_ 2633832958 SpecialIgnitorLoop10Resistance 1;
BA_ "SPN" SG_ 2633832958 SpecialIgnitorLoop10Resistance 4837;
BA_ "SigType" SG_ 2633832958 SpecialIgnitorLoop9Resistance 1;
BA_ "SPN" SG_ 2633832958 SpecialIgnitorLoop9Resistance 4836;
BA_ "SigType" SG_ 2633832958 SpecialIgnitorLoop8Resistance 1;
BA_ "SPN" SG_ 2633832958 SpecialIgnitorLoop8Resistance 4835;
BA_ "SigType" SG_ 2633832958 SpecialIgnitorLoop7Resistance 1;
BA_ "SPN" SG_ 2633832958 SpecialIgnitorLoop7Resistance 4834;
BA_ "SigType" SG_ 2633832958 SpecialIgnitorLoop6Resistance 1;
BA_ "SPN" SG_ 2633832958 SpecialIgnitorLoop6Resistance 4833;
BA_ "SigType" SG_ 2633832958 SpecialIgnitorLoop5Resistance 1;
BA_ "SPN" SG_ 2633832958 SpecialIgnitorLoop5Resistance 4832;
BA_ "SigType" SG_ 2633832958 SpecialIgnitorLoop4Resistance 1;
BA_ "SPN" SG_ 2633832958 SpecialIgnitorLoop4Resistance 4831;
BA_ "SigType" SG_ 2633832958 SpecialIgnitorLoop3Resistance 1;
BA_ "SPN" SG_ 2633832958 SpecialIgnitorLoop3Resistance 4830;
BA_ "SigType" SG_ 2633832958 SpecialIgnitorLoop2Resistance 1;
BA_ "SPN" SG_ 2633832958 SpecialIgnitorLoop2Resistance 4829;
BA_ "SigType" SG_ 2633832958 SpecialIgnitorLoop1Resistance 1;
BA_ "SPN" SG_ 2633832958 SpecialIgnitorLoop1Resistance 4828;
BA_ "SigType" SG_ 2633832958 SdBagIgnitorLoop2RightResistance 1;
BA_ "SPN" SG_ 2633832958 SdBagIgnitorLoop2RightResistance 4827;
BA_ "SigType" SG_ 2633832958 SdBagIgnitorLoop1RightResistance 1;
BA_ "SPN" SG_ 2633832958 SdBagIgnitorLoop1RightResistance 4826;
BA_ "SigType" SG_ 2633832958 SdeBagIgnitorLoop2LeftResistance 1;
BA_ "SPN" SG_ 2633832958 SdeBagIgnitorLoop2LeftResistance 4825;
BA_ "SigType" SG_ 2633832958 SdeBagIgnitorLoop1LeftResistance 1;
BA_ "SPN" SG_ 2633832958 SdeBagIgnitorLoop1LeftResistance 4824;
BA_ "SigType" SG_ 2633832958 PssngrBltTnsnrIgntrLopResistance 1;
BA_ "SPN" SG_ 2633832958 PssngrBltTnsnrIgntrLopResistance 4823;
BA_ "SigType" SG_ 2633832958 DrvrBltTnsnrIgntorLoopResistance 1;
BA_ "SPN" SG_ 2633832958 DrvrBltTnsnrIgntorLoopResistance 4822;
BA_ "SigType" SG_ 2633832958 PssngrArbgIgntrLp2ndStgRsistance 1;
BA_ "SPN" SG_ 2633832958 PssngrArbgIgntrLp2ndStgRsistance 4821;
BA_ "SigType" SG_ 2633832958 DrvrArbgIgntrLp2ndStgeResistance 1;
BA_ "SPN" SG_ 2633832958 DrvrArbgIgntrLp2ndStgeResistance 4820;
BA_ "SigType" SG_ 2633832958 PssngrArbgIgntrLp1stStgRsistance 1;
BA_ "SPN" SG_ 2633832958 PssngrArbgIgntrLp1stStgRsistance 4819;
BA_ "SigType" SG_ 2633832958 DrvrArbgIgntrLp1stStgeResistance 1;
BA_ "SPN" SG_ 2633832958 DrvrArbgIgntrLp1stStgeResistance 4818;
BA_ "SigType" SG_ 2566719998 HighResolutionEngTotalFuelUsed 1;
BA_ "SPN" SG_ 2566719998 HighResolutionEngTotalFuelUsed 5054;
BA_ "SigType" SG_ 2566719998 HighResolutionEngTripFuel 1;
BA_ "SPN" SG_ 2566719998 HighResolutionEngTripFuel 5053;
BA_ "SigType" SG_ 2565877502 EngTrbCmprssrBlowoffActuator1Cmd 1;
BA_ "SPN" SG_ 2565877502 EngTrbCmprssrBlowoffActuator1Cmd 6201;
BA_ "SigType" SG_ 2565877502 EngExhstBckPressRegulatorCtrlCmd 1;
BA_ "SPN" SG_ 2565877502 EngExhstBckPressRegulatorCtrlCmd 649;
BA_ "SigType" SG_ 2565877502 EngTurboWastegateActuator2Cmd 1;
BA_ "SPN" SG_ 2565877502 EngTurboWastegateActuator2Cmd 5387;
BA_ "SigType" SG_ 2565877502 EngTurboWastegateActuator1Cmd 1;
BA_ "SPN" SG_ 2565877502 EngTurboWastegateActuator1Cmd 5386;
BA_ "SigType" SG_ 2566713854 EngExhaustBackPressActuator1Temp 1;
BA_ "SPN" SG_ 2566713854 EngExhaustBackPressActuator1Temp 5790;
BA_ "SigType" SG_ 2566713854 EngExhstBckPrssActtor1DesiredPos 1;
BA_ "SPN" SG_ 2566713854 EngExhstBckPrssActtor1DesiredPos 5789;
BA_ "SigType" SG_ 2566713854 EngTurboWastegateActuator1Temp 1;
BA_ "SPN" SG_ 2566713854 EngTurboWastegateActuator1Temp 5788;
BA_ "SPN" SG_ 2566713854 EngExhstBckPrssRgltrCtrlOprtnStt 5628;
BA_ "SPN" SG_ 2566713854 EngExhstBckPrssRglatorTempStatus 5627;
BA_ "SPN" SG_ 2566713854 EngExhstBckPrssRgltrPrlminaryFMI 5626;
BA_ "SigType" SG_ 2566713854 EngExhaustBackPressRegulatorPos 1;
BA_ "SPN" SG_ 2566713854 EngExhaustBackPressRegulatorPos 5625;
BA_ "SPN" SG_ 2566713854 EngTrbWstgtActtr2OperationStatus 5452;
BA_ "SPN" SG_ 2566713854 EngTrbWstgtActtr1OperationStatus 5451;
BA_ "SPN" SG_ 2566713854 EngTrbWstgateActuator2TempStatus 5385;
BA_ "SPN" SG_ 2566713854 EngTrbWstgtActtor2PreliminaryFMI 5384;
BA_ "SigType" SG_ 2566714366 EngTrbCmprssrBypassActuator2Temp 1;
BA_ "SPN" SG_ 2566714366 EngTrbCmprssrBypassActuator2Temp 5792;
BA_ "SigType" SG_ 2566714366 EngTrbCmprssrBypassActuator1Temp 1;
BA_ "SPN" SG_ 2566714366 EngTrbCmprssrBypassActuator1Temp 5791;
BA_ "SPN" SG_ 2566714366 EngTrbCmprssrBypssActtr2OprtnStt 5450;
BA_ "SPN" SG_ 2566714366 EngTrbCmprssrBypssActtr1OprtnStt 5449;
BA_ "SPN" SG_ 2566714366 EngTrbCmprssrBypssActtr2TmpSttus 5391;
BA_ "SPN" SG_ 2566714366 EngTrbCmprssrBypssActtr2PrlmnryF 5390;
BA_ "SigType" SG_ 2566714366 EngDsrdTrbCmprssrBypssActtor2Pos 1;
BA_ "SPN" SG_ 2566714366 EngDsrdTrbCmprssrBypssActtor2Pos 5389;
BA_ "SigType" SG_ 2566714366 EngTrbCmprssorBypassActuator2Pos 1;
BA_ "SPN" SG_ 2566714366 EngTrbCmprssorBypassActuator2Pos 5388;
BA_ "SPN" SG_ 2566714110 EngFuelValve2OperationStatus 5448;
BA_ "SPN" SG_ 2566714110 EngFuelValve1OperationStatus 5447;
BA_ "SPN" SG_ 2566714110 EngThrottleValve2OperationStatus 5446;
BA_ "SPN" SG_ 2566714110 EngThrottleValve1OperationStatus 5445;
BA_ "SPN" SG_ 2566714110 EngFuelValve2TempStatus 5383;
BA_ "SPN" SG_ 2566714110 EngFuelValve2PreliminaryFMI 5382;
BA_ "SPN" SG_ 2566714110 EngFuelValve1TempStatus 5381;
BA_ "SPN" SG_ 2566714110 EngFuelValve1PreliminaryFMI 5380;
BA_ "SPN" SG_ 2566714110 EngThrottleValve2TempStatus 5379;
BA_ "SPN" SG_ 2566714110 EngThrottleValve2PreliminaryFMI 5378;
BA_ "SigType" SG_ 2566714110 EngDesiredThrottleValve2Pos 1;
BA_ "SPN" SG_ 2566714110 EngDesiredThrottleValve2Pos 5377;
BA_ "SPN" SG_ 2566714110 EngThrottleValve1TempStatus 5376;
BA_ "SPN" SG_ 2566714110 EngThrottleValve1PreliminaryFMI 5375;
BA_ "SigType" SG_ 2566714110 EngDesiredThrottleValve1Pos 1;
BA_ "SPN" SG_ 2566714110 EngDesiredThrottleValve1Pos 5374;
BA_ "SigType" SG_ 2566717438 EngExhstGsRcrcltn2MxerIntakeTemp 1;
BA_ "SPN" SG_ 2566717438 EngExhstGsRcrcltn2MxerIntakeTemp 5256;
BA_ "SigType" SG_ 2566717438 EngExhaustGasRecirculation2Temp 1;
BA_ "SPN" SG_ 2566717438 EngExhaustGasRecirculation2Temp 5255;
BA_ "SigType" SG_ 2633828606 EngOilTemp3 1;
BA_ "SPN" SG_ 2633828606 EngOilTemp3 5925;
BA_ "SigType" SG_ 2633828606 EngOilRelativeDielectricity 1;
BA_ "SPN" SG_ 2633828606 EngOilRelativeDielectricity 5468;
BA_ "SigType" SG_ 2633828606 EngOilDensity 1;
BA_ "SPN" SG_ 2633828606 EngOilDensity 5056;
BA_ "SigType" SG_ 2633828606 EngOilViscosity 1;
BA_ "SPN" SG_ 2633828606 EngOilViscosity 5055;
BA_ "SigType" SG_ 2499607550 EngExhstMnfldBnk2FlwBlncVlvActtr 1;
BA_ "SPN" SG_ 2499607550 EngExhstMnfldBnk2FlwBlncVlvActtr 5279;
BA_ "SigType" SG_ 2499607550 EngExhstMnfldBnk1FlwBlncVlvActtr 1;
BA_ "SPN" SG_ 2499607550 EngExhstMnfldBnk1FlwBlncVlvActtr 5277;
BA_ "SigType" SG_ 2633825534 EngExhstMnfldBnk2FlwBlncVlvActtr 1;
BA_ "SPN" SG_ 2633825534 EngExhstMnfldBnk2FlwBlncVlvActtr 5278;
BA_ "SigType" SG_ 2633825534 EngExhstMnfldBnk1FlwBlncVlvActtr 1;
BA_ "SPN" SG_ 2633825534 EngExhstMnfldBnk1FlwBlncVlvActtr 5276;
BA_ "SigType" SG_ 2365400574 Jystick9GripXAxisDetentPosStatus 4;
BA_ "SPN" SG_ 2365400574 Jystick9GripXAxisDetentPosStatus 4712;
BA_ "SigType" SG_ 2365400574 Jystick9GripYAxisDetentPosStatus 4;
BA_ "SPN" SG_ 2365400574 Jystick9GripYAxisDetentPosStatus 4711;
BA_ "SigType" SG_ 2365400574 Jystick9ThetaAxisDetentPosStatus 4;
BA_ "SPN" SG_ 2365400574 Jystick9ThetaAxisDetentPosStatus 4710;
BA_ "SPN" SG_ 2365400574 Joystick9ThetaAxisPos 4709;
BA_ "SigType" SG_ 2365400574 Jystck9ThtAxsClckwsPstvPosStatus 4;
BA_ "SPN" SG_ 2365400574 Jystck9ThtAxsClckwsPstvPosStatus 4708;
BA_ "SigType" SG_ 2365400574 Jystck9ThtAxsCntrClckwsNgtvPsStt 4;
BA_ "SPN" SG_ 2365400574 Jystck9ThtAxsCntrClckwsNgtvPsStt 4707;
BA_ "SigType" SG_ 2365400574 Jystck9ThetaAxisNeutralPosStatus 4;
BA_ "SPN" SG_ 2365400574 Jystck9ThetaAxisNeutralPosStatus 4706;
BA_ "SPN" SG_ 2365400574 Joystick9GripYAxisPos 4705;
BA_ "SigType" SG_ 2365400574 Jystck9GrpYAxsLvrFrwrdPstvPsStts 4;
BA_ "SPN" SG_ 2365400574 Jystck9GrpYAxsLvrFrwrdPstvPsStts 4704;
BA_ "SigType" SG_ 2365400574 Jystck9GrpYAxsLvrBckNgtvPsStatus 4;
BA_ "SPN" SG_ 2365400574 Jystck9GrpYAxsLvrBckNgtvPsStatus 4703;
BA_ "SigType" SG_ 2365400574 Jystck9GripYAxisNeutralPosStatus 4;
BA_ "SPN" SG_ 2365400574 Jystck9GripYAxisNeutralPosStatus 4702;
BA_ "SPN" SG_ 2365400574 Joystick9GripXAxisPos 4701;
BA_ "SigType" SG_ 2365400574 Jystck9GrpXAxsLvrRghtPstvPsSttus 4;
BA_ "SPN" SG_ 2365400574 Jystck9GrpXAxsLvrRghtPstvPsSttus 4700;
BA_ "SigType" SG_ 2365400574 Jystck9GrpXAxsLvrLftNgtvPsStatus 4;
BA_ "SPN" SG_ 2365400574 Jystck9GrpXAxsLvrLftNgtvPsStatus 4699;
BA_ "SigType" SG_ 2365400574 Jystck9GripXAxisNeutralPosStatus 4;
BA_ "SPN" SG_ 2365400574 Jystck9GripXAxisNeutralPosStatus 4698;
BA_ "SigType" SG_ 2365401086 Jystick8GripXAxisDetentPosStatus 4;
BA_ "SPN" SG_ 2365401086 Jystick8GripXAxisDetentPosStatus 4675;
BA_ "SigType" SG_ 2365401086 Jystick8GripYAxisDetentPosStatus 4;
BA_ "SPN" SG_ 2365401086 Jystick8GripYAxisDetentPosStatus 4674;
BA_ "SigType" SG_ 2365401086 Jystick8ThetaAxisDetentPosStatus 4;
BA_ "SPN" SG_ 2365401086 Jystick8ThetaAxisDetentPosStatus 4673;
BA_ "SPN" SG_ 2365401086 Joystick8ThetaAxisPos 4672;
BA_ "SigType" SG_ 2365401086 Jystck8ThtAxsClckwsPstvPosStatus 4;
BA_ "SPN" SG_ 2365401086 Jystck8ThtAxsClckwsPstvPosStatus 4671;
BA_ "SigType" SG_ 2365401086 Jystck8ThtAxsCntrClckwsNgtvPsStt 4;
BA_ "SPN" SG_ 2365401086 Jystck8ThtAxsCntrClckwsNgtvPsStt 4670;
BA_ "SigType" SG_ 2365401086 Jystck8ThetaAxisNeutralPosStatus 4;
BA_ "SPN" SG_ 2365401086 Jystck8ThetaAxisNeutralPosStatus 4669;
BA_ "SPN" SG_ 2365401086 Joystick8GripYAxisPos 4668;
BA_ "SigType" SG_ 2365401086 Jystck8GrpYAxsLvrFrwrdPstvPsStts 4;
BA_ "SPN" SG_ 2365401086 Jystck8GrpYAxsLvrFrwrdPstvPsStts 4667;
BA_ "SigType" SG_ 2365401086 Jystck8GrpYAxsLvrBckNgtvPsStatus 4;
BA_ "SPN" SG_ 2365401086 Jystck8GrpYAxsLvrBckNgtvPsStatus 4666;
BA_ "SigType" SG_ 2365401086 Jystck8GripYAxisNeutralPosStatus 4;
BA_ "SPN" SG_ 2365401086 Jystck8GripYAxisNeutralPosStatus 4665;
BA_ "SPN" SG_ 2365401086 Joystick8GripXAxisPos 4664;
BA_ "SigType" SG_ 2365401086 Jystck8GrpXAxsLvrRghtPstvPsSttus 4;
BA_ "SPN" SG_ 2365401086 Jystck8GrpXAxsLvrRghtPstvPsSttus 4663;
BA_ "SigType" SG_ 2365401086 Jystck8GrpXAxsLvrLftNgtvPsStatus 4;
BA_ "SPN" SG_ 2365401086 Jystck8GrpXAxsLvrLftNgtvPsStatus 4662;
BA_ "SigType" SG_ 2365401086 Jystck8GripXAxisNeutralPosStatus 4;
BA_ "SPN" SG_ 2365401086 Jystck8GripXAxisNeutralPosStatus 4661;
BA_ "SigType" SG_ 2365401598 Jystick7GripXAxisDetentPosStatus 4;
BA_ "SPN" SG_ 2365401598 Jystick7GripXAxisDetentPosStatus 4638;
BA_ "SigType" SG_ 2365401598 Jystick7GripYAxisDetentPosStatus 4;
BA_ "SPN" SG_ 2365401598 Jystick7GripYAxisDetentPosStatus 4637;
BA_ "SigType" SG_ 2365401598 Jystick7ThetaAxisDetentPosStatus 4;
BA_ "SPN" SG_ 2365401598 Jystick7ThetaAxisDetentPosStatus 4636;
BA_ "SPN" SG_ 2365401598 Joystick7ThetaAxisPos 4635;
BA_ "SigType" SG_ 2365401598 Jystck7ThtAxsClckwsPstvPosStatus 4;
BA_ "SPN" SG_ 2365401598 Jystck7ThtAxsClckwsPstvPosStatus 4634;
BA_ "SigType" SG_ 2365401598 Jystck7ThtAxsCntrClckwsNgtvPsStt 4;
BA_ "SPN" SG_ 2365401598 Jystck7ThtAxsCntrClckwsNgtvPsStt 4633;
BA_ "SigType" SG_ 2365401598 Jystck7ThetaAxisNeutralPosStatus 4;
BA_ "SPN" SG_ 2365401598 Jystck7ThetaAxisNeutralPosStatus 4632;
BA_ "SPN" SG_ 2365401598 Joystick7GripYAxisPos 4631;
BA_ "SigType" SG_ 2365401598 Jystck7GrpYAxsLvrFrwrdPstvPsStts 4;
BA_ "SPN" SG_ 2365401598 Jystck7GrpYAxsLvrFrwrdPstvPsStts 4630;
BA_ "SigType" SG_ 2365401598 Jystck7GrpYAxsLvrBckNgtvPsStatus 4;
BA_ "SPN" SG_ 2365401598 Jystck7GrpYAxsLvrBckNgtvPsStatus 4629;
BA_ "SigType" SG_ 2365401598 Jystck7GripYAxisNeutralPosStatus 4;
BA_ "SPN" SG_ 2365401598 Jystck7GripYAxisNeutralPosStatus 4628;
BA_ "SPN" SG_ 2365401598 Joystick7GripXAxisPos 4627;
BA_ "SigType" SG_ 2365401598 Jystck7GrpXAxsLvrRghtPstvPsSttus 4;
BA_ "SPN" SG_ 2365401598 Jystck7GrpXAxsLvrRghtPstvPsSttus 4626;
BA_ "SigType" SG_ 2365401598 Jystck7GrpXAxsLvrLftNgtvPsStatus 4;
BA_ "SPN" SG_ 2365401598 Jystck7GrpXAxsLvrLftNgtvPsStatus 4625;
BA_ "SigType" SG_ 2365401598 Jystck7GripXAxisNeutralPosStatus 4;
BA_ "SPN" SG_ 2365401598 Jystck7GripXAxisNeutralPosStatus 4624;
BA_ "SigType" SG_ 2365402110 Jystick6GripXAxisDetentPosStatus 4;
BA_ "SPN" SG_ 2365402110 Jystick6GripXAxisDetentPosStatus 4601;
BA_ "SigType" SG_ 2365402110 Jystick6GripYAxisDetentPosStatus 4;
BA_ "SPN" SG_ 2365402110 Jystick6GripYAxisDetentPosStatus 4600;
BA_ "SigType" SG_ 2365402110 Jystick6ThetaAxisDetentPosStatus 4;
BA_ "SPN" SG_ 2365402110 Jystick6ThetaAxisDetentPosStatus 4599;
BA_ "SPN" SG_ 2365402110 Joystick6ThetaAxisPos 4598;
BA_ "SigType" SG_ 2365402110 Jystck6ThtAxsClckwsPstvPosStatus 4;
BA_ "SPN" SG_ 2365402110 Jystck6ThtAxsClckwsPstvPosStatus 4597;
BA_ "SigType" SG_ 2365402110 Jystck6ThtAxsCntrClckwsNgtvPsStt 4;
BA_ "SPN" SG_ 2365402110 Jystck6ThtAxsCntrClckwsNgtvPsStt 4596;
BA_ "SigType" SG_ 2365402110 Jystck6ThetaAxisNeutralPosStatus 4;
BA_ "SPN" SG_ 2365402110 Jystck6ThetaAxisNeutralPosStatus 4595;
BA_ "SPN" SG_ 2365402110 Joystick6GripYAxisPos 4594;
BA_ "SigType" SG_ 2365402110 Jystck6GrpYAxsLvrFrwrdPstvPsStts 4;
BA_ "SPN" SG_ 2365402110 Jystck6GrpYAxsLvrFrwrdPstvPsStts 4593;
BA_ "SigType" SG_ 2365402110 Jystck6GrpYAxsLvrBckNgtvPsStatus 4;
BA_ "SPN" SG_ 2365402110 Jystck6GrpYAxsLvrBckNgtvPsStatus 4592;
BA_ "SigType" SG_ 2365402110 Jystck6GripYAxisNeutralPosStatus 4;
BA_ "SPN" SG_ 2365402110 Jystck6GripYAxisNeutralPosStatus 4591;
BA_ "SPN" SG_ 2365402110 Joystick6GripXAxisPos 4590;
BA_ "SigType" SG_ 2365402110 Jystck6GrpXAxsLvrRghtPstvPsSttus 4;
BA_ "SPN" SG_ 2365402110 Jystck6GrpXAxsLvrRghtPstvPsSttus 4589;
BA_ "SigType" SG_ 2365402110 Jystck6GrpXAxsLvrLftNgtvPsStatus 4;
BA_ "SPN" SG_ 2365402110 Jystck6GrpXAxsLvrLftNgtvPsStatus 4588;
BA_ "SigType" SG_ 2365402110 Jystck6GripXAxisNeutralPosStatus 4;
BA_ "SPN" SG_ 2365402110 Jystck6GripXAxisNeutralPosStatus 4587;
BA_ "SigType" SG_ 2365402622 Jystick5GripXAxisDetentPosStatus 4;
BA_ "SPN" SG_ 2365402622 Jystick5GripXAxisDetentPosStatus 4564;
BA_ "SigType" SG_ 2365402622 Jystick5GripYAxisDetentPosStatus 4;
BA_ "SPN" SG_ 2365402622 Jystick5GripYAxisDetentPosStatus 4563;
BA_ "SigType" SG_ 2365402622 Jystick5ThetaAxisDetentPosStatus 4;
BA_ "SPN" SG_ 2365402622 Jystick5ThetaAxisDetentPosStatus 4562;
BA_ "SPN" SG_ 2365402622 Joystick5ThetaAxisPos 4561;
BA_ "SigType" SG_ 2365402622 Jystck5ThtAxsClckwsPstvPosStatus 4;
BA_ "SPN" SG_ 2365402622 Jystck5ThtAxsClckwsPstvPosStatus 4560;
BA_ "SigType" SG_ 2365402622 Jystck5ThtAxsCntrClckwsNgtvPsStt 4;
BA_ "SPN" SG_ 2365402622 Jystck5ThtAxsCntrClckwsNgtvPsStt 4559;
BA_ "SigType" SG_ 2365402622 Jystck5ThetaAxisNeutralPosStatus 4;
BA_ "SPN" SG_ 2365402622 Jystck5ThetaAxisNeutralPosStatus 4558;
BA_ "SPN" SG_ 2365402622 Joystick5GripYAxisPos 4557;
BA_ "SigType" SG_ 2365402622 Jystck5GrpYAxsLvrFrwrdPstvPsStts 4;
BA_ "SPN" SG_ 2365402622 Jystck5GrpYAxsLvrFrwrdPstvPsStts 4556;
BA_ "SigType" SG_ 2365402622 Jystck5GrpYAxsLvrBckNgtvPsStatus 4;
BA_ "SPN" SG_ 2365402622 Jystck5GrpYAxsLvrBckNgtvPsStatus 4555;
BA_ "SigType" SG_ 2365402622 Jystck5GripYAxisNeutralPosStatus 4;
BA_ "SPN" SG_ 2365402622 Jystck5GripYAxisNeutralPosStatus 4554;
BA_ "SPN" SG_ 2365402622 Joystick5GripXAxisPos 4553;
BA_ "SigType" SG_ 2365402622 Jystck5GrpXAxsLvrRghtPstvPsSttus 4;
BA_ "SPN" SG_ 2365402622 Jystck5GrpXAxsLvrRghtPstvPsSttus 4552;
BA_ "SigType" SG_ 2365402622 Jystck5GrpXAxsLvrLftNgtvPsStatus 4;
BA_ "SPN" SG_ 2365402622 Jystck5GrpXAxsLvrLftNgtvPsStatus 4551;
BA_ "SigType" SG_ 2365402622 Jystck5GripXAxisNeutralPosStatus 4;
BA_ "SPN" SG_ 2365402622 Jystck5GripXAxisNeutralPosStatus 4550;
BA_ "SigType" SG_ 2365403134 Jystick4GripXAxisDetentPosStatus 4;
BA_ "SPN" SG_ 2365403134 Jystick4GripXAxisDetentPosStatus 4527;
BA_ "SigType" SG_ 2365403134 Jystick4GripYAxisDetentPosStatus 4;
BA_ "SPN" SG_ 2365403134 Jystick4GripYAxisDetentPosStatus 4526;
BA_ "SigType" SG_ 2365403134 Jystick4ThetaAxisDetentPosStatus 4;
BA_ "SPN" SG_ 2365403134 Jystick4ThetaAxisDetentPosStatus 4525;
BA_ "SPN" SG_ 2365403134 Joystick4ThetaAxisPos 4524;
BA_ "SigType" SG_ 2365403134 Jystck4ThtAxsClckwsPstvPosStatus 4;
BA_ "SPN" SG_ 2365403134 Jystck4ThtAxsClckwsPstvPosStatus 4523;
BA_ "SigType" SG_ 2365403134 Jystck4ThtAxsCntrClckwsNgtvPsStt 4;
BA_ "SPN" SG_ 2365403134 Jystck4ThtAxsCntrClckwsNgtvPsStt 4522;
BA_ "SigType" SG_ 2365403134 Jystck4ThetaAxisNeutralPosStatus 4;
BA_ "SPN" SG_ 2365403134 Jystck4ThetaAxisNeutralPosStatus 4521;
BA_ "SPN" SG_ 2365403134 Joystick4GripYAxisPos 4520;
BA_ "SigType" SG_ 2365403134 Jystck4GrpYAxsLvrFrwrdPstvPsStts 4;
BA_ "SPN" SG_ 2365403134 Jystck4GrpYAxsLvrFrwrdPstvPsStts 4519;
BA_ "SigType" SG_ 2365403134 Jystck4GrpYAxsLvrBckNgtvPsStatus 4;
BA_ "SPN" SG_ 2365403134 Jystck4GrpYAxsLvrBckNgtvPsStatus 4518;
BA_ "SigType" SG_ 2365403134 Jystck4GripYAxisNeutralPosStatus 4;
BA_ "SPN" SG_ 2365403134 Jystck4GripYAxisNeutralPosStatus 4517;
BA_ "SPN" SG_ 2365403134 Joystick4GripXAxisPos 4516;
BA_ "SigType" SG_ 2365403134 Jystck4GrpXAxsLvrRghtPstvPsSttus 4;
BA_ "SPN" SG_ 2365403134 Jystck4GrpXAxsLvrRghtPstvPsSttus 4515;
BA_ "SigType" SG_ 2365403134 Jystck4GrpXAxsLvrLftNgtvPsStatus 4;
BA_ "SPN" SG_ 2365403134 Jystck4GrpXAxsLvrLftNgtvPsStatus 4514;
BA_ "SigType" SG_ 2365403134 Jystck4GripXAxisNeutralPosStatus 4;
BA_ "SPN" SG_ 2365403134 Jystck4GripXAxisNeutralPosStatus 4513;
BA_ "SigType" SG_ 2365400062 Jystck10GripXAxisDetentPosStatus 4;
BA_ "SPN" SG_ 2365400062 Jystck10GripXAxisDetentPosStatus 4749;
BA_ "SigType" SG_ 2365400062 Jystck10GripYAxisDetentPosStatus 4;
BA_ "SPN" SG_ 2365400062 Jystck10GripYAxisDetentPosStatus 4748;
BA_ "SigType" SG_ 2365400062 Jystck10ThetaAxisDetentPosStatus 4;
BA_ "SPN" SG_ 2365400062 Jystck10ThetaAxisDetentPosStatus 4747;
BA_ "SPN" SG_ 2365400062 Joystick10ThetaAxisPos 4746;
BA_ "SigType" SG_ 2365400062 Jystck10ThtAxsClckwsPstvPsStatus 4;
BA_ "SPN" SG_ 2365400062 Jystck10ThtAxsClckwsPstvPsStatus 4745;
BA_ "SigType" SG_ 2365400062 Jystck10ThtAxsCntrClckwsNgtvPsSt 4;
BA_ "SPN" SG_ 2365400062 Jystck10ThtAxsCntrClckwsNgtvPsSt 4744;
BA_ "SigType" SG_ 2365400062 Jystck10ThtaAxisNeutralPosStatus 4;
BA_ "SPN" SG_ 2365400062 Jystck10ThtaAxisNeutralPosStatus 4743;
BA_ "SPN" SG_ 2365400062 Joystick10GripYAxisPos 4742;
BA_ "SigType" SG_ 2365400062 Jystck10GrpYAxsLvrFrwrdPstvPsStt 4;
BA_ "SPN" SG_ 2365400062 Jystck10GrpYAxsLvrFrwrdPstvPsStt 4741;
BA_ "SigType" SG_ 2365400062 Jystck10GrpYAxsLvrBckNgtvPsSttus 4;
BA_ "SPN" SG_ 2365400062 Jystck10GrpYAxsLvrBckNgtvPsSttus 4740;
BA_ "SigType" SG_ 2365400062 Jystck10GrpYAxisNeutralPosStatus 4;
BA_ "SPN" SG_ 2365400062 Jystck10GrpYAxisNeutralPosStatus 4739;
BA_ "SPN" SG_ 2365400062 Joystick10GripXAxisPos 4738;
BA_ "SigType" SG_ 2365400062 Jystck10GrpXAxsLvrRghtPstvPsStts 4;
BA_ "SPN" SG_ 2365400062 Jystck10GrpXAxsLvrRghtPstvPsStts 4737;
BA_ "SigType" SG_ 2365400062 Jystck10GrpXAxsLvrLftNgtvPsSttus 4;
BA_ "SPN" SG_ 2365400062 Jystck10GrpXAxsLvrLftNgtvPsSttus 4736;
BA_ "SigType" SG_ 2365400062 Jystck10GrpXAxisNeutralPosStatus 4;
BA_ "SPN" SG_ 2365400062 Jystck10GrpXAxisNeutralPosStatus 4735;
BA_ "SigType" SG_ 2566713598 EngFuelFilterIntakeAbsPress 1;
BA_ "SPN" SG_ 2566713598 EngFuelFilterIntakeAbsPress 5417;
BA_ "SigType" SG_ 2499604478 EngExhstGsRcrcltn1OutletAbsPress 1;
BA_ "SPN" SG_ 2499604478 EngExhstGsRcrcltn1OutletAbsPress 5431;
BA_ "SigType" SG_ 2499604478 EngExhstGsRcrcltn1IntakeAbsPress 1;
BA_ "SPN" SG_ 2499604478 EngExhstGsRcrcltn1IntakeAbsPress 5430;
BA_ "SigType" SG_ 2499608830 EngCoolantPress2 1;
BA_ "SPN" SG_ 2499608830 EngCoolantPress2 5708;
BA_ "SigType" SG_ 2499608830 EngExhstGsRcrcltn2IntakeAbsPress 1;
BA_ "SPN" SG_ 2499608830 EngExhstGsRcrcltn2IntakeAbsPress 5429;
BA_ "SigType" SG_ 2499608830 EngExhstGsRcrcltn2OutletAbsPress 1;
BA_ "SPN" SG_ 2499608830 EngExhstGsRcrcltn2OutletAbsPress 5254;
BA_ "SigType" SG_ 2499608830 EngExhstGsRcrclation2IntakePress 1;
BA_ "SPN" SG_ 2499608830 EngExhstGsRcrclation2IntakePress 5253;
BA_ "SigType" SG_ 2499608830 EngExhstGsRcirculation2DiffPress 1;
BA_ "SPN" SG_ 2499608830 EngExhstGsRcirculation2DiffPress 5252;
BA_ "SigType" SG_ 2432499198 CmmndedEngFuelInjectionCtrlPress 1;
BA_ "SPN" SG_ 2432499198 CmmndedEngFuelInjectionCtrlPress 5314;
BA_ "SigType" SG_ 2432499198 CommandedEngFuelRailPress 1;
BA_ "SPN" SG_ 2432499198 CommandedEngFuelRailPress 5313;
BA_ "SigType" SG_ 2432499198 EngExhstGsRcirculation2Valve2Pos 1;
BA_ "SPN" SG_ 2432499198 EngExhstGsRcirculation2Valve2Pos 5263;
BA_ "SigType" SG_ 2432499198 EngExhstGsRecirculation2ValvePos 1;
BA_ "SPN" SG_ 2432499198 EngExhstGsRecirculation2ValvePos 5262;
BA_ "SigType" SG_ 2633825022 EngExhstGsRcrcltn2Valve2PosError 1;
BA_ "SPN" SG_ 2633825022 EngExhstGsRcrcltn2Valve2PosError 5832;
BA_ "SigType" SG_ 2633825022 EngExhstGsRcrcltn2Valve1PosError 1;
BA_ "SPN" SG_ 2633825022 EngExhstGsRcrcltn2Valve1PosError 5831;
BA_ "SigType" SG_ 2633825022 EngExhstGsRcrculation2Valve2Ctrl 1;
BA_ "SPN" SG_ 2633825022 EngExhstGsRcrculation2Valve2Ctrl 5265;
BA_ "SigType" SG_ 2633825022 EngExhstGsRcirculation2ValveCtrl 1;
BA_ "SPN" SG_ 2633825022 EngExhstGsRcirculation2ValveCtrl 5264;
BA_ "SigType" SG_ 2633826046 EGR2CoolerBypassActuatorPos 1;
BA_ "SPN" SG_ 2633826046 EGR2CoolerBypassActuatorPos 5261;
BA_ "SigType" SG_ 2633826046 EngExhstGsRcrcltn2ClerEfficiency 1;
BA_ "SPN" SG_ 2633826046 EngExhstGsRcrcltn2ClerEfficiency 5260;
BA_ "SigType" SG_ 2633826046 EngExhstGsRcrcltn2ClrIntkGsAbsPr 1;
BA_ "SPN" SG_ 2633826046 EngExhstGsRcrcltn2ClrIntkGsAbsPr 5259;
BA_ "SigType" SG_ 2633826046 EngExhstGsRcrcltn2ClerIntakeTemp 1;
BA_ "SPN" SG_ 2633826046 EngExhstGsRcrcltn2ClerIntakeTemp 5258;
BA_ "SigType" SG_ 2566711294 EngFrictionPercentTorquePoint7 1;
BA_ "GenSigStartValue" SG_ 2566711294 EngFrictionPercentTorquePoint7 125;
BA_ "SPN" SG_ 2566711294 EngFrictionPercentTorquePoint7 5477;
BA_ "SigType" SG_ 2566711294 EngFrictionPercentTorquePoint6 1;
BA_ "GenSigStartValue" SG_ 2566711294 EngFrictionPercentTorquePoint6 125;
BA_ "SPN" SG_ 2566711294 EngFrictionPercentTorquePoint6 5476;
BA_ "SigType" SG_ 2566711294 EngFrictionPercentTorquePoint5 1;
BA_ "GenSigStartValue" SG_ 2566711294 EngFrictionPercentTorquePoint5 125;
BA_ "SPN" SG_ 2566711294 EngFrictionPercentTorquePoint5 5475;
BA_ "SigType" SG_ 2566711294 EngFrictionPercentTorquePoint4 1;
BA_ "GenSigStartValue" SG_ 2566711294 EngFrictionPercentTorquePoint4 125;
BA_ "SPN" SG_ 2566711294 EngFrictionPercentTorquePoint4 5474;
BA_ "SigType" SG_ 2566711294 EngFrictionPercentTorquePoint3 1;
BA_ "GenSigStartValue" SG_ 2566711294 EngFrictionPercentTorquePoint3 125;
BA_ "SPN" SG_ 2566711294 EngFrictionPercentTorquePoint3 5473;
BA_ "SigType" SG_ 2566711294 EngFrictionPercentTorquePoint2 1;
BA_ "GenSigStartValue" SG_ 2566711294 EngFrictionPercentTorquePoint2 125;
BA_ "SPN" SG_ 2566711294 EngFrictionPercentTorquePoint2 5472;
BA_ "SigType" SG_ 2566711294 EngFrctnPrcentTorqueAtIdlePoint1 1;
BA_ "GenSigStartValue" SG_ 2566711294 EngFrctnPrcentTorqueAtIdlePoint1 125;
BA_ "SPN" SG_ 2566711294 EngFrctnPrcentTorqueAtIdlePoint1 5471;
BA_ "SigType" SG_ 2566749438 DslPrtcltFltrActvRgnrtnInhbt5629 5;
BA_ "SPN" SG_ 2566749438 DslPrtcltFltrActvRgnrtnInhbt5629 5629;
BA_ "SigType" SG_ 2566749438 DslPrtcltFltr1CndtnsNtMtFrActvRg 5;
BA_ "SPN" SG_ 2566749438 DslPrtcltFltr1CndtnsNtMtFrActvRg 3750;
BA_ "SigType" SG_ 2566749438 HydrocarbonDoserPurgingEnable 5;
BA_ "SPN" SG_ 2566749438 HydrocarbonDoserPurgingEnable 5504;
BA_ "SPN" SG_ 2566749438 DslPrtcltFltrActvRgnrtnFrcdSttus 4175;
BA_ "SPN" SG_ 2566749438 ExhaustSystemHighTempLampCmd 3698;
BA_ "SigType" SG_ 2566749438 DslPrtcltFltrAtmtcActvRgnrtnIntt 5;
BA_ "SPN" SG_ 2566749438 DslPrtcltFltrAtmtcActvRgnrtnIntt 3718;
BA_ "SigType" SG_ 2566749438 DslPrtcltFltrActvRgnrtnInhbt3717 5;
BA_ "SPN" SG_ 2566749438 DslPrtcltFltrActvRgnrtnInhbt3717 3717;
BA_ "SigType" SG_ 2566749438 DslPrtcltFltrActvRgnrtnInhbtdDTE 5;
BA_ "SPN" SG_ 2566749438 DslPrtcltFltrActvRgnrtnInhbtdDTE 3716;
BA_ "SigType" SG_ 2566749438 DslPrtcltFltrActvRgnrtnInhbt3715 4;
BA_ "SPN" SG_ 2566749438 DslPrtcltFltrActvRgnrtnInhbt3715 3715;
BA_ "SigType" SG_ 2566749438 DslPrtcltFltrActvRgnrtnInhbtdDTT 5;
BA_ "SPN" SG_ 2566749438 DslPrtcltFltrActvRgnrtnInhbtdDTT 3714;
BA_ "SigType" SG_ 2566749438 DslPrtcltFltrActvRgnrtnInhbt3713 5;
BA_ "SPN" SG_ 2566749438 DslPrtcltFltrActvRgnrtnInhbt3713 3713;
BA_ "SigType" SG_ 2566749438 DslPrtcltFltrActvRgnrtnInhbt3712 5;
BA_ "SPN" SG_ 2566749438 DslPrtcltFltrActvRgnrtnInhbt3712 3712;
BA_ "SigType" SG_ 2566749438 DslPrtcltFltrActvRgnrtnInhbtdDTL 4;
BA_ "SPN" SG_ 2566749438 DslPrtcltFltrActvRgnrtnInhbtdDTL 3711;
BA_ "SigType" SG_ 2566749438 DslPrtcltFltrActvRgnrtnInhbt3710 5;
BA_ "SPN" SG_ 2566749438 DslPrtcltFltrActvRgnrtnInhbt3710 3710;
BA_ "SigType" SG_ 2566749438 DslPrtcltFltrActvRgnrtnInhbtdDTV 5;
BA_ "SPN" SG_ 2566749438 DslPrtcltFltrActvRgnrtnInhbtdDTV 3709;
BA_ "SigType" SG_ 2566749438 DslPrtcltFltrActvRgnrtnInhbtdDTO 5;
BA_ "SPN" SG_ 2566749438 DslPrtcltFltrActvRgnrtnInhbtdDTO 3708;
BA_ "SigType" SG_ 2566749438 DslPrtcltFltrActvRgnrtnInhbtdDTA 5;
BA_ "SPN" SG_ 2566749438 DslPrtcltFltrActvRgnrtnInhbtdDTA 3707;
BA_ "SigType" SG_ 2566749438 DslPrtcltFltrActvRgnrtnInhbtdDTP 5;
BA_ "SPN" SG_ 2566749438 DslPrtcltFltrActvRgnrtnInhbtdDTP 3706;
BA_ "SigType" SG_ 2566749438 DslPrtcltFltrActvRgnrtnInhbtdDTS 5;
BA_ "SPN" SG_ 2566749438 DslPrtcltFltrActvRgnrtnInhbtdDTS 3705;
BA_ "SigType" SG_ 2566749438 DslPrtcltFltrActvRgnrtnInhbtdDTC 5;
BA_ "SPN" SG_ 2566749438 DslPrtcltFltrActvRgnrtnInhbtdDTC 3704;
BA_ "SigType" SG_ 2566749438 DslPrtcltFltrActvRgnrtnInhbtdDTI 5;
BA_ "SPN" SG_ 2566749438 DslPrtcltFltrActvRgnrtnInhbtdDTI 3703;
BA_ "SigType" SG_ 2566749438 DslPrtcltFltrActvRgnrtnInhbtdStt 5;
BA_ "SPN" SG_ 2566749438 DslPrtcltFltrActvRgnrtnInhbtdStt 3702;
BA_ "SPN" SG_ 2566749438 DieselParticulateFilterStatus 3701;
BA_ "SigType" SG_ 2566749438 DslPrtcltFltrActvRgnrationStatus 5;
BA_ "SPN" SG_ 2566749438 DslPrtcltFltrActvRgnrationStatus 3700;
BA_ "SigType" SG_ 2566749438 DslPrtcltFltrPssvRgnrationStatus 5;
BA_ "SPN" SG_ 2566749438 DslPrtcltFltrPssvRgnrationStatus 3699;
BA_ "SPN" SG_ 2566749438 DieselParticulateFilterLampCmd 3697;
BA_ "SigType" SG_ 2566715646 DslPrtculateFilter2SootSignalMin 1;
BA_ "SPN" SG_ 2566715646 DslPrtculateFilter2SootSignalMin 5271;
BA_ "SigType" SG_ 2566715646 DslPrtculateFilter2SootSignalMax 1;
BA_ "SPN" SG_ 2566715646 DslPrtculateFilter2SootSignalMax 5270;
BA_ "SigType" SG_ 2566715646 DslPrtcltFltr2StSgnlStndrdDvtion 1;
BA_ "SPN" SG_ 2566715646 DslPrtcltFltr2StSgnlStndrdDvtion 5269;
BA_ "SigType" SG_ 2566724606 DslPrtcltFltr2StSnsrECUIntrnlTmp 1;
BA_ "SPN" SG_ 2566724606 DslPrtcltFltr2StSnsrECUIntrnlTmp 5570;
BA_ "SPN" SG_ 2566724606 DslPrtcltFltr2StSnsrPrlminaryFMI 4790;
BA_ "SigType" SG_ 2566724606 DslPrtcltFilter2MedianSootSignal 1;
BA_ "SPN" SG_ 2566724606 DslPrtcltFilter2MedianSootSignal 4789;
BA_ "SigType" SG_ 2566724606 DslPrtclateFilter2MeanSootSignal 1;
BA_ "SPN" SG_ 2566724606 DslPrtclateFilter2MeanSootSignal 4788;
BA_ "SigType" SG_ 2566724606 DslParticulateFilter2SootDensity 1;
BA_ "SPN" SG_ 2566724606 DslParticulateFilter2SootDensity 4787;
BA_ "SigType" SG_ 2566724606 DieselParticulateFilter2SootMass 1;
BA_ "SPN" SG_ 2566724606 DieselParticulateFilter2SootMass 4786;
BA_ "SigType" SG_ 2566715902 DslPrtculateFilter1SootSignalMin 1;
BA_ "SPN" SG_ 2566715902 DslPrtculateFilter1SootSignalMin 5268;
BA_ "SigType" SG_ 2566715902 DslPrtculateFilter1SootSignalMax 1;
BA_ "SPN" SG_ 2566715902 DslPrtculateFilter1SootSignalMax 5267;
BA_ "SigType" SG_ 2566715902 DslPrtcltFltr1StSgnlStndrdDvtion 1;
BA_ "SPN" SG_ 2566715902 DslPrtcltFltr1StSgnlStndrdDvtion 5266;
BA_ "SigType" SG_ 2566724862 DslPrtcltFltr1StSnsrECUIntrnlTmp 1;
BA_ "SPN" SG_ 2566724862 DslPrtcltFltr1StSnsrECUIntrnlTmp 5569;
BA_ "SPN" SG_ 2566724862 DslPrtcltFltr1StSnsrPrlminaryFMI 4785;
BA_ "SigType" SG_ 2566724862 DslPrtcltFilter1MedianSootSignal 1;
BA_ "SPN" SG_ 2566724862 DslPrtcltFilter1MedianSootSignal 4784;
BA_ "SigType" SG_ 2566724862 DslPrtclateFilter1MeanSootSignal 1;
BA_ "SPN" SG_ 2566724862 DslPrtclateFilter1MeanSootSignal 4783;
BA_ "SigType" SG_ 2566724862 DslParticulateFilter1SootDensity 1;
BA_ "SPN" SG_ 2566724862 DslParticulateFilter1SootDensity 4782;
BA_ "SigType" SG_ 2566724862 DieselParticulateFilter1SootMass 1;
BA_ "SPN" SG_ 2566724862 DieselParticulateFilter1SootMass 4781;
BA_ "SigType" SG_ 2566718718 VehicleBatteryChargingLampData 4;
BA_ "SPN" SG_ 2566718718 VehicleBatteryChargingLampData 5108;
BA_ "SigType" SG_ 2566718718 VehicleHVACRecirculationLampData 4;
BA_ "SPN" SG_ 2566718718 VehicleHVACRecirculationLampData 5107;
BA_ "SigType" SG_ 2566718718 VehicleAirPressLowLampData 4;
BA_ "SPN" SG_ 2566718718 VehicleAirPressLowLampData 5106;
BA_ "SigType" SG_ 2566718718 VehicleFuelLevelLowLampData 4;
BA_ "SPN" SG_ 2566718718 VehicleFuelLevelLowLampData 5105;
BA_ "SigType" SG_ 2566718718 VehicleBatteryVoltageLowLampData 4;
BA_ "SPN" SG_ 2566718718 VehicleBatteryVoltageLowLampData 5104;
BA_ "SigType" SG_ 2566718974 EngCtrlMdule3ReadyForUseLampData 4;
BA_ "SPN" SG_ 2566718974 EngCtrlMdule3ReadyForUseLampData 6204;
BA_ "SigType" SG_ 2566718974 EngCtrlMdule2ReadyForUseLampData 4;
BA_ "SPN" SG_ 2566718974 EngCtrlMdule2ReadyForUseLampData 6203;
BA_ "SigType" SG_ 2566718974 EngCtrlMdule1ReadyForUseLampData 4;
BA_ "SPN" SG_ 2566718974 EngCtrlMdule1ReadyForUseLampData 6202;
BA_ "SigType" SG_ 2566718974 EngWaitToStartLampData 4;
BA_ "SPN" SG_ 2566718974 EngWaitToStartLampData 5416;
BA_ "SigType" SG_ 2566718974 EngFuelFilterRestrictedLampData 5;
BA_ "SPN" SG_ 2566718974 EngFuelFilterRestrictedLampData 5470;
BA_ "SigType" SG_ 2566718974 EngAirFilterRestrictionLampData 4;
BA_ "SPN" SG_ 2566718974 EngAirFilterRestrictionLampData 5103;
BA_ "SigType" SG_ 2566718974 EngIdleManagementActiveLampData 4;
BA_ "SPN" SG_ 2566718974 EngIdleManagementActiveLampData 5102;
BA_ "SigType" SG_ 2566718974 EngCoolantLevelLowLampData 4;
BA_ "SPN" SG_ 2566718974 EngCoolantLevelLowLampData 5101;
BA_ "SigType" SG_ 2566718974 EngCoolantTempHighLampData 4;
BA_ "SPN" SG_ 2566718974 EngCoolantTempHighLampData 5100;
BA_ "SigType" SG_ 2566718974 EngOilPressLowLampData 4;
BA_ "SPN" SG_ 2566718974 EngOilPressLowLampData 5099;
BA_ "SigType" SG_ 2566718974 CmprssnBrkEnblSwtchIndctrLmpData 4;
BA_ "SPN" SG_ 2566718974 CmprssnBrkEnblSwtchIndctrLmpData 5098;
BA_ "SigType" SG_ 2566718974 EngBrakeActiveLampData 4;
BA_ "SPN" SG_ 2566718974 EngBrakeActiveLampData 5097;
BA_ "SigType" SG_ 2566718974 OBDMalfunctionIndicatorLampData 4;
BA_ "SPN" SG_ 2566718974 OBDMalfunctionIndicatorLampData 5096;
BA_ "SigType" SG_ 2566718974 EngRedStopLampData 4;
BA_ "SPN" SG_ 2566718974 EngRedStopLampData 5095;
BA_ "SigType" SG_ 2566718974 EngAmberWarningLampData 4;
BA_ "SPN" SG_ 2566718974 EngAmberWarningLampData 5094;
BA_ "SigType" SG_ 2566718974 EngProtectLampData 4;
BA_ "SPN" SG_ 2566718974 EngProtectLampData 5093;
BA_ "SigType" SG_ 2566719230 VehicleBatteryChargingLampCmd 5;
BA_ "SPN" SG_ 2566719230 VehicleBatteryChargingLampCmd 5091;
BA_ "SigType" SG_ 2566719230 VehicleHVACRecirculationLampCmd 5;
BA_ "SPN" SG_ 2566719230 VehicleHVACRecirculationLampCmd 5090;
BA_ "SigType" SG_ 2566719230 VehicleAirPressLowLampCmd 5;
BA_ "SPN" SG_ 2566719230 VehicleAirPressLowLampCmd 5089;
BA_ "SigType" SG_ 2566719230 VehicleFuelLevelLowLampCmd 5;
BA_ "SPN" SG_ 2566719230 VehicleFuelLevelLowLampCmd 5088;
BA_ "SigType" SG_ 2566719230 VehicleBatteryVoltageLowLampCmd 5;
BA_ "SPN" SG_ 2566719230 VehicleBatteryVoltageLowLampCmd 5087;
BA_ "SPN" SG_ 2359492350 SPN1 1214;
BA_ "SPN" SG_ 2359492350 FailureModeIdentifier1 1215;
BA_ "SigType" SG_ 2359492350 DTCTimeUntilDerate 1;
BA_ "SPN" SG_ 2359492350 DTCTimeUntilDerate 4123;
BA_ "SigType" SG_ 2359492350 DTCTotalPreviouslyActiveTime 1;
BA_ "SPN" SG_ 2359492350 DTCTotalPreviouslyActiveTime 4122;
BA_ "SigType" SG_ 2359492350 DTCTotalActiveTime 1;
BA_ "SPN" SG_ 2359492350 DTCTotalActiveTime 4121;
BA_ "SigType" SG_ 2561212158 TextDisplayIndex 1;
BA_ "SPN" SG_ 2561212158 TextDisplayIndex 3614;
BA_ "SPN" SG_ 2561212158 TextDisplayInstructions 3613;
VAL_ 2566711550 IntkVlvActtnSystmOlPrss2SlndCtrl 3 "not available" 2 "reserved for SAE assignment" 1 "on" 0 "off" ;
VAL_ 2566711550 IntkVlvActtnSystmOlPrss1SlndCtrl 3 "not available" 2 "reserved for SAE assignment" 1 "on" 0 "off" ;
VAL_ 2566713854 EngExhstBckPrssRgltrCtrlOprtnStt 15 "Not available" 14 "Error" 5 "Uncontrolled Shutdown Active actuator current is off so it is limp" 4 "Controlled Shutdown Active driving to the default position  usually this means closed" 3 "Derate Active torque output reduced due to environmental conditions" 2 "Alarm High Severity functional but transient performance may be reduced" 1 "Alarm fully operational but needs service" 0 "Normal" ;
VAL_ 2566713854 EngExhstBckPrssRglatorTempStatus 7 "Not available" 6 "Error" 5 "Not Defined" 4 "Low Most severe" 3 "Low Least severe" 2 "In Range" 1 "High Least severe" 0 "High most severe" ;
VAL_ 2566713854 EngTrbWstgtActtr2OperationStatus 14 "Error" 5 "UnCtrlledShutdownActive" 4 "CtrlledShutdownActive" 3 "DerateActive" 2 "AlarmHighSeverity" 1 "Alarm" 0 "Normal" ;
VAL_ 2566713854 EngTrbWstgtActtr1OperationStatus 14 "Error" 5 "UnCtrlledShutdownActive" 4 "CtrlledShutdownActive" 3 "DerateActive" 2 "AlarmHighSeverity" 1 "Alarm" 0 "Normal" ;
VAL_ 2566713854 EngTrbWstgateActuator2TempStatus 7 "Not available" 6 "Error" 5 "Not Defined" 4 "Low Most severe" 3 "Low Least severe" 2 "In Range" 1 "High Least severe" 0 "High most severe" ;
VAL_ 2566714366 EngTrbCmprssrBypssActtr2OprtnStt 14 "Error" 5 "UnCtrlledShutdownActive" 4 "CtrlledShutdownActive" 3 "DerateActive" 2 "AlarmHighSeverity" 1 "Alarm" 0 "Normal" ;
VAL_ 2566714366 EngTrbCmprssrBypssActtr1OprtnStt 14 "Error" 5 "UnCtrlledShutdownActive" 4 "CtrlledShutdownActive" 3 "DerateActive" 2 "AlarmHighSeverity" 1 "Alarm" 0 "Normal" ;
VAL_ 2566714366 EngTrbCmprssrBypssActtr2TmpSttus 7 "Not available" 6 "Error" 5 "Not Defined" 4 "Low Most severe" 3 "Low Least severe" 2 "In Range" 1 "High Least severe" 0 "High most severe" ;
VAL_ 2566714110 EngFuelValve2OperationStatus 14 "Error" 5 "UnCtrlledShutdownActive" 4 "CtrlledShutdownActive" 3 "DerateActive" 2 "AlarmHighSeverity" 1 "Alarm" 0 "Normal" ;
VAL_ 2566714110 EngFuelValve1OperationStatus 14 "Error" 5 "UnCtrlledShutdownActive" 4 "CtrlledShutdownActive" 3 "DerateActive" 2 "AlarmHighSeverity" 1 "Alarm" 0 "Normal" ;
VAL_ 2566714110 EngThrottleValve2OperationStatus 14 "Error" 5 "UnCtrlledShutdownActive" 4 "CtrlledShutdownActive" 3 "DerateActive" 2 "AlarmHighSeverity" 1 "Alarm" 0 "Normal" ;
VAL_ 2566714110 EngThrottleValve1OperationStatus 15 "Not available" 14 "Error" 5 "Uncontrolled Shutdown Active actuator current is off so it is limp" 4 "Controlled Shutdown Active driving to the default position  usually this means closed" 3 "Derate Active torque output reduced due to environmental conditions" 2 "Alarm High Severity functional but transient performance may be reduced" 1 "Alarm fully operational but needs service" 0 "Normal" ;
VAL_ 2566714110 EngFuelValve2TempStatus 7 "Not available" 6 "Error" 5 "Not Defined" 4 "Low Most severe" 3 "Low Least severe" 2 "In Range" 1 "High Least severe" 0 "High most severe" ;
VAL_ 2566714110 EngFuelValve1TempStatus 7 "Not available" 6 "Error" 5 "Not Defined" 4 "Low Most severe" 3 "Low Least severe" 2 "In Range" 1 "High Least severe" 0 "High Most severe" ;
VAL_ 2566714110 EngThrottleValve2TempStatus 7 "Not available" 6 "Error" 5 "Not Defined" 4 "Low Most severe" 3 "Low Least severe" 2 "In Range" 1 "High Least severe" 0 "High Most severe" ;
VAL_ 2566714110 EngThrottleValve1TempStatus 7 "Not available" 6 "Error" 5 "Not Defined" 4 "Low Most severe" 3 "Low Least severe" 2 "In Range" 1 "High Least severe" 0 "High most severe" ;
VAL_ 2365400574 Jystick9GripXAxisDetentPosStatus 3 "Not Available" 2 "Error Indicator" 1 "In the Detent Position" 0 "Not in the Detent Position" ;
VAL_ 2365400574 Jystick9GripYAxisDetentPosStatus 3 "Not Available" 2 "Error Indicator" 1 "In the Detent Position" 0 "Not in the Detent Position" ;
VAL_ 2365400574 Jystick9ThetaAxisDetentPosStatus 3 "Not Available" 2 "Error Indicator" 1 "In the Detent Position" 0 "Not in the Detent Position" ;
VAL_ 2365400574 Jystck9ThtAxsClckwsPstvPosStatus 3 "Not Available" 2 "Error Indicator" 1 "On positive side of Neutral" 0 "Not on Positive side of Neutral" ;
VAL_ 2365400574 Jystck9ThtAxsCntrClckwsNgtvPsStt 3 "Not Available" 2 "Error Indicator" 1 "On negative side of Neutral" 0 "Not on negative side of Neutral" ;
VAL_ 2365400574 Jystck9ThetaAxisNeutralPosStatus 3 "Not Available" 2 "Error Indicator" 1 "In Neutral Position" 0 "Not in Neutral Position" ;
VAL_ 2365400574 Jystck9GrpYAxsLvrFrwrdPstvPsStts 3 "Not Available" 2 "Error Indicator" 1 "On positive side of Neutral" 0 "Not on Positive side of Neutral" ;
VAL_ 2365400574 Jystck9GrpYAxsLvrBckNgtvPsStatus 3 "Not Available" 2 "Error Indicator" 1 "On negative side of Neutral" 0 "Not on negative side of Neutral" ;
VAL_ 2365400574 Jystck9GripYAxisNeutralPosStatus 3 "Not Available" 2 "Error Indicator" 1 "In Neutral Position" 0 "Not in Neutral Position" ;
VAL_ 2365400574 Jystck9GrpXAxsLvrRghtPstvPsSttus 3 "Not Available" 2 "Error Indicator" 1 "On positive side of Neutral" 0 "Not on Positive side of Neutral" ;
VAL_ 2365400574 Jystck9GrpXAxsLvrLftNgtvPsStatus 3 "Not Available" 2 "Error Indicator" 1 "On negative side of Neutral" 0 "Not on negative side of Neutral" ;
VAL_ 2365400574 Jystck9GripXAxisNeutralPosStatus 3 "Not Available" 2 "Error Indicator" 1 "In Neutral Position" 0 "Not in Neutral Position" ;
VAL_ 2365401086 Jystick8GripXAxisDetentPosStatus 3 "Not Available" 2 "Error Indicator" 1 "In the Detent Position" 0 "Not in the Detent Position" ;
VAL_ 2365401086 Jystick8GripYAxisDetentPosStatus 3 "Not Available" 2 "Error Indicator" 1 "In the Detent Position" 0 "Not in the Detent Position" ;
VAL_ 2365401086 Jystick8ThetaAxisDetentPosStatus 3 "Not Available" 2 "Error Indicator" 1 "In the Detent Position" 0 "Not in the Detent Position" ;
VAL_ 2365401086 Jystck8ThtAxsClckwsPstvPosStatus 3 "Not Available" 2 "Error Indicator" 1 "On positive side of Neutral" 0 "Not on Positive side of Neutral" ;
VAL_ 2365401086 Jystck8ThtAxsCntrClckwsNgtvPsStt 3 "Not Available" 2 "Error Indicator" 1 "On negative side of Neutral" 0 "Not on negative side of Neutral" ;
VAL_ 2365401086 Jystck8ThetaAxisNeutralPosStatus 3 "Not Available" 2 "Error Indicator" 1 "In Neutral Position" 0 "Not in Neutral Position" ;
VAL_ 2365401086 Jystck8GrpYAxsLvrFrwrdPstvPsStts 3 "Not Available" 2 "Error Indicator" 1 "On positive side of Neutral" 0 "Not on Positive side of Neutral" ;
VAL_ 2365401086 Jystck8GrpYAxsLvrBckNgtvPsStatus 3 "Not Available" 2 "Error Indicator" 1 "On negative side of Neutral" 0 "Not on negative side of Neutral" ;
VAL_ 2365401086 Jystck8GripYAxisNeutralPosStatus 3 "Not Available" 2 "Error Indicator" 1 "In Neutral Position" 0 "Not in Neutral Position" ;
VAL_ 2365401086 Jystck8GrpXAxsLvrRghtPstvPsSttus 3 "Not Available" 2 "Error Indicator" 1 "On positive side of Neutral" 0 "Not on Positive side of Neutral" ;
VAL_ 2365401086 Jystck8GrpXAxsLvrLftNgtvPsStatus 3 "Not Available" 2 "Error Indicator" 1 "On negative side of Neutral" 0 "Not on negative side of Neutral" ;
VAL_ 2365401086 Jystck8GripXAxisNeutralPosStatus 3 "Not Available" 2 "Error Indicator" 1 "In Neutral Position" 0 "Not in Neutral Position" ;
VAL_ 2365401598 Jystick7GripXAxisDetentPosStatus 3 "Not Available" 2 "Error Indicator" 1 "In the Detent Position" 0 "Not in the Detent Position" ;
VAL_ 2365401598 Jystick7GripYAxisDetentPosStatus 3 "Not Available" 2 "Error Indicator" 1 "In the Detent Position" 0 "Not in the Detent Position" ;
VAL_ 2365401598 Jystick7ThetaAxisDetentPosStatus 3 "Not Available" 2 "Error Indicator" 1 "In the Detent Position" 0 "Not in the Detent Position" ;
VAL_ 2365401598 Jystck7ThtAxsClckwsPstvPosStatus 3 "Not Available" 2 "Error Indicator" 1 "On positive side of Neutral" 0 "Not on Positive side of Neutral" ;
VAL_ 2365401598 Jystck7ThtAxsCntrClckwsNgtvPsStt 3 "Not Available" 2 "Error Indicator" 1 "On negative side of Neutral" 0 "Not on negative side of Neutral" ;
VAL_ 2365401598 Jystck7ThetaAxisNeutralPosStatus 3 "Not Available" 2 "Error Indicator" 1 "In Neutral Position" 0 "Not in Neutral Position" ;
VAL_ 2365401598 Jystck7GrpYAxsLvrFrwrdPstvPsStts 3 "Not Available" 2 "Error Indicator" 1 "On positive side of Neutral" 0 "Not on Positive side of Neutral" ;
VAL_ 2365401598 Jystck7GrpYAxsLvrBckNgtvPsStatus 3 "Not Available" 2 "Error Indicator" 1 "On negative side of Neutral" 0 "Not on negative side of Neutral" ;
VAL_ 2365401598 Jystck7GripYAxisNeutralPosStatus 3 "Not Available" 2 "Error Indicator" 1 "In Neutral Position" 0 "Not in Neutral Position" ;
VAL_ 2365401598 Jystck7GrpXAxsLvrRghtPstvPsSttus 3 "Not Available" 2 "Error Indicator" 1 "On positive side of Neutral" 0 "Not on Positive side of Neutral" ;
VAL_ 2365401598 Jystck7GrpXAxsLvrLftNgtvPsStatus 3 "Not Available" 2 "Error Indicator" 1 "On negative side of Neutral" 0 "Not on negative side of Neutral" ;
VAL_ 2365401598 Jystck7GripXAxisNeutralPosStatus 3 "Not Available" 2 "Error Indicator" 1 "In Neutral Position" 0 "Not in Neutral Position" ;
VAL_ 2365402110 Jystick6GripXAxisDetentPosStatus 3 "Not Available" 2 "Error Indicator" 1 "In the Detent Position" 0 "Not in the Detent Position" ;
VAL_ 2365402110 Jystick6GripYAxisDetentPosStatus 3 "Not Available" 2 "Error Indicator" 1 "In the Detent Position" 0 "Not in the Detent Position" ;
VAL_ 2365402110 Jystick6ThetaAxisDetentPosStatus 3 "Not Available" 2 "Error Indicator" 1 "In the Detent Position" 0 "Not in the Detent Position" ;
VAL_ 2365402110 Jystck6ThtAxsClckwsPstvPosStatus 3 "Not Available" 2 "Error Indicator" 1 "On positive side of Neutral" 0 "Not on Positive side of Neutral" ;
VAL_ 2365402110 Jystck6ThtAxsCntrClckwsNgtvPsStt 3 "Not Available" 2 "Error Indicator" 1 "On negative side of Neutral" 0 "Not on negative side of Neutral" ;
VAL_ 2365402110 Jystck6ThetaAxisNeutralPosStatus 3 "Not Available" 2 "Error Indicator" 1 "In Neutral Position" 0 "Not in Neutral Position" ;
VAL_ 2365402110 Jystck6GrpYAxsLvrFrwrdPstvPsStts 3 "Not Available" 2 "Error Indicator" 1 "On positive side of Neutral" 0 "Not on Positive side of Neutral" ;
VAL_ 2365402110 Jystck6GrpYAxsLvrBckNgtvPsStatus 3 "Not Available" 2 "Error Indicator" 1 "On negative side of Neutral" 0 "Not on negative side of Neutral" ;
VAL_ 2365402110 Jystck6GripYAxisNeutralPosStatus 3 "Not Available" 2 "Error Indicator" 1 "In Neutral Position" 0 "Not in Neutral Position" ;
VAL_ 2365402110 Jystck6GrpXAxsLvrRghtPstvPsSttus 3 "Not Available" 2 "Error Indicator" 1 "On positive side of Neutral" 0 "Not on Positive side of Neutral" ;
VAL_ 2365402110 Jystck6GrpXAxsLvrLftNgtvPsStatus 3 "Not Available" 2 "Error Indicator" 1 "On negative side of Neutral" 0 "Not on negative side of Neutral" ;
VAL_ 2365402110 Jystck6GripXAxisNeutralPosStatus 3 "Not Available" 2 "Error Indicator" 1 "In Neutral Position" 0 "Not in Neutral Position" ;
VAL_ 2365402622 Jystick5GripXAxisDetentPosStatus 3 "Not Available" 2 "Error Indicator" 1 "In the Detent Position" 0 "Not in the Detent Position" ;
VAL_ 2365402622 Jystick5GripYAxisDetentPosStatus 3 "Not Available" 2 "Error Indicator" 1 "In the Detent Position" 0 "Not in the Detent Position" ;
VAL_ 2365402622 Jystick5ThetaAxisDetentPosStatus 3 "Not Available" 2 "Error Indicator" 1 "In the Detent Position" 0 "Not in the Detent Position" ;
VAL_ 2365402622 Jystck5ThtAxsClckwsPstvPosStatus 3 "Not Available" 2 "Error Indicator" 1 "On positive side of Neutral" 0 "Not on Positive side of Neutral" ;
VAL_ 2365402622 Jystck5ThtAxsCntrClckwsNgtvPsStt 3 "Not Available" 2 "Error Indicator" 1 "On negative side of Neutral" 0 "Not on negative side of Neutral" ;
VAL_ 2365402622 Jystck5ThetaAxisNeutralPosStatus 3 "Not Available" 2 "Error Indicator" 1 "In Neutral Position" 0 "Not in Neutral Position" ;
VAL_ 2365402622 Jystck5GrpYAxsLvrFrwrdPstvPsStts 3 "Not Available" 2 "Error Indicator" 1 "On positive side of Neutral" 0 "Not on Positive side of Neutral" ;
VAL_ 2365402622 Jystck5GrpYAxsLvrBckNgtvPsStatus 3 "Not Available" 2 "Error Indicator" 1 "On negative side of Neutral" 0 "Not on negative side of Neutral" ;
VAL_ 2365402622 Jystck5GripYAxisNeutralPosStatus 3 "Not Available" 2 "Error Indicator" 1 "In Neutral Position" 0 "Not in Neutral Position" ;
VAL_ 2365402622 Jystck5GrpXAxsLvrRghtPstvPsSttus 3 "Not Available" 2 "Error Indicator" 1 "On positive side of Neutral" 0 "Not on Positive side of Neutral" ;
VAL_ 2365402622 Jystck5GrpXAxsLvrLftNgtvPsStatus 3 "Not Available" 2 "Error Indicator" 1 "On negative side of Neutral" 0 "Not on negative side of Neutral" ;
VAL_ 2365402622 Jystck5GripXAxisNeutralPosStatus 3 "Not Available" 2 "Error Indicator" 1 "In Neutral Position" 0 "Not in Neutral Position" ;
VAL_ 2365403134 Jystick4GripXAxisDetentPosStatus 3 "Not Available" 2 "Error Indicator" 1 "In the Detent Position" 0 "Not in the Detent Position" ;
VAL_ 2365403134 Jystick4GripYAxisDetentPosStatus 3 "Not Available" 2 "Error Indicator" 1 "In the Detent Position" 0 "Not in the Detent Position" ;
VAL_ 2365403134 Jystick4ThetaAxisDetentPosStatus 3 "Not Available" 2 "Error Indicator" 1 "In the Detent Position" 0 "Not in the Detent Position" ;
VAL_ 2365403134 Jystck4ThtAxsClckwsPstvPosStatus 3 "Not Available" 2 "Error Indicator" 1 "On positive side of Neutral" 0 "Not on Positive side of Neutral" ;
VAL_ 2365403134 Jystck4ThtAxsCntrClckwsNgtvPsStt 3 "Not Available" 2 "Error Indicator" 1 "On negative side of Neutral" 0 "Not on negative side of Neutral" ;
VAL_ 2365403134 Jystck4ThetaAxisNeutralPosStatus 3 "Not Available" 2 "Error Indicator" 1 "In Neutral Position" 0 "Not in Neutral Position" ;
VAL_ 2365403134 Jystck4GrpYAxsLvrFrwrdPstvPsStts 3 "Not Available" 2 "Error Indicator" 1 "On positive side of Neutral" 0 "Not on Positive side of Neutral" ;
VAL_ 2365403134 Jystck4GrpYAxsLvrBckNgtvPsStatus 3 "Not Available" 2 "Error Indicator" 1 "On negative side of Neutral" 0 "Not on negative side of Neutral" ;
VAL_ 2365403134 Jystck4GripYAxisNeutralPosStatus 3 "Not Available" 2 "Error Indicator" 1 "In Neutral Position" 0 "Not in Neutral Position" ;
VAL_ 2365403134 Jystck4GrpXAxsLvrRghtPstvPsSttus 3 "Not Available" 2 "Error Indicator" 1 "On positive side of Neutral" 0 "Not on Positive side of Neutral" ;
VAL_ 2365403134 Jystck4GrpXAxsLvrLftNgtvPsStatus 3 "Not Available" 2 "Error Indicator" 1 "On negative side of Neutral" 0 "Not on negative side of Neutral" ;
VAL_ 2365403134 Jystck4GripXAxisNeutralPosStatus 3 "Not Available" 2 "Error Indicator" 1 "In Neutral Position" 0 "Not in Neutral Position" ;
VAL_ 2365400062 Jystck10GripXAxisDetentPosStatus 3 "Not Available" 2 "Error Indicator" 1 "In the Detent Position" 0 "Not in the Detent Position" ;
VAL_ 2365400062 Jystck10GripYAxisDetentPosStatus 3 "Not Available" 2 "Error Indicator" 1 "In the Detent Position" 0 "Not in the Detent Position" ;
VAL_ 2365400062 Jystck10ThetaAxisDetentPosStatus 3 "Not Available" 2 "Error Indicator" 1 "In the Detent Position" 0 "Not in the Detent Position" ;
VAL_ 2365400062 Jystck10ThtAxsClckwsPstvPsStatus 3 "Not Available" 2 "Error Indicator" 1 "On positive side of Neutral" 0 "Not on Positive side of Neutral" ;
VAL_ 2365400062 Jystck10ThtAxsCntrClckwsNgtvPsSt 3 "Not Available" 2 "Error Indicator" 1 "On negative side of Neutral" 0 "Not on negative side of Neutral" ;
VAL_ 2365400062 Jystck10ThtaAxisNeutralPosStatus 3 "Not Available" 2 "Error Indicator" 1 "In Neutral Position" 0 "Not in Neutral Position" ;
VAL_ 2365400062 Jystck10GrpYAxsLvrFrwrdPstvPsStt 3 "Not Available" 2 "Error Indicator" 1 "On positive side of Neutral" 0 "Not on Positive side of Neutral" ;
VAL_ 2365400062 Jystck10GrpYAxsLvrBckNgtvPsSttus 3 "Not Available" 2 "Error Indicator" 1 "On negative side of Neutral" 0 "Not on negative side of Neutral" ;
VAL_ 2365400062 Jystck10GrpYAxisNeutralPosStatus 3 "Not Available" 2 "Error Indicator" 1 "In Neutral Position" 0 "Not in Neutral Position" ;
VAL_ 2365400062 Jystck10GrpXAxsLvrRghtPstvPsStts 3 "Not Available" 2 "Error Indicator" 1 "On positive side of Neutral" 0 "Not on Positive side of Neutral" ;
VAL_ 2365400062 Jystck10GrpXAxsLvrLftNgtvPsSttus 3 "Not Available" 2 "Error Indicator" 1 "On negative side of Neutral" 0 "Not on negative side of Neutral" ;
VAL_ 2365400062 Jystck10GrpXAxisNeutralPosStatus 3 "Not Available" 2 "Error Indicator" 1 "In Neutral Position" 0 "Not in Neutral Position" ;
VAL_ 2566749438 DslPrtcltFltrActvRgnrtnInhbt5629 3 "not available" 2 "reserved for SAE assignment" 1 "inhibited" 0 "not inhibited" ;
VAL_ 2566749438 DslPrtcltFltr1CndtnsNtMtFrActvRg 3 "not available" 2 "reserved for SAE assignment" 1 "active DPF regeneration inhibited" 0 "active DPF regeneration not inhibited" ;
VAL_ 2566749438 HydrocarbonDoserPurgingEnable 3 "Not available" 2 "Purging enabled  urgent" 1 "Purging enabled  less urgent" 0 "Purging not enabled" ;
VAL_ 2566749438 DslPrtcltFltrActvRgnrtnFrcdSttus 5 "Reserved for SAE Assignment" 4 "Reserved for SAE Assignment" 7 "not available" 6 "Reserved for SAE Assignment" 2 "Active  Forced by Service Tool" 3 "Reserved for SAE Assignment" 1 "Active  Forced by Switch See SPN 3696" 0 "Not Active" ;
VAL_ 2566749438 ExhaustSystemHighTempLampCmd 7 "not available" 6 "reserved for SAE assignment" 1 "On  solid" 0 "Off" 5 "reserved for SAE assignment" 4 "reserved for SAE assignment" 3 "reserved for SAE assignment" 2 "reserved for SAE assignment" ;
VAL_ 2566749438 DslPrtcltFltrAtmtcActvRgnrtnIntt 3 "not available" 2 "reserved for SAE assignment" 1 "enabled" 0 "not enabled" ;
VAL_ 2566749438 DslPrtcltFltrActvRgnrtnInhbt3717 3 "not available" 2 "reserved for SAE assignment" 1 "inhibited" 0 "not inhibited" ;
VAL_ 2566749438 DslPrtcltFltrActvRgnrtnInhbtdDTE 3 "not available" 2 "reserved for SAE assignment" 1 "inhibited" 0 "not inhibited" ;
VAL_ 2566749438 DslPrtcltFltrActvRgnrtnInhbt3715 3 "not available" 2 "reserved for SAE assignment" 1 "inhibited" 0 "not inhibited" ;
VAL_ 2566749438 DslPrtcltFltrActvRgnrtnInhbtdDTT 3 "not available" 2 "reserved for SAE assignment" 1 "inhibited" 0 "not inhibited" ;
VAL_ 2566749438 DslPrtcltFltrActvRgnrtnInhbt3713 3 "not available" 2 "reserved for SAE assignment" 1 "inhibited" 0 "not inhibited" ;
VAL_ 2566749438 DslPrtcltFltrActvRgnrtnInhbt3712 3 "not available" 2 "reserved for SAE assignment" 1 "inhibited" 0 "not inhibited" ;
VAL_ 2566749438 DslPrtcltFltrActvRgnrtnInhbtdDTL 3 "not available" 2 "reserved for SAE assignment" 1 "inhibited" 0 "not inhibited" ;
VAL_ 2566749438 DslPrtcltFltrActvRgnrtnInhbt3710 3 "not available" 2 "reserved for SAE assignment" 1 "inhibited" 0 "not inhibited" ;
VAL_ 2566749438 DslPrtcltFltrActvRgnrtnInhbtdDTV 3 "not available" 2 "reserved for SAE assignment" 1 "inhibited" 0 "not inhibited" ;
VAL_ 2566749438 DslPrtcltFltrActvRgnrtnInhbtdDTO 3 "not available" 2 "reserved for SAE assignment" 1 "inhibited" 0 "not inhibited" ;
VAL_ 2566749438 DslPrtcltFltrActvRgnrtnInhbtdDTA 3 "not available" 2 "reserved for SAE assignment" 1 "inhibited" 0 "not inhibited" ;
VAL_ 2566749438 DslPrtcltFltrActvRgnrtnInhbtdDTP 3 "not available" 2 "reserved for SAE assignment" 1 "inhibited" 0 "not inhibited" ;
VAL_ 2566749438 DslPrtcltFltrActvRgnrtnInhbtdDTS 3 "not available" 2 "reserved for SAE assignment" 1 "inhibited" 0 "not inhibited" ;
VAL_ 2566749438 DslPrtcltFltrActvRgnrtnInhbtdDTC 3 "not available" 2 "reserved for SAE assignment" 1 "inhibited" 0 "not inhibited" ;
VAL_ 2566749438 DslPrtcltFltrActvRgnrtnInhbtdDTI 3 "not available" 2 "reserved for SAE assignment" 1 "inhibited" 0 "not inhibited" ;
VAL_ 2566749438 DslPrtcltFltrActvRgnrtnInhbtdStt 3 "not available" 2 "reserved for SAE assignment" 1 "inhibited" 0 "not inhibited" ;
VAL_ 2566749438 DieselParticulateFilterStatus 7 "not available" 6 "reserved for SAE assignment" 3 "Regeneration needed  highest level" 2 "Regeneration needed  moderate level" 1 "Regeneration needed  lowest level" 0 "Regeneration not needed" 5 "reserved for SAE assignment" 4 "reserved for SAE assignment" ;
VAL_ 2566749438 DslPrtcltFltrActvRgnrationStatus 3 "not available" 2 "regeneration needed  automatically initiated active regeneration imminent" 1 "active" 0 "not active" ;
VAL_ 2566749438 DslPrtcltFltrPssvRgnrationStatus 3 "not available" 2 "reserved for SAE assignment" 1 "active" 0 "not active" ;
VAL_ 2566749438 DieselParticulateFilterLampCmd 7 "not available" 4 "On  fast blink 1 HZ" 6 "reserved for SAE assignment" 1 "On  solid" 0 "Off" 5 "reserved for SAE assignment" 3 "reserved for SAE assignment" 2 "reserved for SAE assignment" ;
VAL_ 2566718718 VehicleBatteryChargingLampData 3 "Not available" 2 "Error" 1 "Lamp activated On" 0 "Lamp deactivated Off" ;
VAL_ 2566718718 VehicleHVACRecirculationLampData 3 "Not available" 2 "Error" 1 "Lamp activated On" 0 "Lamp deactivated Off" ;
VAL_ 2566718718 VehicleAirPressLowLampData 3 "Not available" 2 "Error" 1 "Lamp activated On" 0 "Lamp deactivated Off" ;
VAL_ 2566718718 VehicleFuelLevelLowLampData 3 "Not available" 2 "Error" 1 "Lamp activated On" 0 "Lamp deactivated Off" ;
VAL_ 2566718718 VehicleBatteryVoltageLowLampData 3 "Not available" 2 "Error" 1 "Lamp activated On" 0 "Lamp deactivated Off" ;
VAL_ 2566718974 EngCtrlMdule3ReadyForUseLampData 3 "Not Available" 2 "Error" 1 "Lamp activated (On)" 0 "Lamp deactivated (Off)" ;
VAL_ 2566718974 EngCtrlMdule2ReadyForUseLampData 3 "Not Available" 2 "Error" 1 "Lamp activated (On)" 0 "Lamp deactivated (Off)" ;
VAL_ 2566718974 EngCtrlMdule1ReadyForUseLampData 3 "Not Available" 2 "Error" 1 "Lamp activated (On)" 0 "Lamp deactivated (Off)" ;
VAL_ 2566718974 EngWaitToStartLampData 3 "Not available" 2 "Error" 1 "Lamp active" 0 "Lamp deactive" ;
VAL_ 2566718974 EngFuelFilterRestrictedLampData 3 "Not available" 2 "Error" 1 "Lamp activated On" 0 "Lamp deactivated Off" ;
VAL_ 2566718974 EngAirFilterRestrictionLampData 3 "Not available" 2 "Error" 1 "Lamp activated On" 0 "Lamp deactivated Off" ;
VAL_ 2566718974 EngIdleManagementActiveLampData 3 "Not available" 2 "Error" 1 "Lamp activated On" 0 "Lamp deactivated Off" ;
VAL_ 2566718974 EngCoolantLevelLowLampData 3 "Not available" 2 "Error" 1 "Lamp activated On" 0 "Lamp deactivated Off" ;
VAL_ 2566718974 EngCoolantTempHighLampData 3 "Not available" 2 "Error" 1 "Lamp activated On" 0 "Lamp deactivated Off" ;
VAL_ 2566718974 EngOilPressLowLampData 3 "Not available" 2 "Error" 1 "Lamp activated On" 0 "Lamp deactivated Off" ;
VAL_ 2566718974 CmprssnBrkEnblSwtchIndctrLmpData 3 "Not available" 2 "Error" 1 "Lamp activated On" 0 "Lamp deactivated Off" ;
VAL_ 2566718974 EngBrakeActiveLampData 3 "Not available" 2 "Error" 1 "Lamp activated On" 0 "Lamp deactivated Off" ;
VAL_ 2566718974 OBDMalfunctionIndicatorLampData 3 "Not available" 2 "Error" 1 "Lamp activated On" 0 "Lamp deactivated Off" ;
VAL_ 2566718974 EngRedStopLampData 3 "Not available" 2 "Error" 1 "Lamp activated On" 0 "Lamp deactivated Off" ;
VAL_ 2566718974 EngAmberWarningLampData 3 "Not available" 2 "Error" 1 "Lamp activated On" 0 "Lamp deactivated Off" ;
VAL_ 2566718974 EngProtectLampData 3 "Not available" 2 "Error" 1 "Lamp activated On" 0 "Lamp deactivated Off" ;
VAL_ 2566719230 VehicleBatteryChargingLampCmd 3 "Not available" 2 "Reserved" 1 "Lamp On" 0 "Lamp Off" ;
VAL_ 2566719230 VehicleHVACRecirculationLampCmd 3 "Not available" 2 "Reserved" 1 "Lamp On" 0 "Lamp Off" ;
VAL_ 2566719230 VehicleAirPressLowLampCmd 3 "Not available" 2 "Reserved" 1 "Lamp On" 0 "Lamp Off" ;
VAL_ 2566719230 VehicleFuelLevelLowLampCmd 3 "Not available" 2 "Reserved" 1 "Lamp On" 0 "Lamp Off" ;
VAL_ 2566719230 VehicleBatteryVoltageLowLampCmd 3 "Not available" 2 "Reserved" 1 "Lamp On" 0 "Lamp Off" ;
VAL_ 2359492350 FailureModeIdentifier1 31 "Not available" 19 "Received network data in error" 18 "Below normal (moderately severe)" 17 "Below normal (least severe)" 16 "Above normal (moderately severe)" 15 "Above normal (least severe)" 14 "Special intstructions" 13 "Out of calibration" 12 "Bad intelligent device" 11 "Root cause not known" 10 "Abnormal rate of change" 9 "Abnormal update rate" 8 "Abnormal frequency" 7 "Mechanical system not responding" 6 "Current above normal" 5 "Current below normal" 4 "Voltage below normal" 3 "Voltage above normal" 2 "Data erratic" 1 "Below normal (most severe)" 0 "Above normal (most severe)" ;
VAL_ 2561212158 TextDisplayInstructions 6 "Blink substring" 15 "Not applicable" 1 "Hold display  The presently displayed information should be retained" 0 "Clear display  The displayed information should be deleted or not displayed any more" 5 "Highlight substring" 4 "Overwrite substring  A portion of the presently displayed information is to be overwritten with the transmitted" 3 "Overwrite display  The presently displayed information is to be overwritten with the transmitted information" 2 "Append at end of display  The transmitted information should be displayed at the end of the presently displayed" ;
